VERSION ""

NS_ :

BS_:

BU_: XXX

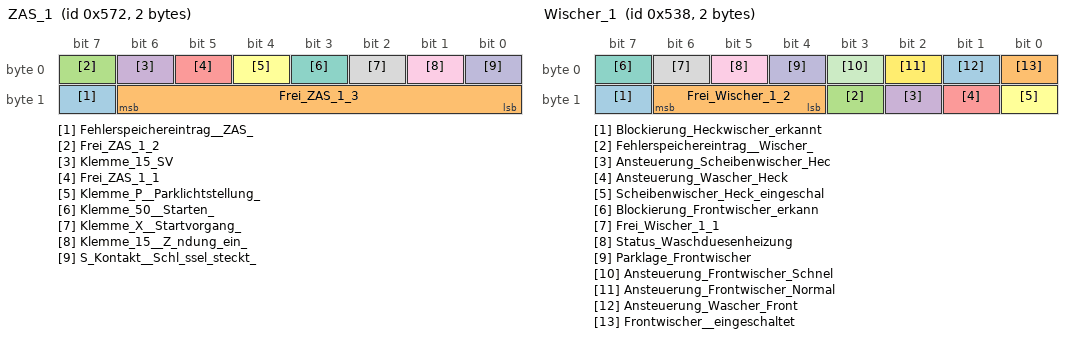
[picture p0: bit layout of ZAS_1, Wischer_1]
BO_ 1394 ZAS_1: 2 XXX
 SG_ Fehlerspeichereintrag__ZAS_ : 15|1@1+ (1,0) [0|0] "" XXX
 SG_ Frei_ZAS_1_3 : 8|7@1+ (1,0) [0|0] "" XXX
 SG_ Frei_ZAS_1_2 : 7|1@1+ (1,0) [0|0] "" XXX
 SG_ Klemme_15_SV : 6|1@1+ (1,0) [0|0] "" XXX
 SG_ Frei_ZAS_1_1 : 5|1@1+ (1,0) [0|0] "" XXX
 SG_ Klemme_P__Parklichtstellung_ : 4|1@1+ (1,0) [0|0] "" XXX
 SG_ Klemme_50__Starten_ : 3|1@1+ (1,0) [0|0] "" XXX
 SG_ Klemme_X__Startvorgang_ : 2|1@1+ (1,0) [0|0] "" XXX
 SG_ Klemme_15__Z_ndung_ein_ : 1|1@1+ (1,0) [0|0] "" XXX
 SG_ S_Kontakt__Schl_ssel_steckt_ : 0|1@1+ (1,0) [0|0] "" XXX

BO_ 1336 Wischer_1: 2 XXX
 SG_ Blockierung_Heckwischer_erkannt : 15|1@1+ (1,0) [0|0] "" XXX
 SG_ Frei_Wischer_1_2 : 12|3@1+ (1,0) [0|0] "" XXX
 SG_ Fehlerspeichereintrag__Wischer_ : 11|1@1+ (1,0) [0|0] "" XXX
 SG_ Ansteuerung_Scheibenwischer_Hec : 10|1@1+ (1,0) [0|0] "" XXX
 SG_ Ansteuerung_Wascher_Heck : 9|1@1+ (1,0) [0|0] "" XXX
 SG_ Scheibenwischer_Heck_eingeschal : 8|1@1+ (1,0) [0|0] "" XXX
 SG_ Blockierung_Frontwischer_erkann : 7|1@1+ (1,0) [0|0] "" XXX
 SG_ Frei_Wischer_1_1 : 6|1@1+ (1,0) [0|0] "" XXX
 SG_ Status_Waschduesenheizung : 5|1@1+ (1,0) [0|0] "" XXX
 SG_ Parklage_Frontwischer : 4|1@1+ (1,0) [0|0] "" XXX
 SG_ Ansteuerung_Frontwischer_Schnel : 3|1@1+ (1,0) [0|0] "" XXX
 SG_ Ansteuerung_Frontwischer_Normal : 2|1@1+ (1,0) [0|0] "" XXX
 SG_ Ansteuerung_Wascher_Front : 1|1@1+ (1,0) [0|0] "" XXX
 SG_ Frontwischer__eingeschaltet : 0|1@1+ (1,0) [0|0] "" XXX

BO_ 1464 WFS_1: 2 XXX
 SG_ WFS_Textbits : 8|8@1+ (1,0) [0|0] "" XXX
 SG_ Frei_WFS_1_1 : 1|7@1+ (1,0) [0|0] "" XXX
 SG_ WFS_LED : 0|1@1+ (1,0) [0|0] "" XXX

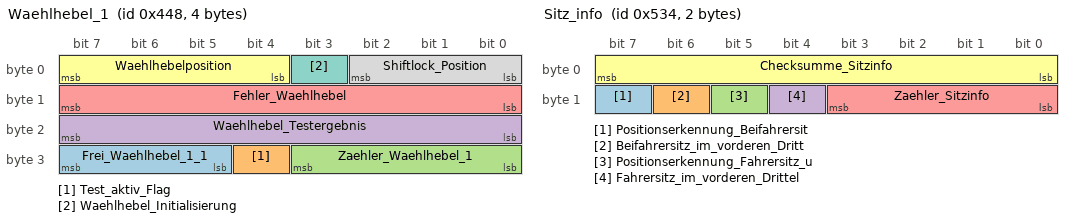
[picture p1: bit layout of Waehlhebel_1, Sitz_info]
BO_ 1096 Waehlhebel_1: 4 XXX
 SG_ Frei_Waehlhebel_1_1 : 29|3@1+ (1,0) [0|0] "" XXX
 SG_ Test_aktiv_Flag : 28|1@1+ (1,0) [0|0] "" XXX
 SG_ Zaehler_Waehlhebel_1 : 24|4@1+ (1,0) [0|15] "" XXX
 SG_ Waehlhebel_Testergebnis : 16|8@1+ (1,0) [0|255] "" XXX
 SG_ Fehler_Waehlhebel : 8|8@1+ (1,0) [0|0] "" XXX
 SG_ Waehlhebelposition : 4|4@1+ (1,0) [0|0] "" XXX
 SG_ Waehlhebel_Initialisierung : 3|1@1+ (1,0) [0|0] "" XXX
 SG_ Shiftlock_Position : 0|3@1+ (1,0) [0|0] "" XXX

BO_ 1496 Verbauliste_1: 8 XXX
 SG_ TV_Tuner : 63|1@1+ (1,0) [0|0] "" XXX
 SG_ DSP : 62|1@1+ (1,0) [0|0] "" XXX
 SG_ CD_Wechsler : 61|1@1+ (1,0) [0|0] "" XXX
 SG_ Spracheingabe : 60|1@1+ (1,0) [0|0] "" XXX
 SG_ Telematik : 59|1@1+ (1,0) [0|0] "" XXX
 SG_ Navigation : 58|1@1+ (1,0) [0|0] "" XXX
 SG_ Telefon : 57|1@1+ (1,0) [0|0] "" XXX
 SG_ Radio : 56|1@1+ (1,0) [0|0] "" XXX
 SG_ MMI_vorne : 55|1@1+ (1,0) [0|0] "" XXX
 SG_ MMI_hinten : 54|1@1+ (1,0) [0|0] "" XXX
 SG_ Frei_Verbauliste_1_11 : 53|1@1+ (1,0) [0|0] "" XXX
 SG_ Klimabedienteil_HL : 52|1@1+ (1,0) [0|0] "" XXX
 SG_ Frei_Verbauliste_1_10 : 50|2@1+ (1,0) [0|0] "" XXX
 SG_ Tankgeber : 49|1@1+ (1,0) [0|0] "" XXX
 SG_ Assistenzfahrlicht : 48|1@1+ (1,0) [0|0] "" XXX
 SG_ Memory_hinter_Fahrer : 47|1@1+ (1,0) [0|0] "" XXX
 SG_ Sitzmemory_hinten : 46|1@1+ (1,0) [0|0] "" XXX
 SG_ Sitzmemory_Beifahrer : 45|1@1+ (1,0) [0|0] "" XXX
 SG_ Anh_ngersteuergeraet : 44|1@1+ (1,0) [0|0] "" XXX
 SG_ Energiemanagement : 43|1@1+ (1,0) [0|0] "" XXX
 SG_ Wischermodul : 42|1@1+ (1,0) [0|0] "" XXX
 SG_ EZS___Kessy__Komfort_ : 41|1@1+ (1,0) [0|0] "" XXX
 SG_ Verdecksteuergeraet : 40|1@1+ (1,0) [0|0] "" XXX
 SG_ Standheizung : 39|1@1+ (1,0) [0|0] "" XXX
 SG_ Frei_Verbauliste_1_9 : 38|1@1+ (1,0) [0|0] "" XXX
 SG_ Einparkhilfe : 37|1@1+ (1,0) [0|0] "" XXX
 SG_ Klimasteuergeraet_Komfort : 36|1@1+ (1,0) [0|0] "" XXX
 SG_ Gateway : 35|1@1+ (1,0) [0|0] "" XXX
 SG_ Lenksaeulenmodul : 34|1@1+ (1,0) [0|0] "" XXX
 SG_ Reifendruck : 33|1@1+ (1,0) [0|0] "" XXX
 SG_ Kombiinstrument_Komfort : 32|1@1+ (1,0) [0|0] "" XXX
 SG_ Dachmodul : 31|1@1+ (1,0) [0|0] "" XXX
 SG_ Memory : 30|1@1+ (1,0) [0|0] "" XXX
 SG_ TSG_HR : 29|1@1+ (1,0) [0|0] "" XXX
 SG_ TSG_HL : 28|1@1+ (1,0) [0|0] "" XXX
 SG_ TSG_BT : 27|1@1+ (1,0) [0|0] "" XXX
 SG_ TSG_FT : 26|1@1+ (1,0) [0|0] "" XXX
 SG_ ZKE : 25|1@1+ (1,0) [0|0] "" XXX
 SG_ BSG_Komfort : 24|1@1+ (1,0) [0|0] "" XXX
 SG_ Frei_Verbauliste_1_8 : 19|5@1+ (1,0) [0|0] "" XXX
 SG_ Stabi_Entkopplung : 18|1@1+ (1,0) [0|0] "" XXX
 SG_ Waehlhebel : 17|1@1+ (1,0) [0|0] "" XXX
 SG_ Batteriemanager : 16|1@1+ (1,0) [0|0] "" XXX
 SG_ Daempfer_SG : 15|1@1+ (1,0) [0|0] "" XXX
 SG_ Niveauregulierung : 14|1@1+ (1,0) [0|0] "" XXX
 SG_ EZS___Kessy__Antrieb_ : 13|1@1+ (1,0) [0|0] "" XXX
 SG_ Bremsbooster : 12|1@1+ (1,0) [0|0] "" XXX
 SG_ Lenkhilfe : 11|1@1+ (1,0) [0|0] "" XXX
 SG_ Kombi_Antrieb : 10|1@1+ (1,0) [0|0] "" XXX
 SG_ Einspritzpumpe : 9|1@1+ (1,0) [0|0] "" XXX
 SG_ Lenkwinkel : 8|1@1+ (1,0) [0|0] "" XXX
 SG_ Allrad : 7|1@1+ (1,0) [0|0] "" XXX
 SG_ BSG_Antrieb : 6|1@1+ (1,0) [0|0] "" XXX
 SG_ ADR : 5|1@1+ (1,0) [0|0] "" XXX
 SG_ Airbag : 4|1@1+ (1,0) [0|0] "" XXX
 SG_ Climatronic_Antrieb : 3|1@1+ (1,0) [0|0] "" XXX
 SG_ ABS : 2|1@1+ (1,0) [0|0] "" XXX
 SG_ Getriebesteuergeraet : 1|1@1+ (1,0) [0|0] "" XXX
 SG_ Motorsteuergeraet : 0|1@1+ (1,0) [0|0] "" XXX

BO_ 1488 Systeminfo_1: 6 XXX
 SG_ CAN_Stand_4_1_Antrieb_Daten_Hau : 44|4@1+ (1,0) [0|15] "" XXX
 SG_ CAN_Stand_4_1_Antrieb_Daten_Neb : 40|4@1+ (1,0) [0|15] "" XXX
 SG_ CAN_Stand_4_1_Komfort_Daten_Hau : 36|4@1+ (1,0) [0|15] "" XXX
 SG_ CAN_Stand_4_1_Komfort_Daten_Neb : 32|4@1+ (1,0) [0|15] "" XXX
 SG_ Frei_Systeminfo_1_6 : 30|1@1+ (1,0) [0|0] "" XXX
 SG_ Viertuerer : 29|1@1+ (1,0) [0|0] "" XXX
 SG_ Rechtslenker : 28|1@1+ (1,0) [0|0] "" XXX
 SG_ Fahrzeug_Index : 24|4@1+ (1,0) [0|0] "" XXX
 SG_ Fahrzeug_Generation : 20|4@1+ (1,0) [0|15] "" XXX
 SG_ Fahrzeug_Derivat : 16|4@1+ (1,0) [0|15] "" XXX
 SG_ Fahrzeug_Marke_2 : 12|4@1+ (1,0) [0|15] "" XXX
 SG_ Fahrzeug_Klasse : 8|4@1+ (1,0) [0|15] "" XXX
 SG_ Verbauinformation_gueltig : 7|1@1+ (1,0) [0|0] "" XXX
 SG_ CAN_Infotainment_verbaut : 6|1@1+ (1,0) [0|0] "" XXX
 SG_ CAN_Infotainment_in_Diagnose : 5|1@1+ (1,0) [0|0] "" XXX
 SG_ Sleep_CAN_Infotainment : 4|1@1+ (1,0) [0|0] "" XXX
 SG_ CAN_Komfort_in_Diagnose : 3|1@1+ (1,0) [0|0] "" XXX
 SG_ Sleep_CAN_Komfort : 2|1@1+ (1,0) [0|0] "" XXX
 SG_ CAN_Antrieb_in_Diagnose : 1|1@1+ (1,0) [0|0] "" XXX
 SG_ CAN_Extern_zugeschaltet : 0|1@1+ (1,0) [0|0] "" XXX

BO_ 268 Slave_1: 8 XXX
 SG_ Delta_reduziertes_Sollmoment : 48|1@1+ (1,0) [0|0] "" XXX
 SG_ Delta_Drosselklappenwinkel : 32|16@1+ (1,0) [0|0] "" XXX
 SG_ Frei_Slave_1_1 : 25|7@1+ (1,0) [0|0] "" XXX
 SG_ Delta_Zuendwinkelausgabe : 24|1@1+ (1,0) [0|0] "" XXX
 SG_ Ubat_Freigabe_DVE__Slave_ : 23|1@1+ (1,0) [0|0] "" XXX
 SG_ Drosselklappe_Sollwertbegrenzun : 22|1@1+ (1,0) [0|0] "" XXX
 SG_ Einspritzverbot_lernen__Slave_ : 21|1@1+ (1,0) [0|0] "" XXX
 SG_ Master_erkannt__Slave_ : 20|1@1+ (1,0) [0|0] "" XXX
 SG_ Fehler_Momentenausgabe : 19|1@1+ (1,0) [0|0] "" XXX
 SG_ Fehler_Getriebe_Moment : 18|1@1+ (1,0) [0|0] "" XXX
 SG_ Fehler_Bremsenbotschaft : 17|1@1+ (1,0) [0|0] "" XXX
 SG_ Indiziertes_Istmoment__Slave_ : 0|16@1+ (0.0015259,0) [0|99.998] "%" XXX
 SG_ Timeout_Bremsenbotschaft : 0|1@1+ (1,0) [0|0] "" XXX

BO_ 1332 Sitz_info: 2 XXX
 SG_ Positionserkennung_Beifahrersit : 15|1@1+ (1,0) [0|0] "" XXX
 SG_ Beifahrersitz_im_vorderen_Dritt : 14|1@1+ (1,0) [0|0] "" XXX
 SG_ Positionserkennung_Fahrersitz_u : 13|1@1+ (1,0) [0|0] "" XXX
 SG_ Fahrersitz_im_vorderen_Drittel : 12|1@1+ (1,0) [0|0] "" XXX
 SG_ Zaehler_Sitzinfo : 8|4@1+ (1,0) [0|15] "" XXX
 SG_ Checksumme_Sitzinfo : 0|8@1+ (1,0) [0|0] "" XXX

BO_ 1810 PSG_3: 2 XXX
 SG_ Selbsttestergebnis : 0|16@1+ (1,0) [0|0] "" XXX

BO_ 1298 PSG_2: 8 XXX
 SG_ RAM_Inhalt_4 : 48|16@1+ (1,0) [0|0] "" XXX
 SG_ RAM_Inhalt_3 : 32|16@1+ (1,0) [0|0] "" XXX
 SG_ RAM_Inhalt_2 : 16|16@1+ (1,0) [0|0] "" XXX
 SG_ RAM_Inhalt_1 : 0|16@1+ (1,0) [0|0] "" XXX

BO_ 274 PSG_1: 8 XXX
 SG_ Pumpentemperatur__2_1_ : 48|16@1+ (0.0625,0) [0|4096] "K" XXX
 SG_ Pumpentemperatur__3_2_2_ : 44|12@1+ (1,0) [0|0] "" XXX
 SG_ Zylinderzaehler__3_2_2_ : 43|3@1+ (1,0) [1|8] "Zaehler" XXX
 SG_ Ansteuerdauer__3_2_2_ : 32|11@1+ (0.0469,0) [0|96] "NW" XXX
 SG_ Nockenwellendrehzahl__3_2_2_ : 20|12@1+ (4,0) [0|16380] "upm" XXX
 SG_ Pumpen_Statuswort__3_2_2_ : 0|20@1+ (1,0) [0|0] "" XXX

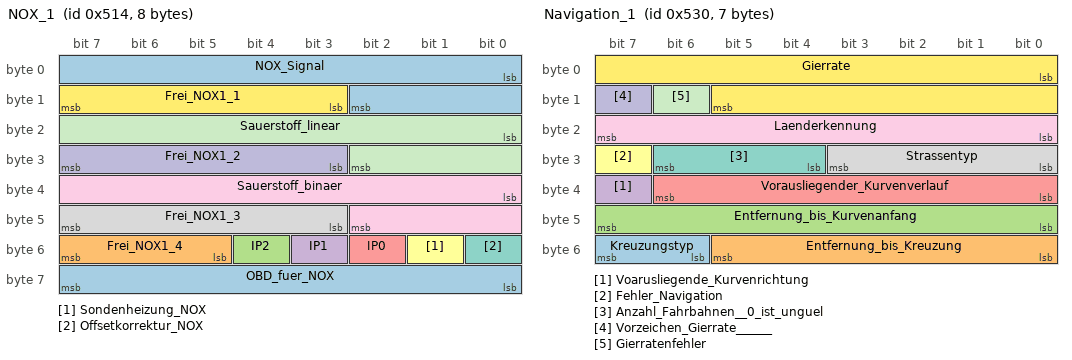
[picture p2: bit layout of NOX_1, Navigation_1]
BO_ 1300 NOX_1: 8 XXX
 SG_ OBD_fuer_NOX : 56|8@1+ (1,0) [0|0] "" XXX
 SG_ Frei_NOX1_4 : 53|3@1+ (1,0) [0|0] "" XXX
 SG_ IP2 : 52|1@1+ (1,0) [0|0] "" XXX
 SG_ IP1 : 51|1@1+ (1,0) [0|0] "" XXX
 SG_ IP0 : 50|1@1+ (1,0) [0|0] "" XXX
 SG_ Sondenheizung_NOX : 49|1@1+ (1,0) [0|0] "" XXX
 SG_ Offsetkorrektur_NOX : 48|1@1+ (1,0) [0|0] "" XXX
 SG_ Frei_NOX1_3 : 43|5@1+ (1,0) [0|0] "" XXX
 SG_ Sauerstoff_binaer : 32|11@1+ (1,-200) [-200|1847] "mV" XXX
 SG_ Frei_NOX1_2 : 27|5@1+ (1,0) [0|0] "" XXX
 SG_ Sauerstoff_linear : 16|11@1+ (1,0) [0|2047] "1000/Lambd" XXX
 SG_ Frei_NOX1_1 : 11|5@1+ (1,0) [0|0] "" XXX
 SG_ NOX_Signal : 0|11@1+ (1,0) [0|2047] "ppm" XXX

BO_ 1424 Niveau_1: 6 XXX
 SG_ Beladungszustand : 40|8@1+ (1,0) [0|253] "Zuladung" XXX
 SG_ Fehlerspeichereintrag__Niveau_1 : 39|1@1+ (1,0) [0|0] "" XXX
 SG_ Systemstatus__Niveau_1_ : 38|1@1+ (1,0) [0|0] "" XXX
 SG_ Reserve_Fahrzeugart : 37|1@1+ (1,0) [0|0] "" XXX
 SG_ Fahrzeugart_Niveau : 36|1@1+ (1,0) [0|0] "" XXX
 SG_ Textbits__Niveau_1_ : 32|4@1+ (1,0) [0|0] "" XXX
 SG_ Verstellung_HL : 31|1@1+ (1,0) [0|0] "" XXX
 SG_ Verstellung_HR : 30|1@1+ (1,0) [0|0] "" XXX
 SG_ Verstellung_VL : 29|1@1+ (1,0) [0|0] "" XXX
 SG_ Verstellung_VR : 28|1@1+ (1,0) [0|0] "" XXX
 SG_ Absenkung_Fahrzeug : 27|1@1+ (1,0) [0|0] "" XXX
 SG_ Anhebung_Fahrzeug : 26|1@1+ (1,0) [0|0] "" XXX
 SG_ Verstellung_aktiv : 25|1@1+ (1,0) [0|0] "" XXX
 SG_ Kompressorlauf_in_Kuerze : 24|1@1+ (1,0) [0|0] "" XXX
 SG_ Frei_Niveau_1_5 : 23|1@1+ (1,0) [0|0] "" XXX
 SG_ Taster_Niveau : 22|1@1+ (1,0) [0|0] "" XXX
 SG_ Parkniveau : 21|1@1+ (1,0) [0|0] "" XXX
 SG_ Zwischenniveau : 20|1@1+ (1,0) [0|0] "" XXX
 SG_ Niveaustati : 16|4@1+ (1,0) [0|0] "" XXX
 SG_ MSG_Einschraenkung : 15|1@1+ (1,0) [0|0] "" XXX
 SG_ ESP_Beeinflussung : 14|1@1+ (1,0) [0|0] "" XXX
 SG_ Warnlampe_Niveau_1 : 13|1@1+ (1,0) [0|0] "" XXX
 SG_ Frei_Niveau_1_1 : 12|1@1+ (1,0) [0|0] "" XXX
 SG_ Zaehler_Niveau_1 : 8|4@1+ (1,0) [0|15] "Zaehler" XXX
 SG_ Checksumme_Niveau_1 : 0|8@1+ (1,0) [0|0] "" XXX

BO_ 1328 Navigation_1: 7 XXX
 SG_ Kreuzungstyp : 54|2@1+ (1,0) [0|3] "" XXX
 SG_ Entfernung_bis_Kreuzung : 48|6@1+ (5,0) [0|315] "m" XXX
 SG_ Entfernung_bis_Kurvenanfang : 40|8@1+ (1,0) [0|255] "m" XXX
 SG_ Voarusliegende_Kurvenrichtung : 39|1@1+ (1,0) [0|0] "" XXX
 SG_ Vorausliegender_Kurvenverlauf : 32|7@1+ (50,0) [0|6350] "m" XXX
 SG_ Fehler_Navigation : 31|1@1+ (1,0) [0|0] "" XXX
 SG_ Anzahl_Fahrbahnen__0_ist_unguel : 28|3@1+ (1,0) [1|7] "" XXX
 SG_ Strassentyp : 24|4@1+ (1,0) [0|15] "" XXX
 SG_ Laenderkennung : 16|8@1+ (1,0) [0|0] "" XXX
 SG_ Vorzeichen_Gierrate______ : 15|1@1+ (1,0) [0|0] "" XXX
 SG_ Gierratenfehler : 14|1@1+ (1,0) [0|0] "" XXX
 SG_ Gierrate : 0|14@1+ (0.01,0) [0|100] "deg/sek" XXX

BO_ 1792 MSG_3: 3 XXX
 SG_ MSG_Konfiguration : 16|8@1+ (1,0) [0|0] "" XXX
 SG_ Lage_des_OT_Impuls : 0|16@1+ (0.01172,-384) [-384|384] "KW" XXX

BO_ 1280 MSG_2: 8 XXX
 SG_ RAM_Adresse_4 : 48|16@1+ (1,0) [0|0] "" XXX
 SG_ RAM_Adresse_3 : 32|16@1+ (1,0) [0|0] "" XXX
 SG_ RAM_Adresse_2 : 16|16@1+ (1,0) [0|0] "" XXX
 SG_ Ram_Adresse_1 : 0|16@1+ (1,0) [0|0] "" XXX

BO_ 256 MSG_1: 8 XXX
 SG_ Kurbelwellendrehzahl__3_2_2_ : 56|8@1+ (1,0) [0|0] "" XXX
 SG_ Soll_Foerderbeginn_KW__3_2_2_ : 40|16@1+ (0.01172,-384) [-384|384] "KW" XXX
 SG_ Soll_Foerderbeginn_NW__3_2_2_ : 28|12@1+ (0.01172,0) [0|768] "degNW" XXX
 SG_ Soll_Voreinspritzung : 16|12@1+ (1,0) [0|0] "" XXX
 SG_ Soll_Einspritzmenge : 0|16@1+ (0.03125,0) [0|2047] "mg/H" XXX

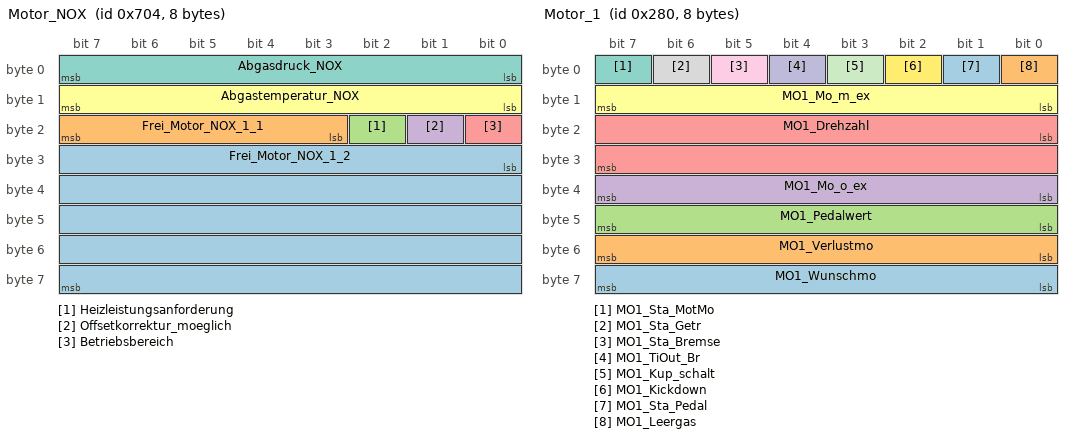
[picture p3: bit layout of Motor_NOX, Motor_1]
BO_ 1796 Motor_NOX: 8 XXX
 SG_ Frei_Motor_NOX_1_2 : 24|40@1+ (1,0) [0|0] "" XXX
 SG_ Frei_Motor_NOX_1_1 : 19|5@1+ (1,0) [0|0] "" XXX
 SG_ Heizleistungsanforderung : 18|1@1+ (1,0) [0|0] "" XXX
 SG_ Offsetkorrektur_moeglich : 17|1@1+ (1,0) [0|0] "" XXX
 SG_ Betriebsbereich : 16|1@1+ (1,0) [0|0] "" XXX
 SG_ Abgastemperatur_NOX : 8|8@1+ (5,-40) [-40|1230] "C" XXX
 SG_ Abgasdruck_NOX : 0|8@1+ (5,600) [600|1870] "mbar" XXX

BO_ 900 Motor_Momente: 8 XXX
 SG_ Momentenangaben_ungenau__Moment : 35|2@1+ (1,0) [0|0] "" XXX

BO_ 1408 Motor_Flexia: 8 XXX
 SG_ Ansaugsystem m0 : 63|1@1+ (1,0) [0|0] "" XXX
 SG_ Hubraum m0 : 56|7@1+ (0.1,0) [0|12.7] "l" XXX
 SG_ Steigung_der_Befuellungskennlin m1 : 56|8@1+ (0.001,0) [0|0.255] "l/mm" XXX
 SG_ Anzahl_Zylinder m0 : 52|4@1+ (1,0) [0|15] "Vent./Zyl." XXX
 SG_ Bewertungsfaktor_Russindex_Turb m1 : 50|6@1+ (0.1,0) [0|6.3] "" XXX
 SG_ Anzahl_Ventile m0 : 49|3@1+ (1,0) [0|7] "Vent./Zyl." XXX
 SG_ Bewertungsfaktor_Verschleissind m1 : 44|6@1+ (0.1,0) [0|6.3] "" XXX
 SG_ Hersteller_Code m1 : 40|4@1+ (1,0) [0|15] "" XXX
 SG_ Motorleistung m0 : 40|9@1+ (1,0) [0|512] "KW" XXX
 SG_ Max_Drehmoment m0 : 32|8@1+ (10,0) [0|2550] "Nm" XXX
 SG_ Normierter_Verbrauch m1 : 32|8@1+ (10,0) [0|2550] "l/Zyl." XXX
 SG_ Oelniveauschwelle m1 : 24|8@1+ (0.25,0) [0|63.75] "cm" XXX
 SG_ Drehzahl_MaxNorm m0 : 24|8@1+ (100,0) [0|25500] "U/min" XXX
 SG_ Verschleissindex : 16|8@1+ (1,0) [0|254] "" XXX
 SG_ Russindex : 8|8@1+ (1,0) [0|254] "" XXX
 SG_ Verbrennungsart : 7|1@1+ (1,0) [0|0] "" XXX
 SG_ Frei_Motor_Flexia_1 : 6|1@1+ (1,0) [0|0] "" XXX
 SG_ Warm_Up_Cycle : 5|1@1+ (1,0) [0|0] "" XXX
 SG_ Driving_Cycle : 4|1@1+ (1,0) [0|0] "" XXX
 SG_ Zaehler_Motor_Flexia : 1|3@1+ (1,0) [0|15] "" XXX
 SG_ Multiplex_Schalter_Motor_Flexia M : 0|1@1+ (1,0) [0|0] "" XXX

BO_ 1160 Motor_6: 8 XXX
 SG_ MO6_Zaehler M : 60|4@1+ (1,0) [0|15] "" XXX
 SG_ MO6_FF_Mux00 m0 : 48|8@1+ (0.39215686,0) [0|100] "%" XXX
 SG_ MO6_FF_Mux01 m1 : 48|8@1+ (0.39215686,0) [0|100] "%" XXX
 SG_ MO6_FF_Mux02 m2 : 48|8@1+ (1,-40) [-40|215] "C" XXX
 SG_ MO6_FF_Mux03 m3 : 48|8@1+ (3.1372549,0) [0|800] "%" XXX
 SG_ MO6_FF_Mux04 m4 : 48|8@1+ (0.39215686,0) [0|100] "%" XXX
 SG_ MO6_Checksum : 0|8@1+ (1,0) [0|255] "" XXX
 SG_ MO6_SollM_Getr : 8|8@1+ (0.39,0) [0|99.06] "%" XXX
 SG_ MO6_Ist_Moment : 16|8@1+ (0.39,0) [0|99.06] "%" XXX
 SG_ MO6_Hoeheninfo : 24|8@1+ (0.0078125,0) [0|2] "" XXX
 SG_ MO6_GRA_Soll : 32|8@1+ (0.024,-3.984) [-3.984|2.112] "m/s2" XXX
 SG_ MO6_MomIntGeOng : 40|8@1+ (0.39215686,0) [0|100] "%" XXX
 SG_ MO6_Freigabe_GRA : 56|1@1+ (1,0) [0|1] "" XXX
 SG_ MO6_Schutz_Toel : 57|1@1+ (1,0) [0|1] "" XXX
 SG_ MO6_Luftpfad_akt : 58|1@1+ (1,0) [0|1] "" XXX
 SG_ MO6_RegPartikel : 59|1@1+ (1,0) [0|1] "" XXX

BO_ 1162 Motor_8: 8 XXX
 SG_ MO8_Checksumme : 0|8@1+ (1,0) [0|255] "" XXX
 SG_ MO8_AnzeigeDZ : 8|12@1+ (3,0) [0|12282] "rpm" XXX
 SG_ MO_Effizienzmodus : 20|1@1+ (1,0) [0|1] "" XXX
 SG_ MO8_SGT_Soundakt : 21|1@1+ (1,0) [0|1] "" XXX
 SG_ MO8_Spoiler_ausf : 22|1@1+ (1,0) [0|1] "" XXX
 SG_ MO8_Sportschalter : 23|1@1+ (1,0) [0|1] "" XXX
 SG_ MO8_LampeDZBegr : 24|1@1+ (1,0) [0|1] "" XXX
 SG_ MO8_Enable_Oeldr_Motor : 25|1@1+ (1,0) [0|1] "" XXX
 SG_ MO8_Oeldr_Warn_Motor : 26|1@1+ (1,0) [0|1] "" XXX
 SG_ MO8_Avus_Motorschutz : 27|2@1+ (1,0) [0|3] "" XXX
 SG_ MO8_Anzeigecode : 29|1@1+ (1,0) [0|1] "" XXX
 SG_ MO_P_verriegelt : 30|2@1+ (1,0) [0|3] "" XXX
 SG_ MO8_GRA_v_Wunsch : 32|9@1+ (1,0) [0|511] "km/h" XXX
 SG_ MO_Schaltempf_verfbar : 41|1@1+ (1,0) [0|1] "" XXX
 SG_ MO8_Trailing_ZWP : 42|6@1+ (15,0) [0|945] "s" XXX
 SG_ MO_Istgang : 48|4@1+ (1,0) [0|15] "" XXX
 SG_ MO_Sollgang : 52|4@1+ (1,0) [0|15] "" XXX
 SG_ MO8_Zaehler : 60|4@1+ (1,0) [0|15] "" XXX

BO_ 1152 Motor_5: 8 Motor
 SG_ MO5_Mp_Code M : 6|2@1+ (1,0) [0|3] "" Gateway
 SG_ MO5_max_Moment m0 : 0|6@1+ (10,0) [0|630] "Nm" Gateway
 SG_ MO5_Drehzahl m1 : 0|6@1+ (100,0) [0|6300] "U/min" Gateway
 SG_ MO5_Motortyp m2 : 0|6@1+ (1,0) [0|63] "" Gateway
 SG_ MO5_Abgastyp m3 : 0|1@1+ (1,0) [0|1] "" Gateway
 SG_ MO5_Abgastyp2 m3 : 1|1@1+ (1,0) [0|1] "" Gateway
 SG_ MO5_Abgastyp3 m3 : 2|1@1+ (1,0) [0|1] "" Gateway
 SG_ OBD_Kaltstart_Denominator m3 : 3|1@1+ (1,0) [0|1] "" Gateway
 SG_ OBD_Minimum_Trip m3 : 4|1@1+ (1,0) [0|1] "" Gateway
 SG_ MO5_DPF_reg m3 : 5|1@1+ (1,0) [0|1] "" Gateway
 SG_ MO5_Vorgluehen : 9|1@1+ (1,0) [0|1] "" KOMBI
 SG_ MO5_E_Gas : 10|1@1+ (1,0) [0|1] "" KOMBI
 SG_ MO5_OBD_2 : 11|1@1+ (1,0) [0|1] "" KOMBI
 SG_ MO5_Heissl : 12|1@1+ (1,0) [0|1] "" KOMBI
 SG_ MO5_KlimaKompr : 13|1@1+ (1,0) [0|1] "" Gateway
 SG_ MO5_Feld_kuehl : 14|1@1+ (1,0) [0|1] "" Gateway
 SG_ MO5_KliKo_Red : 15|1@1+ (1,0) [0|1] "" Gateway
 SG_ MO5_Verbrauch : 16|15@1+ (1,0) [0|32767] "µl" KOMBI
 SG_ MO5_UeberlVerb : 31|1@1+ (1,0) [0|1] "" KOMBI
 SG_ MO5_Luefter : 32|8@1+ (0.4,0) [0|101.6] "%" Gateway
 SG_ MO5_HLeuchte : 40|1@1+ (1,0) [0|1] "" KOMBI
 SG_ MO5_PartikelLamp : 41|1@1+ (1,0) [0|1] "" KOMBI
 SG_ MO5_Sta_BKU : 42|1@1+ (1,0) [0|1] "" Gateway
 SG_ MO5_TypStartSteu : 43|1@1+ (1,0) [0|1] "" Gateway
 SG_ MO5_TDE_Lampe : 44|1@1+ (1,0) [0|1] "" KOMBI
 SG_ MO5_TDE_Text : 45|1@1+ (1,0) [0|1] "" KOMBI
 SG_ MO5_DZM_Daempf : 46|1@1+ (1,0) [0|1] "" KOMBI
 SG_ MO5_Interlock : 47|1@1+ (1,0) [0|1] "" Gateway
 SG_ MO5_Start : 48|1@1+ (1,0) [0|1] "" Gateway
 SG_ MO5_Anlasser : 49|1@1+ (1,0) [0|1] "" Gateway
 SG_ MO5_GRA_Hauptsch : 50|1@1+ (1,0) [0|1] "" Gateway
 SG_ MO5_Momente : 51|1@1+ (1,0) [0|1] "" Gateway
 SG_ MO5_Motortext1 : 52|1@1+ (1,0) [0|1] "" KOMBI
 SG_ MO5_Motortext2 : 53|1@1+ (1,0) [0|1] "" KOMBI
 SG_ MO5_Motortext3 : 54|1@1+ (1,0) [0|1] "" KOMBI
 SG_ MO5_Motortext4 : 55|1@1+ (1,0) [0|1] "" KOMBI
 SG_ CHECKSUM : 56|8@1+ (1,0) [0|255] "" Gateway

BO_ 896 Motor_3: 8 Motor
 SG_ MO3_Vorgluehen : 0|1@1+ (1,0) [0|1] "" Gateway
 SG_ MO3_Prio_Dz : 1|1@1+ (1,0) [0|1] "" Transmission
 SG_ MO_Schalter_StartStopp : 2|1@1+ (1,0) [0|1] "" Gateway
 SG_ MO3_Winterprg : 3|1@1+ (1,0) [0|1] "" Transmission
 SG_ MO3_Sta_Pedal : 4|1@1+ (1,0) [0|1] "" Gateway
 SG_ MO3_Sta_FPG M : 5|1@1+ (1,0) [0|1] "" ESP
 SG_ MO3_Sign_FPG m1 : 6|1@1+ (1,0) [0|1] "" ESP
 SG_ MO3_Sta_Temp : 7|1@1+ (1,0) [0|1] "" Gateway
 SG_ MO3_Offsentemp : 8|8@1+ (0.75,-48) [-48|142.5] "°C" Gateway
 SG_ MO3_Pedalwert : 16|8@1+ (0.4,0) [0|101.6] "%" Gateway
 SG_ MO3_Rad_Wu_Mo : 24|12@1+ (0.39,0) [0|1596.66] "%" Transmission
 SG_ MO3_Vorz_RadWu : 36|1@1+ (1,0) [0|1] "" Transmission
 SG_ MO3_Freigabe_Segeln : 37|1@1+ (1,0) [0|1] "" Transmission
 SG_ MO_StartStopp_StoppVorbereitung : 38|1@1+ (1,0) [0|1] "" Gateway
 SG_ MO3_Dz_Beeinfl : 40|8@1+ (0.39,0) [0|99.45] "%" Transmission
 SG_ MO3_WunschDz : 48|8@1+ (25,0) [0|6350] "U/min" Transmission
 SG_ MO3_DKW m0 : 56|8@1+ (0.4,0) [0|101.6] "%" Gateway
 SG_ MO3_FPGradient m1 : 56|8@1+ (25,0) [0|6350] "%/s" ESP

BO_ 648 Motor_2: 8 Motor
 SG_ MO2_Mp_Code m : 6|2@1+ (1,0) [0|3] "" Gateway
 SG_ MO2_Getr_Code m2 : 0|6@1+ (1,0) [0|63] "" Gateway
 SG_ MO2_max_Mo m3 : 0|6@1+ (10,0) [0|630] "Nm" Gateway
 SG_ MO2_CAN_Vers m0 : 0|6@1+ (1,0) [0|63] "" Gateway
 SG_ MO2_Motor_Code m1 : 0|6@1+ (1,0) [0|63] "" Gateway
 SG_ MO2_Kuehlm_T : 8|8@1+ (0.75,-48) [-47.25|142.5] "°C" Gateway
 SG_ MO2_BLS : 16|1@1+ (1,0) [0|1] "" Gateway
 SG_ MO2_BTS : 17|1@1+ (1,0) [0|1] "" Gateway
 SG_ MO2_Sta_Kuehlm : 18|1@1+ (1,0) [0|1] "" Gateway
 SG_ MO2_Sta_Klima : 19|1@1+ (1,0) [0|1] "" Gateway
 SG_ MO2_Sta_No_Bet : 20|1@1+ (1,0) [0|1] "" Gateway
 SG_ MO2_Status_TSK : 21|1@1+ (1,0) [0|1] "" Gateway
 SG_ MO2_Sta_GRA : 22|2@1+ (1,0) [0|3] "" ACC,GRA
 SG_ TSK_Limiter_ausgewaehlt : 25|1@1+ (1,0) [0|1] "" ACC,GRA
 SG_ MO2_GRAregelt : 26|1@1+ (1,0) [0|1] "" Gateway
 SG_ MO2_Sport_Error : 27|1@1+ (1,0) [0|1] "" Gateway
 SG_ MO2_OffRoad : 28|1@1+ (1,0) [0|1] "" Gateway
 SG_ MO2_RME_Gehalt : 29|3@1+ (12.5,0) [0|75] "%" Gateway
 SG_ MO2_GRA_Soll : 32|8@1+ (1.28,0) [0|325.12] "km/h" ACC,GRA
 SG_ MO2_LL_Solldz : 40|8@1+ (10,0) [0|2540] "1/min" Gateway
 SG_ MO2_Begr_Mo : 48|8@1+ (0.39,0) [0|99.06] "%" Gateway
 SG_ MO2_Mo_ZWR : 56|8@1+ (0.39,0) [0|99.06] "%" Gateway

BO_ 1416 Motor_7: 8 XXX
 SG_ MO7_LL_Solldz : 0|1@1+ (1,0) [0|1] "" XXX
 SG_ MO7_Fehler_VBegr : 1|1@1+ (1,0) [0|1] "" XXX
 SG_ MO7_Sta_VBegr : 2|1@1+ (1,0) [0|1] "" XXX
 SG_ MO7_Fehlereintr : 3|1@1+ (1,0) [0|1] "" XXX
 SG_ MO7_StaOeltemp : 4|1@1+ (1,0) [0|1] "" XXX
 SG_ MO7_Sta_PTC : 5|3@1+ (1,0) [0|7] "" XXX
 SG_ MO7_DFM : 8|8@1+ (0.4,0) [0|101.6] "%" XXX
 SG_ MO7_Hoeheninfo : 16|8@1+ (0.0078125,0) [0|2] "" XXX
 SG_ MO7_Gradient_Dz : 24|7@1+ (1,0) [0|126] "rpm" XXX
 SG_ MO7_GradientVorz : 31|1@1+ (1,0) [0|1] "" XXX
 SG_ MO7_Ladedruckneu : 32|8@1+ (0.02,0) [0|5.08] "bar" XXX
 SG_ MO7_GenLdResp : 40|2@1+ (3,0) [0|9] "s" XXX
 SG_ MO7_PTC_bereit : 42|2@1+ (1,0) [0|3] "" XXX
 SG_ MO7_Mot_weckfaehig : 44|1@1+ (1,0) [0|1] "" XXX
 SG_ MO7_Zus_Kuehl : 45|1@1+ (1,0) [0|1] "" XXX
 SG_ MO7_SleepInd : 46|1@1+ (1,0) [0|1] "" XXX
 SG_ MO7_RueckLLDz : 47|1@1+ (1,0) [0|1] "" XXX
 SG_ MO7_Lastabwurf : 48|2@1+ (1,0) [0|3] "" XXX
 SG_ MO7_Gen_ein : 50|1@1+ (1,0) [0|1] "" XXX
 SG_ MO7_Lastabw_Heiz : 51|1@1+ (1,0) [0|1] "" XXX
 SG_ MO7_StaGluehk : 52|4@1+ (8,0) [0|112] "%" XXX
 SG_ MO7_Oeltemp : 56|8@1+ (1,-60) [-60|194] "C" XXX

BO_ 1450 Motor_13: 8 XXX
 SG_ MO_NMAX_Schaltanzeige : 0|9@1+ (25,0) [0|12775] "rpm" XXX
 SG_ MO_Ethanol_BS_Texte : 9|3@1+ (1,0) [0|7] "" XXX
 SG_ MO_Heizungspumpenansteuerung : 12|4@1+ (10,0) [0|100] "%" XXX
 SG_ MO_Trailingzeit_Heizungspumpe : 16|6@1+ (15,0) [0|945] "s" XXX
 SG_ MO_Absperrventil_oeffnen : 22|2@1+ (1,0) [0|3] "" XXX
 SG_ MO_activees_Getriebeheizen : 24|1@1+ (1,0) [0|1] "" XXX
 SG_ MO_Getriebe_kuehlen : 25|1@1+ (1,0) [0|1] "" XXX
 SG_ MO_Zustand_HWP : 26|2@1+ (1,0) [0|3] "" XXX
 SG_ MO_BKV_Unterdruckwarnung : 28|1@1+ (1,0) [0|1] "" XXX
 SG_ MO_StartStopp_Codiert : 29|1@1+ (1,0) [0|1] "" XXX
 SG_ MO_Zylinderabschaltung : 30|2@1+ (1,0) [0|3] "" XXX
 SG_ MO_Heizstrom_SCR : 32|6@1+ (1,0) [0|62] "A" XXX
 SG_ MO_Heizstrom_EKAT : 38|7@1+ (1,0) [0|126] "A" XXX
 SG_ MO_Tankklappenstatus : 45|3@1+ (1,0) [0|7] "" XXX
 SG_ MO_Tankklappensteuerung : 48|2@1+ (1,0) [0|3] "" XXX
 SG_ MO_Zylabsch_Texte_02 : 50|4@1+ (1,0) [0|15] "" XXX
 SG_ MO_EFLEX_Lampe : 54|2@1+ (1,0) [0|3] "" XXX
 SG_ MO_Testmode_AG : 56|1@1+ (1,0) [0|1] "" XXX
 SG_ MO_Ext_E_Fahrt_active : 57|1@1+ (1,0) [0|1] "" XXX
 SG_ MO_E85_WU_Lampe : 58|1@1+ (1,0) [0|1] "" XXX
 SG_ MO_E85_WU_Texte : 59|1@1+ (1,0) [0|1] "" XXX
 SG_ MO_Zylabsch_Texte : 60|2@1+ (1,0) [0|3] "" XXX
 SG_ MO_E85_BS_Texte : 62|2@1+ (1,0) [0|3] "" XXX

BO_ 1420 Motor_10: 8 XXX
 SG_ M10_Anzeige : 0|4@1+ (1,0) [0|15] "" XXX
 SG_ M10_Anf_Kl75 : 4|1@1+ (1,0) [0|1] "" XXX
 SG_ MSG_Remotestart_Betrieb : 5|1@1+ (1,0) [0|1] "" XXX
 SG_ M10_SpannungsAnf : 6|1@1+ (1,0) [0|1] "" XXX
 SG_ M10_UDruckDyn : 7|1@1+ (1,0) [0|1] "" XXX
 SG_ M10_Status_StSt : 8|2@1+ (1,0) [0|3] "" XXX
 SG_ M10_MotorStopp : 10|1@1+ (1,0) [0|1] "" XXX
 SG_ M10_Wiederstart : 11|1@1+ (1,0) [0|1] "" XXX
 SG_ M10_Schubabschaltung : 12|1@1+ (1,0) [0|1] "" XXX
 SG_ M10_Druck_err_gem : 13|1@1+ (1,0) [0|1] "" XXX
 SG_ M10_Freigabe_Reku : 14|2@1+ (1,0) [0|3] "" XXX
 SG_ M10_rel_Saugrohrdruck : 16|6@1+ (18,0) [0|1116] "mbar" XXX
 SG_ M10_Fahrbereitschaft : 22|1@1+ (1,0) [0|1] "" XXX
 SG_ M10_Hybrid : 23|1@1+ (1,0) [0|1] "" XXX
 SG_ M10_EM_active : 24|1@1+ (1,0) [0|1] "" XXX
 SG_ M10_VM_active : 25|1@1+ (1,0) [0|1] "" XXX
 SG_ M10_HYB_Bereitlampe : 26|1@1+ (1,0) [0|1] "" XXX
 SG_ M10_HYB_Warnlampe : 27|1@1+ (1,0) [0|1] "" XXX
 SG_ M10_HYB_Fehlerlampe : 28|1@1+ (1,0) [0|1] "" XXX
 SG_ M10_Fehler_HV_Netz : 29|1@1+ (1,0) [0|1] "" XXX
 SG_ M10_EKlKomLeiRed : 30|2@1+ (1,0) [0|3] "" XXX
 SG_ M10_Klimadruck : 32|8@1+ (0.2,0) [0|50.8] "bar" XXX
 SG_ M10_KompOffCode : 40|4@1+ (1,0) [0|15] "" XXX
 SG_ M10_StartStopp_Fahrerwunsch : 44|2@1+ (1,0) [0|3] "" XXX
 SG_ M10_Akustik : 46|2@1+ (1,0) [0|3] "" XXX
 SG_ M10_Text_1_Hybrid : 48|1@1+ (1,0) [0|1] "" XXX
 SG_ M10_Text_2_Hybrid : 49|1@1+ (1,0) [0|1] "" XXX
 SG_ M10_Text_3_Hybrid : 50|1@1+ (1,0) [0|1] "" XXX
 SG_ M10_Text_4_Hybrid : 51|1@1+ (1,0) [0|1] "" XXX
 SG_ M10_Text_5_Hybrid : 52|1@1+ (1,0) [0|1] "" XXX
 SG_ M10_Text_6_Hybrid : 53|1@1+ (1,0) [0|1] "" XXX
 SG_ M10_Text_7_Hybrid : 54|1@1+ (1,0) [0|1] "" XXX
 SG_ M10_Text_8_Hybrid : 55|1@1+ (1,0) [0|1] "" XXX
 SG_ M10_ShiftLockLampe : 56|1@1+ (1,0) [0|1] "" XXX
 SG_ MO_Auth_Aufforderung_WFS : 57|1@1+ (1,0) [0|1] "" XXX
 SG_ M10_BMSInfo_gue : 58|1@1+ (1,0) [0|1] "" XXX
 SG_ M10_VentilationReq : 59|1@1+ (1,0) [0|1] "" XXX
 SG_ M10_BattFanSpd : 60|4@1+ (10,0) [0|140] "%" XXX

BO_ 1423 Motor_12: 8 XXX
 SG_ M12_MKB_MUX M : 56|2@1+ (1,0) [0|3] "" XXX
 SG_ M12_MKB_01 m0 : 59|5@1+ (1,0) [0|31] "" XXX
 SG_ M12_MKB_02 m1 : 59|5@1+ (1,0) [0|31] "" XXX
 SG_ M12_MKB_03 m2 : 59|5@1+ (1,0) [0|31] "" XXX
 SG_ M12_MKB_04 m3 : 59|5@1+ (1,0) [0|31] "" XXX
 SG_ MO_ITM_Kuehlmittel_Temp : 0|8@1+ (0.75,-48) [-48|143.25] "C" XXX
 SG_ M12_E85_Sensor : 8|4@1+ (10,0) [0|100] "%" XXX
 SG_ M12_SCR_Anz_Motorstarts : 12|4@1+ (1,0) [0|15] "" XXX
 SG_ M12_SCR_Reichweite : 16|15@1+ (1,0) [0|32766] "km" XXX
 SG_ SCR_Tankdeckel : 31|1@1+ (1,0) [0|1] "" XXX
 SG_ M12_SCR_Warnstufe_1 : 32|1@1+ (1,0) [0|1] "" XXX
 SG_ M12_SCR_Warnstufe_2 : 33|1@1+ (1,0) [0|1] "" XXX
 SG_ M12_SCR_Text : 34|3@1+ (1,0) [0|7] "" XXX
 SG_ M12_Akustik : 37|2@1+ (1,0) [0|3] "" XXX
 SG_ M12_Luftfilter_Lampe : 39|1@1+ (1,0) [0|1] "" XXX
 SG_ M12_Kraftstofffilter_Wasser : 40|1@1+ (1,0) [0|1] "" XXX
 SG_ M12_SCR_Systemfehler : 41|1@1+ (1,0) [0|1] "" XXX
 SG_ M12_SCR_Inducement : 42|2@1+ (1,0) [0|3] "" XXX
 SG_ M12_CO2_Faktor : 44|12@1+ (1,0) [0|4094] "g/l" XXX
 SG_ MO_EDK_Luefter_defekt : 58|1@1+ (1,0) [0|1] "" XXX

BO_ 1437 mRemotestart_FFB: 8 Vector__XXX
 SG_ RSF_Tastencode_1 : 0|8@1+ (1,0) [1|255] "" Vector__XXX
 SG_ RSF_Tastencode_2 : 8|8@1+ (1,0) [1|255] "" Vector__XXX
 SG_ RSF_Tastencode_Maske : 16|8@1+ (1,0) [1|255] "" Vector__XXX

BO_ 640 Motor_1: 8 Motor
 SG_ MO1_Wunschmo : 56|8@1+ (0.39,0) [0|99.06] "%" XXX
 SG_ MO1_Verlustmo : 48|8@1+ (0.39,0) [0|99.06] "%" XXX
 SG_ MO1_Pedalwert : 40|8@1+ (0.4,0) [0|101.6] "%" XXX
 SG_ MO1_Mo_o_ex : 32|8@1+ (0.39,0) [0|99.06] "%" XXX
 SG_ MO1_Drehzahl : 16|16@1+ (0.25,0) [0|16256] "1/min" XXX
 SG_ MO1_Mo_m_ex : 8|8@1+ (0.39,0) [0|99.06] "%" XXX
 SG_ MO1_Sta_MotMo : 7|1@1+ (1,0) [0|1] "" XXX
 SG_ MO1_Sta_Getr : 6|1@1+ (1,0) [0|1] "" XXX
 SG_ MO1_Sta_Bremse : 5|1@1+ (1,0) [0|1] "" XXX
 SG_ MO1_TiOut_Br : 4|1@1+ (1,0) [0|1] "" XXX
 SG_ MO1_Kup_schalt : 3|1@1+ (1,0) [0|1] "" XXX
 SG_ MO1_Kickdown : 2|1@1+ (1,0) [0|1] "" XXX
 SG_ MO1_Sta_Pedal : 1|1@1+ (1,0) [0|1] "" XXX
 SG_ MO1_Leergas : 0|1@1+ (1,0) [0|1] "" XXX

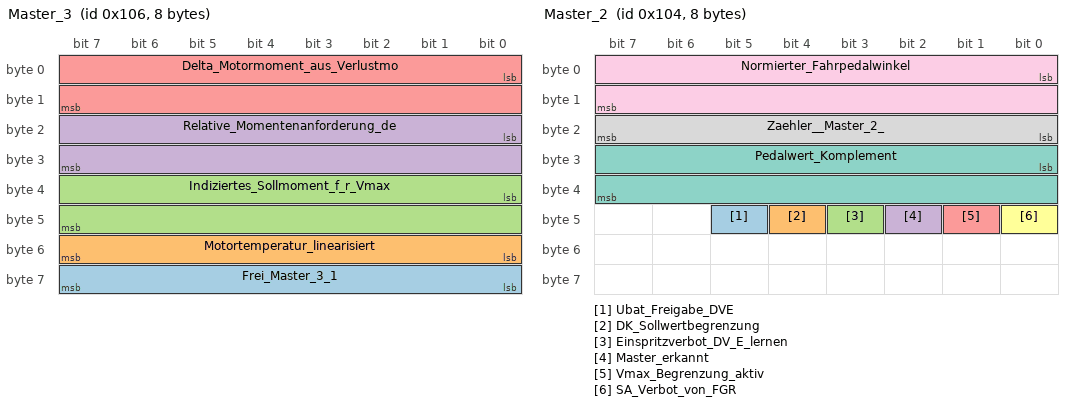
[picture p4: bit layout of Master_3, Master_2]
BO_ 262 Master_3: 8 XXX
 SG_ Frei_Master_3_1 : 56|8@1+ (1,0) [0|0] "" XXX
 SG_ Motortemperatur_linearisiert : 48|8@1+ (0.75,-48) [-48|143.25] "" XXX
 SG_ Indiziertes_Sollmoment_f_r_Vmax : 32|16@1+ (0.0015259,0) [0|100] "%" XXX
 SG_ Relative_Momentenanforderung_de : 16|16@1+ (0.003052,0) [0|200] "%" XXX
 SG_ Delta_Motormoment_aus_Verlustmo : 0|16@1+ (0.003052,-100) [-100|100] "%" XXX

BO_ 260 Master_2: 8 XXX
 SG_ Ubat_Freigabe_DVE : 45|1@1+ (1,0) [0|0] "" XXX
 SG_ DK_Sollwertbegrenzung : 44|1@1+ (1,0) [0|0] "" XXX
 SG_ Einspritzverbot_DV_E_lernen : 43|1@1+ (1,0) [0|0] "" XXX
 SG_ Master_erkannt : 42|1@1+ (1,0) [0|0] "" XXX
 SG_ Vmax_Begrenzung_aktiv : 41|1@1+ (1,0) [0|0] "" XXX
 SG_ SA_Verbot_von_FGR : 40|1@1+ (1,0) [0|0] "" XXX
 SG_ Pedalwert_Komplement : 24|16@1+ (1,0) [0|0] "" XXX
 SG_ Zaehler__Master_2_ : 16|8@1+ (1,0) [0|255] "" XXX
 SG_ Normierter_Fahrpedalwinkel : 0|16@1+ (0.001526,0) [0|100] "%" XXX

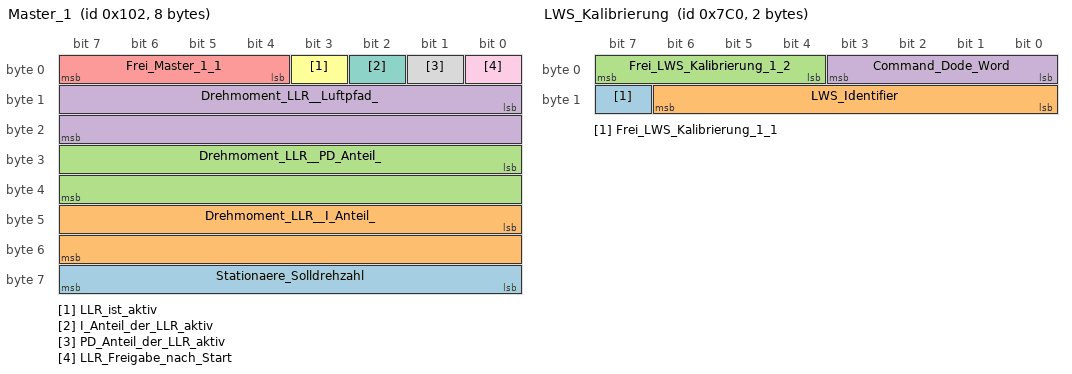
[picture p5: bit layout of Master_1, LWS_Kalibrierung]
BO_ 258 Master_1: 8 XXX
 SG_ Stationaere_Solldrehzahl : 56|8@1+ (10,0) [0|2550] "Umin" XXX
 SG_ Drehmoment_LLR__I_Anteil_ : 40|16@1+ (0.003052,-100) [-100|100] "%" XXX
 SG_ Drehmoment_LLR__PD_Anteil_ : 24|16@1+ (0.003052,-100) [-100|100] "%" XXX
 SG_ Drehmoment_LLR__Luftpfad_ : 8|16@1+ (0.003052,-100) [-100|100] "%" XXX
 SG_ Frei_Master_1_1 : 4|4@1+ (1,0) [0|0] "" XXX
 SG_ LLR_ist_aktiv : 3|1@1+ (1,0) [0|0] "" XXX
 SG_ I_Anteil_der_LLR_aktiv : 2|1@1+ (1,0) [0|0] "" XXX
 SG_ PD_Anteil_der_LLR_aktiv : 1|1@1+ (1,0) [0|0] "" XXX
 SG_ LLR_Freigabe_nach_Start : 0|1@1+ (1,0) [0|0] "" XXX

BO_ 1984 LWS_Kalibrierung: 2 XXX
 SG_ Frei_LWS_Kalibrierung_1_1 : 15|1@1+ (1,0) [0|0] "" XXX
 SG_ LWS_Identifier : 8|7@1+ (1,0) [0|0] "" XXX
 SG_ Frei_LWS_Kalibrierung_1_2 : 4|4@1+ (1,0) [0|0] "" XXX
 SG_ Command_Dode_Word : 0|4@1+ (1,0) [0|0] "" XXX

BO_ 1986 Lenkwinkel_Init: 4 XXX
 SG_ Kodierbytes : 8|24@1+ (1,0) [0|0] "" XXX
 SG_ Identiifier_f_r_LWS_Init : 0|8@1+ (1,0) [0|0] "" XXX

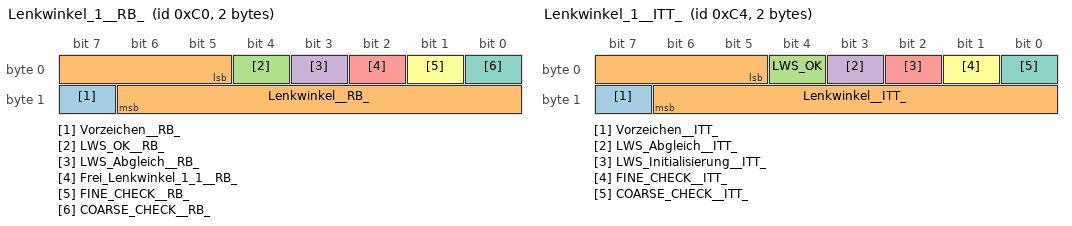
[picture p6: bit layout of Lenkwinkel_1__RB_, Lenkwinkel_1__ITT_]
BO_ 192 Lenkwinkel_1__RB_: 2 XXX
 SG_ Vorzeichen__RB_ : 15|1@1+ (1,0) [0|0] "" XXX
 SG_ Lenkwinkel__RB_ : 5|10@1+ (2.5,-720) [-720|720] "" XXX
 SG_ LWS_OK__RB_ : 4|1@1+ (1,0) [0|0] "" XXX
 SG_ LWS_Abgleich__RB_ : 3|1@1+ (1,0) [0|0] "" XXX
 SG_ Frei_Lenkwinkel_1_1__RB_ : 2|1@1+ (1,0) [0|0] "" XXX
 SG_ FINE_CHECK__RB_ : 1|1@1+ (1,0) [0|0] "" XXX
 SG_ COARSE_CHECK__RB_ : 0|1@1+ (1,0) [0|0] "" XXX

BO_ 196 Lenkwinkel_1__ITT_: 2 XXX
 SG_ Vorzeichen__ITT_ : 15|1@1+ (1,0) [0|0] "" XXX
 SG_ Lenkwinkel__ITT_ : 5|10@1+ (1.5,-768) [-768|766.5] "" XXX
 SG_ LWS_OK : 4|1@1+ (1,0) [0|0] "" XXX
 SG_ LWS_Abgleich__ITT_ : 3|1@1+ (1,0) [0|0] "" XXX
 SG_ LWS_Initialisierung__ITT_ : 2|1@1+ (1,0) [0|0] "" XXX
 SG_ FINE_CHECK__ITT_ : 1|1@1+ (1,0) [0|0] "" XXX
 SG_ COARSE_CHECK__ITT_ : 0|1@1+ (1,0) [0|0] "" XXX

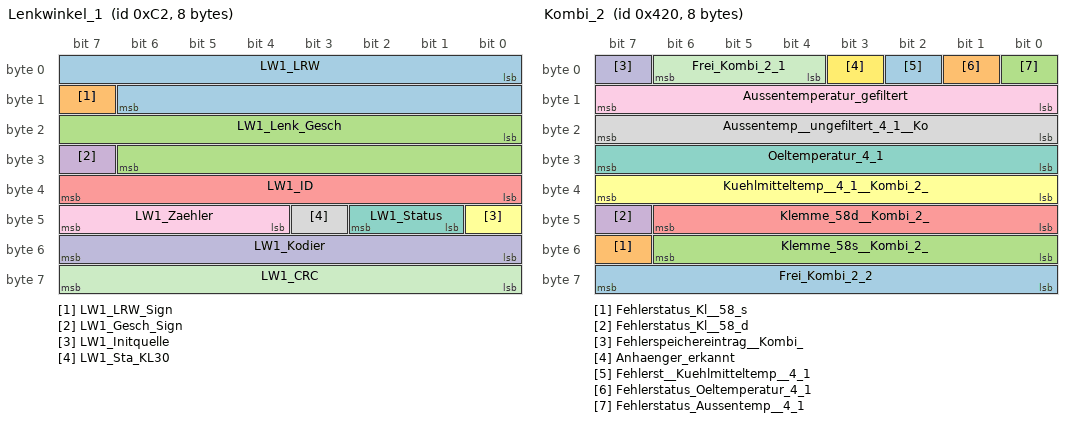
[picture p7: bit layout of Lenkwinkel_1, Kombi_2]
BO_ 194 Lenkwinkel_1: 8 XXX
 SG_ LW1_LRW : 0|15@1+ (0.04375,0) [0|1433.55625] "°Grad" Gateway,ESP,ABS
 SG_ LW1_LRW_Sign : 15|1@1+ (1,0) [0|1] "" Gateway,ESP,ABS
 SG_ LW1_Lenk_Gesch : 16|15@1+ (0.04375,0) [0|1433.55625] "°Grad/s" Gateway,ESP,ABS
 SG_ LW1_Gesch_Sign : 31|1@1+ (1,0) [0|1] "" Gateway,ESP,ABS
 SG_ LW1_ID : 32|8@1+ (1,0) [0|255] "" Gateway,ESP,ABS
 SG_ LW1_Initquelle : 40|1@1+ (1,0) [0|1] "" Gateway,ESP,ABS
 SG_ LW1_Status : 41|2@1+ (1,0) [0|3] "" Gateway,ESP,ABS
 SG_ LW1_Sta_KL30 : 43|1@1+ (1,0) [0|1] "" Gateway,ESP,ABS
 SG_ LW1_Zaehler : 44|4@1+ (1,0) [0|15] "" Gateway,ESP,ABS
 SG_ LW1_Kodier : 48|8@1+ (1,0) [0|255] "" Gateway
 SG_ LW1_CRC : 56|8@1+ (1,0) [0|255] "" Gateway,ESP,ABS

BO_ 1502 Lenkhilfe_Fehler: 7 XXX
 SG_ Werkstattcode : 48|8@1+ (1,0) [0|0] "" XXX
 SG_ Multiplex_Signal : 45|3@1+ (1,0) [0|7] "" XXX
 SG_ Sensorcodierung_Lenkhilfe : 44|1@1+ (1,0) [0|0] "" XXX
 SG_ Kennliniencodierung_Lenkhilfe : 40|4@1+ (1,0) [0|15] "Kennlinie" XXX
 SG_ Geber_f__Lenkw__Speicher_ausles : 39|1@1+ (1,0) [0|0] "" XXX
 SG_ Kombiinstr__Speicher_auslesen : 38|1@1+ (1,0) [0|0] "" XXX
 SG_ Steuerger__Speicher_auslesen : 37|1@1+ (1,0) [0|0] "" XXX
 SG_ Lenkhilfe_Steuergeraet_defekt : 36|1@1+ (1,0) [0|0] "" XXX
 SG_ Frei_Lenkhilfe_1_3 : 32|4@1+ (1,0) [0|0] "" XXX
 SG_ Frei_Lenkhilfe_1_4 : 30|2@1+ (1,0) [0|0] "" XXX
 SG_ Geber_f__Lenkwi__k__CAN_Komm_sp : 29|1@1+ (1,0) [0|0] "" XXX
 SG_ Geber_f__Lenkwinkel_k__CAN_Komm : 28|1@1+ (1,0) [0|0] "" XXX
 SG_ Kombiinstr__k__CAN_Kommunik__sp : 27|1@1+ (1,0) [0|0] "" XXX
 SG_ Kombiinstrument_k__CAN_Kommunik : 26|1@1+ (1,0) [0|0] "" XXX
 SG_ Steuergeraet_k__CAN_Kommunik__S : 25|1@1+ (1,0) [0|0] "" XXX
 SG_ Steuergeraet_keine_CAN_Kommunik : 24|1@1+ (1,0) [0|0] "" XXX
 SG_ Lenkhilfe_Spannung_Ks__nach_Mas : 23|1@1+ (1,0) [0|0] "" XXX
 SG_ Lenkhilfe_Spannung_Ks_nach_Mass : 22|1@1+ (1,0) [0|0] "" XXX
 SG_ Lenkhilfe_Spannung_Ks__nach___s : 21|1@1+ (1,0) [0|0] "" XXX
 SG_ Lenkhilfe_Spannung_Ks__nach__ : 20|1@1+ (1,0) [0|0] "" XXX
 SG_ Lenkhilfe_Temperaturschutz_sp_ : 19|1@1+ (1,0) [0|0] "" XXX
 SG_ Lenkhilfe_Temperaturschutz : 18|1@1+ (1,0) [0|0] "" XXX
 SG_ Lenkhilfe_Betrieb_unpl__Sig__sp : 17|1@1+ (1,0) [0|0] "" XXX
 SG_ Lenkhilfe_Betrieb_unpl__Signal : 16|1@1+ (1,0) [0|0] "" XXX
 SG_ Lenkhilfesensor_k__Kommunik__sp : 15|1@1+ (1,0) [0|0] "" XXX
 SG_ Lenkhilfesensor_keine_Kommunik_ : 14|1@1+ (1,0) [0|0] "" XXX
 SG_ Lenkhilfesensor_defekt_sp_ : 13|1@1+ (1,0) [0|0] "" XXX
 SG_ Lenkhilfesensor_defekt : 12|1@1+ (1,0) [0|0] "" XXX
 SG_ Lenkhilfesensor_Unterbrechung_s : 11|1@1+ (1,0) [0|0] "" XXX
 SG_ Lenkhilfesensor_Unterbrechung : 10|1@1+ (1,0) [0|0] "" XXX
 SG_ Lenkhilfesensor_Ks_nach_Masse_s : 9|1@1+ (1,0) [0|0] "" XXX
 SG_ Lenkhifesensor_Ks_nach_Masse : 8|1@1+ (1,0) [0|0] "" XXX
 SG_ Spannung_Kl_15_zu_klein_sp_ : 7|1@1+ (1,0) [0|0] "" XXX
 SG_ Spannung_Kl_15_zu_klein : 6|1@1+ (1,0) [0|0] "" XXX
 SG_ Frei_Lenkhilfe_1_5 : 4|2@1+ (1,0) [0|0] "" XXX
 SG_ Spannung_Kl_30_zu_klein_sp_ : 3|1@1+ (1,0) [0|0] "" XXX
 SG_ Spannung_Kl_30_zu_klein : 2|1@1+ (1,0) [0|0] "" XXX
 SG_ Spannung_Kl_30_zu_gro__sp_ : 1|1@1+ (1,0) [0|0] "" XXX
 SG_ Spannung_Kl_30_zu_gro_ : 0|1@1+ (1,0) [0|0] "" XXX

BO_ 976 Lenkhilfe_1: 2 XXX
 SG_ LH1_Lastinfo : 0|7@1+ (1,0) [0|127] "A" XXX
 SG_ LH1_Fehler_LI : 7|1@1+ (1,0) [0|1] "" XXX
 SG_ LH1_Sicherheitslamp : 8|1@1+ (1,0) [0|1] "" XXX
 SG_ LH1_Fehlerlampe : 9|1@1+ (1,0) [0|1] "" XXX
 SG_ LH1_Textbits : 10|3@1+ (1,0) [0|7] "" XXX
 SG_ LH1_Akustiksign : 13|1@1+ (1,0) [0|1] "" XXX
 SG_ LH1_SleepInd : 14|1@1+ (1,0) [0|1] "" XXX
 SG_ LH1_Fehlereintr : 15|1@1+ (1,0) [0|1] "" XXX
 SG_ LH1_EPS_Diagmode : 16|1@1+ (1,0) [0|1] "" XXX
 SG_ LH1_gue_ECU_Temp : 19|1@1+ (1,0) [0|1] "" XXX
 SG_ LH1_Kuehlung : 20|1@1+ (1,0) [0|1] "" XXX
 SG_ LH1_Mode_Hybrid : 21|1@1+ (1,0) [0|1] "" XXX
 SG_ LH1_NL_Untersp : 24|1@1+ (1,0) [0|1] "" XXX
 SG_ LH1_NL_Uebersp : 25|1@1+ (1,0) [0|1] "" XXX
 SG_ LH1_NL_Uebertemp : 26|1@1+ (1,0) [0|1] "" XXX
 SG_ LH1_NL_Sensor : 27|1@1+ (1,0) [0|1] "" XXX
 SG_ LH1_NL_CAN_SS : 28|1@1+ (1,0) [0|1] "" XXX
 SG_ LH1_NL_ECU : 29|1@1+ (1,0) [0|1] "" XXX
 SG_ LH1_NL_Motor : 30|1@1+ (1,0) [0|1] "" XXX
 SG_ LH1_NL_LeistDichte : 31|1@1+ (1,0) [0|1] "" XXX
 SG_ LH1_ULeistung : 32|8@1+ (0.5,0) [0|100] "%" XXX
 SG_ LH1_ECU_Temp : 40|8@1+ (1,-70) [-70|185] "°C" XXX

BO_ 1312 Kombi_3: 8 XXX
 SG_ Frei_Kombi_3_2 : 60|4@1+ (1,0) [0|0] "" XXX
 SG_ Kilometerstand : 40|20@1+ (1,0) [0|1000000] "km" XXX
 SG_ Fehlerstatus_Standzeit : 39|1@1+ (1,0) [0|0] "" XXX
 SG_ Standzeit : 24|15@1+ (4,0) [0|131068] "sec" XXX
 SG_ Frei_Kombi_3_1 : 20|4@1+ (1,0) [0|0] "" XXX
 SG_ Schluesselinfo : 16|4@1+ (1,0) [0|15] "" XXX
 SG_ Kombi_Multiplex_Code M : 14|2@1+ (1,0) [0|0] "" XXX
 SG_ Kombi_Verbauliste_Niveauregulie m3 : 11|1@1+ (1,0) [0|0] "" XXX
 SG_ Kombi_Multiplex_Marke m1 : 11|3@1+ (1,0) [0|0] "" XXX
 SG_ Kombi_Verbauliste_Lenkhilfe m3 : 10|1@1+ (1,0) [0|0] "" XXX
 SG_ Kombi_Verbauliste_Dieselpumpe m3 : 9|1@1+ (1,0) [0|0] "" XXX
 SG_ Kombi_Verbauliste_Lenkwinkel m3 : 8|1@1+ (1,0) [0|0] "" XXX
 SG_ Kombi_Multiplex_Baureihe m1 : 8|3@1+ (1,0) [0|0] "" XXX
 SG_ Kombi_Multiplex_Laendervariante m0 : 8|6@1+ (1,0) [0|0] "" XXX
 SG_ Kombi_Verbauliste_Allrad m3 : 7|1@1+ (1,0) [0|0] "" XXX
 SG_ Kombi_Verbauliste_Bordnetz m3 : 6|1@1+ (1,0) [0|0] "" XXX
 SG_ Kombi_Verbauliste_ACC m3 : 5|1@1+ (1,0) [0|0] "" XXX
 SG_ Kombi_Verbauliste_Airbag m3 : 4|1@1+ (1,0) [0|0] "" XXX
 SG_ Kombi_Multiplex_Generation m1 : 4|4@1+ (1,0) [0|0] "" XXX
 SG_ Kombi_Verbauliste_Klima m3 : 3|1@1+ (1,0) [0|0] "" XXX
 SG_ Kombi_Verbauliste_ABS m3 : 2|1@1+ (1,0) [0|0] "" XXX
 SG_ Kombi_Verbauliste_Motor m3 : 0|1@1+ (1,0) [0|0] "" XXX
 SG_ Kombi_Multiplex_Derivat m1 : 0|4@1+ (1,0) [0|0] "" XXX
 SG_ Kombi_Multiplex_Sprachvariante m0 : 0|8@1+ (1,0) [0|0] "" XXX
 SG_ Kombi_Multiplex_Reifenumfang m2 : 0|12@1+ (1,0) [0|4095] "mm" XXX

BO_ 1056 Kombi_2: 8 XXX
 SG_ Frei_Kombi_2_2 : 56|8@1+ (1,0) [0|0] "" XXX
 SG_ Fehlerstatus_Kl__58_s : 55|1@1+ (1,0) [0|0] "" XXX
 SG_ Klemme_58s__Kombi_2_ : 48|7@1+ (1,0) [0|100] "%" XXX
 SG_ Fehlerstatus_Kl__58_d : 47|1@1+ (1,0) [0|0] "" XXX
 SG_ Klemme_58d__Kombi_2_ : 40|7@1+ (1,0) [0|100] "%" XXX
 SG_ Kuehlmitteltemp__4_1__Kombi_2_ : 32|8@1+ (0.75,-48) [-48|142.5] "C" XXX
 SG_ Oeltemperatur_4_1 : 24|8@1+ (1,-60) [-60|194] "C" XXX
 SG_ Aussentemp__ungefiltert_4_1__Ko : 16|8@1+ (0.5,-50) [-50|77] "C" XXX
 SG_ Aussentemperatur_gefiltert : 8|8@1+ (0.5,-50) [-50|77] "C" XXX
 SG_ Fehlerspeichereintrag__Kombi_ : 7|1@1+ (1,0) [0|0] "" XXX
 SG_ Frei_Kombi_2_1 : 4|3@1+ (1,0) [0|0] "" XXX
 SG_ Anhaenger_erkannt : 3|1@1+ (1,0) [0|0] "" XXX
 SG_ Fehlerst__Kuehlmitteltemp__4_1 : 2|1@1+ (1,0) [0|0] "" XXX
 SG_ Fehlerstatus_Oeltemperatur_4_1 : 1|1@1+ (1,0) [0|0] "" XXX
 SG_ Fehlerstatus_Aussentemp__4_1 : 0|1@1+ (1,0) [0|0] "" XXX

BO_ 800 Kombi_1: 8 XXX
 SG_ Frei_Kombi_1_3 : 56|8@1+ (1,0) [0|0] "" XXX
 SG_ Angezeigte_Geschwindigkeit : 46|10@1+ (0.32,0) [0|325] "km/h" XXX
 SG_ Blinker_rechts_4_1 : 45|1@1+ (1,0) [0|0] "" XXX
 SG_ Blinker_links_4_1 : 44|1@1+ (1,0) [0|0] "" XXX
 SG_ Gesetzte_Zeitluecke__Kombi_1_ : 43|1@1+ (1,0) [0|0] "" XXX
 SG_ ADR_Summer_abgeschaltet : 42|1@1+ (1,0) [0|0] "" XXX
 SG_ Frei_Kombi_1_2 : 40|2@1+ (1,0) [0|0] "" XXX
 SG_ Geschwindigkeit__Kombi_1_ : 25|15@1+ (0.01,0) [0|326] "km/h" XXX
 SG_ Signalquelle_Geschwindigkeit_4_ : 24|1@1+ (1,0) [0|0] "" XXX
 SG_ Tankwarnung : 23|1@1+ (1,0) [0|0] "" XXX
 SG_ Tankinhalt : 16|7@1+ (1,0) [0|126] "l" XXX
 SG_ Tankstop : 15|1@1+ (1,0) [0|0] "" XXX
 SG_ Frei_Kombi_1_7 : 12|3@1+ (1,0) [0|0] "" XXX
 SG_ Kombi_im_Stellgliedtest : 11|1@1+ (1,0) [0|0] "" XXX
 SG_ Ladekontroll_Lampe__Kombi_ : 10|1@1+ (1,0) [0|0] "" XXX
 SG_ Bremsinfo : 8|2@1+ (1,0) [0|0] "" XXX
 SG_ Vorgluehlampe__Kombi_1_ : 7|1@1+ (1,0) [0|0] "" XXX
 SG_ Tankwarnlampe : 6|1@1+ (1,0) [0|0] "" XXX
 SG_ Heissleuchten_Vorwarnung : 5|1@1+ (1,0) [0|0] "" XXX
 SG_ Kuehlmittelmangel : 4|1@1+ (1,0) [0|0] "" XXX
 SG_ Dynamische_Oeldruckwarnung : 3|1@1+ (1,0) [0|0] "" XXX
 SG_ Oeldruck : 2|1@1+ (1,0) [0|0] "" XXX
 SG_ Fehlerstatus_Tank : 1|1@1+ (1,0) [0|0] "" XXX
 SG_ Fahrertuer_4_1 : 0|1@1+ (1,0) [0|0] "" XXX

BO_ 1504 Klima_1: 8 XXX
 SG_ Aussentemp__ungef__Sto_f__4_1 : 56|8@1+ (0.5,-50) [-50|77] "C" XXX
 SG_ Fehlerspeichereintrag__Klima_ : 55|1@1+ (1,0) [0|0] "" XXX
 SG_ Frei_Klima_1_5 : 50|5@1+ (1,0) [0|0] "" XXX
 SG_ AC_Schalter : 49|1@1+ (1,0) [0|0] "" XXX
 SG_ Temperatureinheit : 48|1@1+ (1,0) [0|0] "" XXX
 SG_ Kuehlerluefteransteuerung__Klim : 40|8@1+ (0.4,0) [0|101.6] "%" XXX
 SG_ Geblaeselast_4_1 : 32|8@1+ (0.4,0) [0|101.6] "%" XXX
 SG_ Kompressorlast : 24|8@1+ (0.25,0) [0|63.5] "Nm" XXX
 SG_ Klimadrucksignal__Klima_1_ : 16|8@1+ (0.2,0) [0|50.8] "bar" XXX
 SG_ Aussentemp__ungef__4_1__Klima_1 : 8|8@1+ (0.5,-50) [-50|77] "C" XXX
 SG_ Kaeltemitteldruck_veraltet : 7|1@1+ (1,0) [0|0] "" XXX
 SG_ Kompressormoment_veraltet_4_1 : 6|1@1+ (1,0) [0|0] "" XXX
 SG_ Keine_Heizleistg_gewuenscht_4_1 : 5|1@1+ (1,0) [0|0] "" XXX
 SG_ Kompressorzustand__4_1_ : 4|1@1+ (1,0) [0|0] "" XXX
 SG_ Heizbare_Frontscheibe : 3|1@1+ (1,0) [0|0] "" XXX
 SG_ Heizbare_Heckscheibe : 2|1@1+ (1,0) [0|0] "" XXX
 SG_ Fahrerwunsch_Zuheizer : 1|1@1+ (1,0) [0|0] "" XXX
 SG_ Drehzahlanhebung : 0|1@1+ (1,0) [0|0] "" XXX

BO_ 906 GRA_Neu: 4 XXX
 SG_ CHECKSUM : 0|8@1+ (1,0) [0|255] "" XXX
 SG_ GRA_Hauptschalt : 8|1@1+ (1,0) [0|1] "" XXX
 SG_ GRA_Abbrechen : 9|1@1+ (1,0) [0|1] "" XXX
 SG_ GRA_Down_kurz : 10|1@1+ (1,0) [0|1] "" XXX
 SG_ GRA_Up_kurz : 11|1@1+ (1,0) [0|1] "" XXX
 SG_ GRA_Down_lang : 12|1@1+ (1,0) [0|1] "" XXX
 SG_ GRA_Up_lang : 13|1@1+ (1,0) [0|1] "" XXX
 SG_ GRA_Fehler_Bed : 14|1@1+ (1,0) [0|1] "" XXX
 SG_ GRA_Kodierinfo : 15|1@1+ (1,0) [0|1] "" XXX
 SG_ GRA_Neu_Setzen : 16|1@1+ (1,0) [0|1] "" XXX
 SG_ GRA_Recall : 17|1@1+ (1,0) [0|1] "" XXX
 SG_ GRA_Sender : 18|2@1+ (1,0) [0|3] "" XXX
 SG_ COUNTER : 20|4@1+ (1,0) [0|15] "" XXX
 SG_ GRA_Tip_Down : 24|1@1+ (1,0) [0|1] "" XXX
 SG_ GRA_Tip_Up : 25|1@1+ (1,0) [0|1] "" XXX
 SG_ GRA_Zeitluecke : 26|2@1+ (1,0) [0|3] "" XXX
 SG_ GRA_Sta_Limiter : 28|1@1+ (1,0) [0|1] "" XXX
 SG_ GRA_Typ_Hauptschalt : 29|1@1+ (1,0) [0|1] "" XXX
 SG_ GRA_Sportschalter : 30|1@1+ (1,0) [0|1] "" XXX
 SG_ GRA_Fehler_Tip : 31|1@1+ (1,0) [0|1] "" XXX

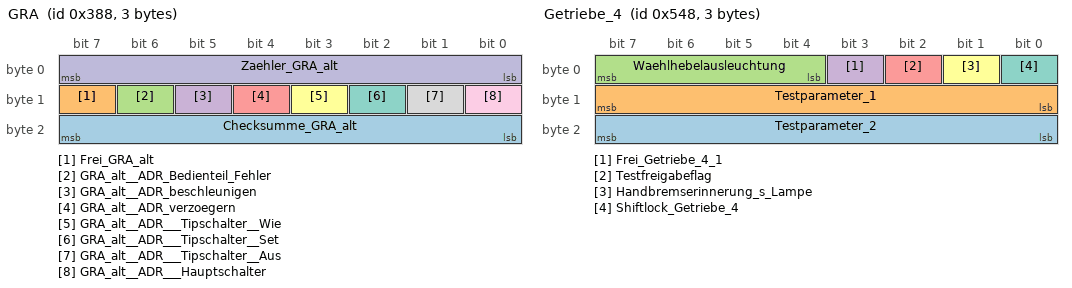
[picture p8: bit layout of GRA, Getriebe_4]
BO_ 904 GRA: 3 XXX
 SG_ Checksumme_GRA_alt : 16|8@1+ (1,0) [0|0] "" XXX
 SG_ Frei_GRA_alt : 15|1@1+ (1,0) [0|0] "" XXX
 SG_ GRA_alt__ADR_Bedienteil_Fehler : 14|1@1+ (1,0) [0|0] "" XXX
 SG_ GRA_alt__ADR_beschleunigen : 13|1@1+ (1,0) [0|0] "" XXX
 SG_ GRA_alt__ADR_verzoegern : 12|1@1+ (1,0) [0|0] "" XXX
 SG_ GRA_alt__ADR___Tipschalter__Wie : 11|1@1+ (1,0) [0|0] "" XXX
 SG_ GRA_alt__ADR___Tipschalter__Set : 10|1@1+ (1,0) [0|0] "" XXX
 SG_ GRA_alt__ADR___Tipschalter__Aus : 9|1@1+ (1,0) [0|0] "" XXX
 SG_ GRA_alt__ADR___Hauptschalter : 8|1@1+ (1,0) [0|0] "" XXX
 SG_ Zaehler_GRA_alt : 0|8@1+ (1,0) [0|255] "" XXX

BO_ 1352 Getriebe_4: 3 XXX
 SG_ Testparameter_2 : 16|8@1+ (1,0) [0|255] "" XXX
 SG_ Testparameter_1 : 8|8@1+ (1,0) [0|255] "" XXX
 SG_ Waehlhebelausleuchtung : 4|4@1+ (1,0) [0|0] "" XXX
 SG_ Frei_Getriebe_4_1 : 3|1@1+ (1,0) [0|0] "" XXX
 SG_ Testfreigabeflag : 2|1@1+ (1,0) [0|0] "" XXX
 SG_ Handbremserinnerung_s_Lampe : 1|1@1+ (1,0) [0|0] "" XXX
 SG_ Shiftlock_Getriebe_4 : 0|1@1+ (1,0) [0|0] "" XXX

BO_ 1344 Getriebe_2: 8 XXX
 SG_ eingelegte_Fahrstufe : 60|4@1+ (1,0) [0|0] "" XXX
 SG_ Ganganzeige_Kombi___Getriebe_Va : 56|4@1+ (1,0) [0|15] "" XXX
 SG_ Fehlerlampe_f_r_Kupplung_bei_VL : 55|1@1+ (1,0) [0|0] "" XXX
 SG_ Anforderung_Kriechadaption : 54|1@1+ (1,0) [0|0] "" XXX
 SG_ ECO_Anzeige__4_1_ : 53|1@1+ (1,0) [0|0] "" XXX
 SG_ Shift_Lock_Lampe : 52|1@1+ (1,0) [0|0] "" XXX
 SG_ Unterdrueckung_von_Warnungen : 51|1@1+ (1,0) [0|0] "" XXX
 SG_ Gong : 50|1@1+ (1,0) [0|0] "" XXX
 SG_ Starter_wird_angesteuert : 49|1@1+ (1,0) [0|0] "" XXX
 SG_ Hochschaltlampe : 48|1@1+ (1,0) [0|0] "" XXX
 SG_ Synchronisationszeit : 40|8@1+ (20,0) [0|5080] "ms" XXX
 SG_ invertierte_Synchronisations_Wu : 32|8@1+ (25,0) [0|6350] "U/min" XXX
 SG_ Synchronisations_Wunschdrehzahl : 24|8@1+ (25,0) [0|6350] "U/min" XXX
 SG_ Gradientenbegrenzung : 16|8@1+ (10,0) [0|2540] "Nm/s" XXX
 SG_ Leerlaufsolldrehzahl__Getriebe : 8|8@1+ (10,0) [0|2540] "U/min" XXX
 SG_ Zahler_Getriebe_2 : 4|4@1+ (1,0) [0|15] "" XXX
 SG_ Zwischengasflag : 3|1@1+ (1,0) [0|0] "" XXX
 SG_ Ecomatic__4_1_ : 2|1@1+ (1,0) [0|0] "" XXX
 SG_ Schubabschaltunterstuetzung : 1|1@1+ (1,0) [0|0] "" XXX
 SG_ LFR_Adaption_Freigabeflag : 0|1@1+ (1,0) [0|0] "" XXX

BO_ 1088 Getriebe_1: 8 Transmission
 SG_ GE1_Schaltung : 0|1@1+ (1,0) [0|1] "" Gateway
 SG_ GE1_Sta_Schutz : 1|1@1+ (1,0) [0|1] "" Motor
 SG_ GE1_Klimakompr : 2|1@1+ (1,0) [0|1] "" Motor
 SG_ GE1_WK : 3|2@1+ (1,0) [0|3] "" Gateway
 SG_ GE1_StSt_Info : 5|2@1+ (1,0) [0|3] "" Gateway
 SG_ GE1_EGS_Anf : 7|1@1+ (1,0) [0|1] "" Motor
 SG_ GE1_Zielgang : 8|4@1+ (1,0) [0|15] "" Gateway
 SG_ GE1_Wahl_Pos : 12|4@1+ (1,0) [0|15] "" Gateway
 SG_ GE1_Mrad_Mkurb : 16|8@1+ (0.1,0) [0|25.4] "" Gateway
 SG_ GE1_Soll_Mo : 24|8@1+ (0.39,0) [0|99.06] "%" Motor
 SG_ GE1_Fahrwistd : 32|8@1+ (0.249,-31.623) [-31.623|31.623] "" Gateway
 SG_ GE1_Notlauf : 40|4@1+ (1,0) [0|15] "" Gateway
 SG_ GE1_Kuehlung : 44|2@1+ (1,0) [0|3] "" Gateway
 SG_ GE1_Sta_OBD : 47|1@1+ (1,0) [0|1] "" Motor
 SG_ GE1_LaunchControl : 48|1@1+ (1,0) [0|1] "" ESP
 SG_ GE1_Infobit : 49|1@1+ (1,0) [0|1] "" Gateway
 SG_ GE1_SleepInd : 50|1@1+ (1,0) [0|1] "" Gateway
 SG_ COUNTER : 51|4@1+ (1,0) [0|15] "" Gateway
 SG_ GE1_Fehlereintr : 55|1@1+ (1,0) [0|1] "" Gateway
 SG_ GE1_WaVerl_Mo : 56|8@1+ (0.39,0) [0|99.06] "%" Motor

BO_ 912 Gate_Komf_1: 8 XXX
 SG_ GK1_Sta_RDK_Warn : 0|1@1+ (1,0) [0|1] "" XXX
 SG_ GK1_Sta_Anhaen : 1|1@1+ (1,0) [0|1] "" XXX
 SG_ GK1_Sta_Licht1 : 2|1@1+ (1,0) [0|1] "" XXX
 SG_ GK1_Sta_Licht3 : 3|1@1+ (1,0) [0|1] "" XXX
 SG_ GK1_Sta_Tuerkont : 4|1@1+ (1,0) [0|1] "" XXX
 SG_ GK1_Sta_Li_vorn : 5|1@1+ (1,0) [0|1] "" XXX
 SG_ LIA_Standlicht : 6|1@1+ (1,0) [0|1] "" XXX
 SG_ GK1_SleepAckn : 7|1@1+ (1,0) [0|1] "" XXX
 SG_ GK1_CharismaModus : 8|4@1+ (1,0) [0|15] "" XXX
 SG_ GK1_SamFktNr : 12|4@1+ (1,0) [0|15] "" XXX
 SG_ GK1_Fa_Tuerkont : 16|1@1+ (1,0) [0|1] "" XXX
 SG_ GK1_RueckfahrSch : 17|1@1+ (1,0) [0|1] "" XXX
 SG_ GK1_ELV_verrieg : 18|1@1+ (1,0) [0|1] "" XXX
 SG_ GK1_Sta_Kessy_2 : 19|1@1+ (1,0) [0|1] "" XXX
 SG_ GK1_Sta_Stdhzg : 20|1@1+ (1,0) [0|1] "" XXX
 SG_ GK1_SH_Verbau : 21|1@1+ (1,0) [0|1] "" XXX
 SG_ GK1_ParkFrontWi : 22|1@1+ (1,0) [0|1] "" XXX
 SG_ GK1_KW_Warm : 23|1@1+ (1,0) [0|1] "" XXX
 SG_ BCM_Remotestart_Betrieb : 24|1@1+ (1,0) [0|1] "" XXX
 SG_ BCM_Offroad_Taster : 25|1@1+ (1,0) [0|1] "" XXX
 SG_ BSK_HL_geoeffnet : 26|1@1+ (1,0) [0|1] "" XXX
 SG_ BSK_HR_geoeffnet : 27|1@1+ (1,0) [0|1] "" XXX
 SG_ GK1_Rueckfahr : 28|1@1+ (1,0) [0|1] "" XXX
 SG_ GK1_BrLi_links : 29|1@1+ (1,0) [0|1] "" XXX
 SG_ GK1_BrLi_rechts : 30|1@1+ (1,0) [0|1] "" XXX
 SG_ GK1_BrLi_mitte : 31|1@1+ (1,0) [0|1] "" XXX
 SG_ GK1_BLS_ILM : 32|1@1+ (1,0) [0|1] "" XXX
 SG_ GK1_EDC_ILM : 33|1@1+ (1,0) [0|1] "" XXX
 SG_ GK1_Blinker_li : 34|1@1+ (1,0) [0|1] "" XXX
 SG_ GK1_Blinker_re : 35|1@1+ (1,0) [0|1] "" XXX
 SG_ GK1_def_P_verr : 36|1@1+ (1,0) [0|1] "" XXX
 SG_ GK1_LS1_Fernlicht : 37|1@1+ (1,0) [0|1] "" XXX
 SG_ GK1_Sta_Licht2 : 38|1@1+ (1,0) [0|1] "" XXX
 SG_ GK1_Sta_LSM : 39|1@1+ (1,0) [0|1] "" XXX
 SG_ WI1_Front_Wasch : 40|1@1+ (1,0) [0|1] "" XXX
 SG_ BSK_BT_geoeffnet : 41|1@1+ (1,0) [0|1] "" XXX
 SG_ BCM_CV_Taster : 42|1@1+ (1,0) [0|1] "" XXX
 SG_ BSK_HD_Hauptraste : 43|1@1+ (1,0) [0|1] "" XXX
 SG_ BSK_Tankklappe : 44|1@1+ (1,0) [0|1] "" XXX
 SG_ EV1_Anf_Klemme_50 : 45|1@1+ (1,0) [0|1] "" XXX
 SG_ GK1_Anhaenger : 46|1@1+ (1,0) [0|1] "" XXX
 SG_ GK1_BrLi_Anhaen : 47|1@1+ (1,0) [0|1] "" XXX
 SG_ GK1_Abblendlicht : 48|1@1+ (1,0) [0|1] "" XXX
 SG_ GK1_Fernlicht : 49|1@1+ (1,0) [0|1] "" XXX
 SG_ GK1_Wischer_vorn : 50|1@1+ (1,0) [0|1] "" XXX
 SG_ GK1_Sta_ILM_F_1 : 51|1@1+ (1,0) [0|1] "" XXX
 SG_ GK1_Abbl_VL_def : 52|1@1+ (1,0) [0|1] "" XXX
 SG_ GK1_Abbl_VR_def : 53|1@1+ (1,0) [0|1] "" XXX
 SG_ GK1_Blink_Autob : 54|1@1+ (1,0) [0|1] "" XXX
 SG_ GK1_Warnblk_Status : 55|1@1+ (1,0) [0|1] "" XXX
 SG_ GK1_SH_laeuft : 56|1@1+ (1,0) [0|1] "" XXX
 SG_ SH1_ein_Wasserpumpe : 57|1@1+ (1,0) [0|1] "" XXX
 SG_ GK1_Nebel_ein : 58|1@1+ (1,0) [0|1] "" XXX
 SG_ GK1_Bremslicht : 59|1@1+ (1,0) [0|1] "" XXX
 SG_ GK1_Anh_abgesteckt : 60|1@1+ (1,0) [0|1] "" XXX
 SG_ GK1_AnhKonLamp : 61|1@1+ (1,0) [0|1] "" XXX
 SG_ LDS_Stellung_AFL : 62|1@1+ (1,0) [0|1] "" XXX
 SG_ GK1_SH_Zusatzfkt : 63|1@1+ (1,0) [0|1] "" XXX

BO_ 1340 Fahrwerk_1: 1 XXX
 SG_ Frei_Fahrwerk_1_2 : 7|1@1+ (1,0) [0|0] "" XXX
 SG_ Frei_Fahrwerk_1_1 : 6|2@1+ (1,0) [0|0] "" XXX
 SG_ Einstellung_Fahrwerkdaempfung_4 : 4|3@1+ (1,0) [0|7] "" XXX
 SG_ Ansteuererung_Fahrzeugniveau : 0|4@1+ (1,0) [0|15] "" XXX

BO_ 1482 EPB_2: 8 XXX
 SG_ CHECKSUM : 0|8@1+ (1,0) [0|255] "" XXX
 SG_ COUNTER : 8|4@1+ (1,0) [0|15] "" XXX
 SG_ EPB_Status : 12|2@1+ (1,0) [0|3] "" XXX

BO_ 1472 EPB_1: 8 XXX
 SG_ COUNTER : 0|4@1+ (1,0) [0|15] "" XXX
 SG_ EP1_Fehler_Sta : 4|2@1+ (1,0) [0|3] "" Vector__XXX
 SG_ EP1_Sta_EPB : 6|1@1+ (1,0) [0|1] "" XXX
 SG_ EP1_Sta_Schalter : 7|1@1+ (1,0) [0|1] "" XXX
 SG_ EP1_Spannkraft : 8|5@1+ (1,0) [0|30] "Unit_KiloNewto" XXX
 SG_ EP1_Schalterinfo : 13|2@1+ (1,0) [0|3] "" XXX
 SG_ EP1_Sta_NWS : 15|1@1+ (1,0) [0|1] "" XXX
 SG_ EP1_Neig_winkel : 16|8@1+ (1,-128) [-128|127] "Unit_PerCentOfForceOfGravi" XXX
 SG_ EP1_Verzoegerung : 24|8@1+ (0.048,-7.968) [-7.968|4.224] "Unit_MeterPerSeconSquar" XXX
 SG_ EP1_Fehlereintr : 32|1@1+ (1,0) [0|1] "" XXX
 SG_ EP1_Freigabe_Ver : 33|1@1+ (1,0) [0|1] "" XXX
 SG_ EP1_AutoHold_zul : 34|1@1+ (1,0) [0|1] "" XXX
 SG_ EP1_AutoHold_aktiv : 35|1@1+ (1,0) [0|1] "" XXX
 SG_ EP1_SleepInd : 36|1@1+ (1,0) [0|1] "" XXX
 SG_ EP1_Status_Kl_15 : 37|1@1+ (1,0) [0|1] "" XXX
 SG_ EP1_Lampe_AutoP : 38|1@1+ (1,0) [0|1] "" XXX
 SG_ EP1_Bremslicht : 39|1@1+ (1,0) [0|1] "" XXX
 SG_ EP1_Warnton1 : 40|1@1+ (1,0) [0|1] "" XXX
 SG_ EP1_Warnton2 : 41|1@1+ (1,0) [0|1] "" XXX
 SG_ EP1_AnfShLock : 42|1@1+ (1,0) [0|1] "" XXX
 SG_ EPB_Autoholdlampe : 43|1@1+ (1,0) [0|1] "" XXX
 SG_ EP1_QualNeigWi : 44|1@1+ (1,0) [0|1] "" XXX
 SG_ EP1_KuppModBer : 45|2@1+ (1,0) [0|3] "" XXX
 SG_ EP1_HydrHalten : 47|1@1+ (1,0) [0|1] "" XXX
 SG_ EP1_Fkt_Lampe : 48|1@1+ (1,0) [0|1] "" Vector__XXX
 SG_ EP1_Warnton : 49|1@1+ (1,0) [0|1] "" XXX
 SG_ EP1_Fehler_BKL : 50|1@1+ (1,0) [0|1] "" Vector__XXX
 SG_ EP1_Fehler_gelb : 51|1@1+ (1,0) [0|1] "" XXX
 SG_ EP1__Text : 52|4@1+ (1,0) [0|8] "" Vector__XXX
 SG_ CHECKSUM : 56|8@1+ (1,0) [0|255] "" XXX

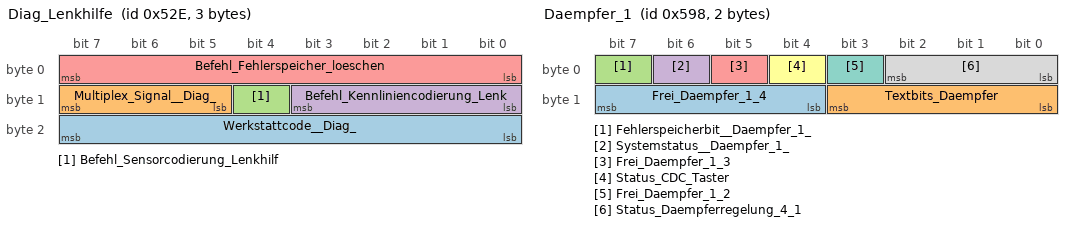
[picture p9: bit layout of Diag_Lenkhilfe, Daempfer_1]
BO_ 1326 Diag_Lenkhilfe: 3 XXX
 SG_ Werkstattcode__Diag_ : 16|8@1+ (1,0) [0|0] "" XXX
 SG_ Multiplex_Signal__Diag_ : 13|3@1+ (1,0) [0|7] "" XXX
 SG_ Befehl_Sensorcodierung_Lenkhilf : 12|1@1+ (1,0) [0|0] "" XXX
 SG_ Befehl_Kennliniencodierung_Lenk : 8|4@1+ (1,0) [0|0] "" XXX
 SG_ Befehl_Fehlerspeicher_loeschen : 0|8@1+ (1,0) [0|0] "" XXX

BO_ 1432 Daempfer_1: 2 XXX
 SG_ Frei_Daempfer_1_4 : 12|4@1+ (1,0) [0|0] "" XXX
 SG_ Textbits_Daempfer : 8|4@1+ (1,0) [0|0] "" XXX
 SG_ Fehlerspeicherbit__Daempfer_1_ : 7|1@1+ (1,0) [0|0] "" XXX
 SG_ Systemstatus__Daempfer_1_ : 6|1@1+ (1,0) [0|0] "" XXX
 SG_ Frei_Daempfer_1_3 : 5|1@1+ (1,0) [0|0] "" XXX
 SG_ Status_CDC_Taster : 4|1@1+ (1,0) [0|0] "" XXX
 SG_ Frei_Daempfer_1_2 : 3|1@1+ (1,0) [0|0] "" XXX
 SG_ Status_Daempferregelung_4_1 : 0|3@1+ (1,0) [0|7] "" XXX

BO_ 1392 BSG_Last: 4 XXX
 SG_ Klimaanlage_abschalten : 31|1@1+ (1,0) [0|0] "" XXX
 SG_ Sitzbelueftung_abschalten : 30|1@1+ (1,0) [0|0] "" XXX
 SG_ Wischwasserheizung_abschalten : 29|1@1+ (1,0) [0|0] "" XXX
 SG_ Lenkradheizung_abschalten : 28|1@1+ (1,0) [0|0] "" XXX
 SG_ Heizbare_Sitze_abschalten : 27|1@1+ (1,0) [0|0] "" XXX
 SG_ Heizbare_Aussenspiegel_abschalt : 26|1@1+ (1,0) [0|0] "" XXX
 SG_ Heizbare_Frontscheibe_abschalte : 25|1@1+ (1,0) [0|0] "" XXX
 SG_ Heizbare_Heckscheibe_abschalten : 24|1@1+ (1,0) [0|0] "" XXX
 SG_ Batteriespannung_Bordnetzbatter : 16|8@1+ (0.05,5) [5|17.7] "V" XXX
 SG_ Motorhaubenkontakt : 15|1@1+ (1,0) [0|0] "" XXX
 SG_ Leuchtweitenregulierung : 14|1@1+ (1,0) [0|0] "" XXX
 SG_ Fehlerspeichereintrag__BSG_Last : 13|1@1+ (1,0) [0|0] "" XXX
 SG_ Zustand_der_Starterbatterie : 11|2@1+ (1,0) [0|0] "" XXX
 SG_ Zustand_der_Bordnetzbatterie : 9|2@1+ (1,0) [0|0] "" XXX
 SG_ LL_Drehzahlanhebung : 8|1@1+ (1,0) [0|0] "" XXX
 SG_ Klemme_L : 7|1@1+ (1,0) [0|0] "" XXX
 SG_ Frei_BSG_Last_1_1 : 4|3@1+ (1,0) [0|0] "" XXX
 SG_ ZAS_Klemme_50 : 3|1@1+ (1,0) [0|0] "" XXX
 SG_ ZAS_Klemme_X : 2|1@1+ (1,0) [0|0] "" XXX
 SG_ ZAS_Klemme_15 : 1|1@1+ (1,0) [0|0] "" XXX
 SG_ ZAS_Klemme_S : 0|1@1+ (1,0) [0|0] "" XXX

BO_ 1136 BSG_Kombi: 5 XXX
 SG_ Frei_BSG_Kombi_1_3 : 36|4@1+ (1,0) [0|0] "" XXX
 SG_ Ruecksitzlehne_HR_verr__4_1 : 35|1@1+ (1,0) [0|0] "" XXX
 SG_ Ruecksitzlehne_HL_verr__4_1 : 34|1@1+ (1,0) [0|0] "" XXX
 SG_ Fehlerlampe_Lenkhilfe_veraltet : 33|1@1+ (1,0) [0|0] "" XXX
 SG_ Fehlerlampe_Lenkhilfe__BSG_Komb : 32|1@1+ (1,0) [0|0] "" XXX
 SG_ Fehlerstatus_Kl__58s : 31|1@1+ (1,0) [0|0] "" XXX
 SG_ Klemme_58s__BSG_Kombi_ : 24|7@1+ (1,0) [0|100] "%" XXX
 SG_ Fehlerstatus_Kl__58d : 23|1@1+ (1,0) [0|0] "" XXX
 SG_ Klemme_58d__BSG_Kombi_ : 16|7@1+ (1,0) [0|100] "%" XXX
 SG_ Unterspannung : 15|1@1+ (1,0) [0|0] "" XXX
 SG_ Frei_BSG_Kombi_1_2 : 14|1@1+ (1,0) [0|0] "" XXX
 SG_ Heckdeckel_geoeffnet : 13|1@1+ (1,0) [0|0] "" XXX
 SG_ Motorhaube_geoeffnet : 12|1@1+ (1,0) [0|0] "" XXX
 SG_ Tuer_hinten_rechts_geoeffnet : 11|1@1+ (1,0) [0|0] "" XXX
 SG_ Tuer_hinten_links_geoeffnet : 10|1@1+ (1,0) [0|0] "" XXX
 SG_ Beifahrertuer_geoeffnet : 9|1@1+ (1,0) [0|0] "" XXX
 SG_ Fahrertuer_geoeffnet : 8|1@1+ (1,0) [0|0] "" XXX
 SG_ Lade_Kontrollampe : 7|1@1+ (1,0) [0|0] "" XXX
 SG_ Frei_BSG_Kombi_1_1 : 6|1@1+ (1,0) [0|0] "" XXX
 SG_ Rueckfahrlicht : 5|1@1+ (1,0) [0|0] "" XXX
 SG_ DWA_Akku : 4|1@1+ (1,0) [0|0] "" XXX
 SG_ Warnblink_Mode : 3|1@1+ (1,0) [0|0] "" XXX
 SG_ Anhaenger_Kontrollampe : 2|1@1+ (1,0) [0|0] "" XXX
 SG_ Blinker_rechts_Kontrollampe : 1|1@1+ (1,0) [0|0] "" XXX
 SG_ Blinker_links_Kontrollampe : 0|1@1+ (1,0) [0|0] "" XXX

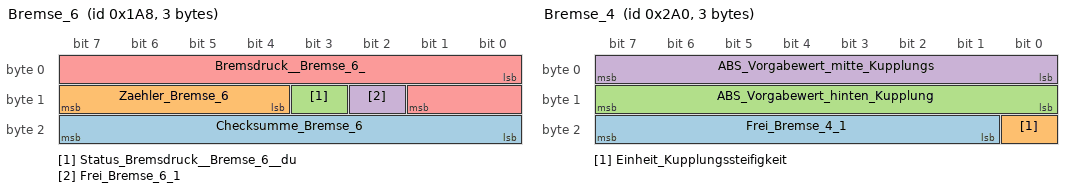
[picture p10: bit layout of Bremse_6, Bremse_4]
BO_ 424 Bremse_6: 3 XXX
 SG_ Checksumme_Bremse_6 : 16|8@1+ (1,0) [0|0] "" XXX
 SG_ Zaehler_Bremse_6 : 12|4@1+ (1,0) [0|15] "" XXX
 SG_ Status_Bremsdruck__Bremse_6__du : 11|1@1+ (1,0) [0|0] "" XXX
 SG_ Frei_Bremse_6_1 : 10|1@1+ (1,0) [0|0] "" XXX
 SG_ Bremsdruck__Bremse_6_ : 0|10@1+ (0.3255,-40) [-40|293] "bar" XXX

BO_ 1192 Bremse_5: 8 XXX
 SG_ CHECKSUM : 56|8@1+ (1,0) [0|0] "" XXX
 SG_ COUNTER : 52|4@1+ (1,0) [0|15] "" XXX
 SG_ BR5_ECD_Lampe : 51|1@1+ (1,0) [0|0] "" XXX
 SG_ BR5_ZT_Rueckk_Umsetz : 48|1@1+ (1,0) [0|1] "" XXX
 SG_ BR5_Anhi_Sta : 40|1@1+ (1,0) [0|1] "" XXX
 SG_ ESP_Rollenmodus_Deactiveieren : 34|1@1+ (1,0) [0|1] "" XXX
 SG_ BR5_Sign_Druck : 31|1@1+ (1,0) [0|1] "" XXX
 SG_ BR5_Sta_Druck : 30|1@1+ (1,0) [0|1] "" XXX
 SG_ BR5_Druckvalid : 29|1@1+ (1,0) [0|1] "" XXX
 SG_ BR5_Stillstand : 28|1@1+ (1,0) [0|1] "" XXX
 SG_ BR5_Bremsdruck : 16|12@1+ (0.1,0) [0|250] "bar" XXX
 SG_ BR5_Vorzeichen : 15|1@1+ (1,0) [0|1] "" XXX
 SG_ BR5_Sta_Gierrate : 14|1@1+ (1,0) [0|1] "" XXX
 SG_ BR5_Giergeschw : 0|14@1+ (0.01,0) [0|100] "Grad/sec" XXX
 SG_ BR5_ANB_CM_Rueckk_Umsetz : 49|1@1+ (1,0) [0|1] "" XXX
 SG_ BR5_HDC_bereit : 50|1@1+ (1,0) [0|1] "" XXX
 SG_ ESP_Stat_FallBack_eBKV : 35|1@1+ (1,0) [0|1] "" XXX
 SG_ ESP_Anforderung_EPB : 36|2@1+ (1,0) [0|3] "" XXX
 SG_ ESP_Autohold_active : 38|1@1+ (1,0) [0|1] "" XXX
 SG_ ESP_Autohold_Standby : 39|1@1+ (1,0) [0|1] "" XXX
 SG_ BR5_Anhi_akt : 41|1@1+ (1,0) [0|1] "" XXX
 SG_ BR5_v_Ueberw : 42|1@1+ (1,0) [0|1] "" XXX
 SG_ BR5_Bremslicht : 43|1@1+ (1,0) [0|1] "" XXX
 SG_ BR5_Notbremsung : 44|1@1+ (1,0) [0|1] "" XXX
 SG_ BR5_Fahrer_tritt_ZBR_Schw : 45|1@1+ (1,0) [0|1] "" XXX
 SG_ BR5_AWV2_Bremsruck : 46|1@1+ (1,0) [0|1] "" XXX
 SG_ BR5_AWV2_Fehler : 47|1@1+ (1,0) [0|1] "" XXX

BO_ 672 Bremse_4: 3 XXX
 SG_ Frei_Bremse_4_1 : 17|7@1+ (1,0) [0|0] "" XXX
 SG_ Einheit_Kupplungssteifigkeit : 16|1@1+ (1,0) [0|0] "" XXX
 SG_ ABS_Vorgabewert_hinten_Kupplung : 8|8@1+ (0.7874,0) [0|100] "%" XXX
 SG_ ABS_Vorgabewert_mitte_Kupplungs : 0|8@1+ (3,-381) [-381|378] "Nm/min" XXX

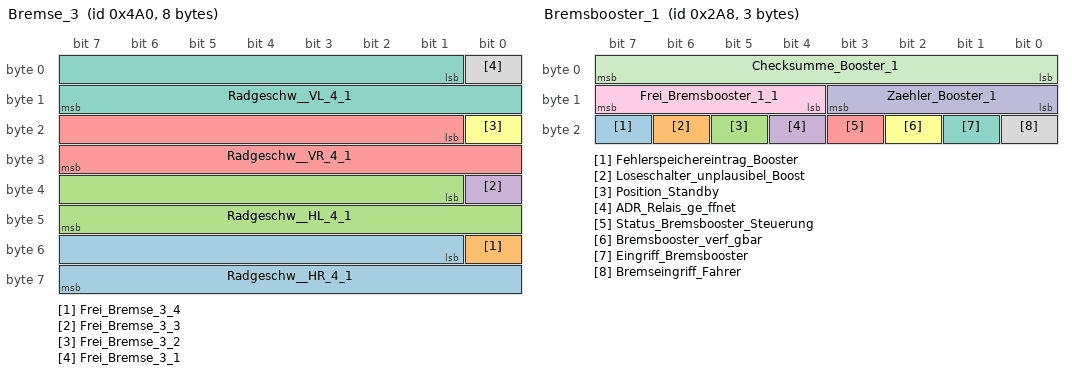
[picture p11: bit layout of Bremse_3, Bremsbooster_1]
BO_ 1184 Bremse_3: 8 XXX
 SG_ Radgeschw__HR_4_1 : 49|15@1+ (0.01,0) [0|326] "km/h" XXX
 SG_ Frei_Bremse_3_4 : 48|1@1+ (1,0) [0|0] "" XXX
 SG_ Radgeschw__HL_4_1 : 33|15@1+ (0.01,0) [0|326] "km/h" XXX
 SG_ Frei_Bremse_3_3 : 32|1@1+ (1,0) [0|0] "" XXX
 SG_ Radgeschw__VR_4_1 : 17|15@1+ (0.01,0) [0|326] "km/h" XXX
 SG_ Frei_Bremse_3_2 : 16|1@1+ (0.01,0) [0|325] "km/h" XXX
 SG_ Radgeschw__VL_4_1 : 1|15@1+ (0.01,0) [0|326] "km/h" XXX
 SG_ Frei_Bremse_3_1 : 0|1@1+ (1,0) [0|0] "" XXX

BO_ 1440 Bremse_2: 8 XXX
 SG_ gemessene_Querbeschleunigung : 63|1@1+ (1,0) [0|0] "" XXX
 SG_ Frei_Bremse_2_2 : 62|1@1+ (1,0) [0|0] "" XXX
 SG_ Impulszahl : 56|6@1+ (1,0) [0|63] "" XXX
 SG_ Fehlerstatus_Wegimpulse_4_1 : 55|1@1+ (1,0) [0|0] "" XXX
 SG_ Frei_Bremse_2_5 : 54|1@1+ (1,0) [0|0] "" XXX
 SG_ Warnlampe_DDS : 53|1@1+ (1,0) [0|0] "" XXX
 SG_ Fehlerspeichereintrag_Bremse : 52|1@1+ (1,0) [0|0] "" XXX
 SG_ Wegimpulszaehlerstatus : 51|1@1+ (1,0) [0|0] "" XXX
 SG_ Wegimpulse_Vorderachse : 40|11@1+ (1,0) [0|2047] "" XXX
 SG_ Zeitstempel : 24|16@1+ (1,0) [0|65535] "tics" XXX
 SG_ mittlere_Raddrehzahl__Bremse_2 : 9|15@1+ (0.002,0) [0|65.278] "U/sec" XXX
 SG_ Querbeschl__TimerTic M : 8|1@1+ (1,0) [0|0] "" XXX
 SG_ Timer m1 : 0|8@1+ (0.04,0) [0|10.2] "usec" XXX
 SG_ Querbeschleunigung m0 : 0|8@1+ (0.01,-1.27) [-1.27|1.27] "g" XXX

BO_ 416 Bremse_1: 8 ABS
 SG_ BR1_ASR_Anf : 0|1@1+ (1,0) [0|1] "" Motor
 SG_ BR1_MSR_Anf M : 1|1@1+ (1,0) [0|1] "" Motor
 SG_ BR1_ABS_Brems : 2|1@1+ (1,0) [0|1] "" XXX
 SG_ BR1_EDS_Ongr : 3|1@1+ (1,0) [0|1] "" XXX
 SG_ BR1_ESP_Ongr : 4|1@1+ (1,0) [0|1] "" XXX
 SG_ BR1_ASR_Ongr : 5|2@1+ (1,0) [0|3] "" Transmission
 SG_ BR1_EBV_Ongr : 7|1@1+ (1,0) [0|1] "" XXX
 SG_ BR1_Lampe_ABS : 8|1@1+ (1,0) [0|1] "" XXX
 SG_ BR1_Lampe_ASR : 9|1@1+ (1,0) [0|1] "" XXX
 SG_ BR1_Lampe_BK : 10|1@1+ (1,0) [0|1] "" XXX
 SG_ BR1_Lichtschalt : 11|1@1+ (1,0) [0|1] "" XXX
 SG_ BR1_StaDruckschw : 12|1@1+ (1,0) [0|1] "" XXX
 SG_ BR1_MAD : 13|1@1+ (1,0) [0|1] "" XXX
 SG_ BR1_Sta_MAD : 14|1@1+ (1,0) [0|1] "" XXX
 SG_ BR1_Diagnose : 15|1@1+ (1,0) [0|1] "" XXX
 SG_ BR1_BKV_active : 16|1@1+ (1,0) [0|1] "" XXX
 SG_ BR1_Rad_kmh : 17|15@1+ (0.01,0) [0|326.39] "km/h" XXX
 SG_ BR1_ASRMo_sl : 32|8@1+ (0.39,0) [0|99.06] "%" Motor
 SG_ BR1_ASRMo_fa m0 : 40|8@1+ (0.39,0) [0|99.06] "%" Motor
 SG_ BR1_MSR_Mo_inv m1 : 40|8@1+ (-0.39,99.45) [0|99.06] "%" Motor
 SG_ BR1_MSR_Mo : 48|8@1+ (0.39,0) [0|99.06] "%" Motor
 SG_ BR1_Zaehler : 56|4@1+ (1,0) [0|15] "" XXX
 SG_ BR1_ASR_ESP : 60|1@1+ (1,0) [0|1] "" XXX
 SG_ BR1_ESPASR_passive : 61|1@1+ (1,0) [0|1] "" XXX
 SG_ BR1_Sta_ESP : 62|1@1+ (1,0) [0|1] "" XXX
 SG_ BR1_Ersatz_Kmh : 63|1@1+ (1,0) [0|1] "" XXX

BO_ 680 Bremsbooster_1: 3 XXX
 SG_ Fehlerspeichereintrag_Booster : 23|1@1+ (1,0) [0|0] "" XXX
 SG_ Loseschalter_unplausibel_Boost : 22|1@1+ (1,0) [0|0] "" XXX
 SG_ Position_Standby : 21|1@1+ (1,0) [0|0] "" XXX
 SG_ ADR_Relais_ge_ffnet : 20|1@1+ (1,0) [0|0] "" XXX
 SG_ Status_Bremsbooster_Steuerung : 19|1@1+ (1,0) [0|0] "" XXX
 SG_ Bremsbooster_verf_gbar : 18|1@1+ (1,0) [0|0] "" XXX
 SG_ Eingriff_Bremsbooster : 17|1@1+ (1,0) [0|0] "" XXX
 SG_ Bremseingriff_Fahrer : 16|1@1+ (1,0) [0|0] "" XXX
 SG_ Frei_Bremsbooster_1_1 : 12|4@1+ (1,0) [0|0] "" XXX
 SG_ Zaehler_Booster_1 : 8|4@1+ (1,0) [0|15] "" XXX
 SG_ Checksumme_Booster_1 : 0|8@1+ (1,0) [0|0] "" XXX

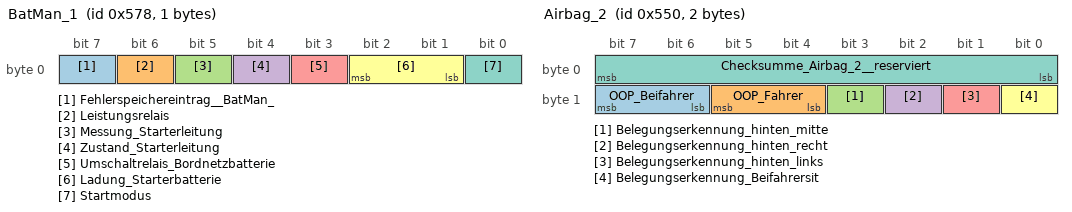
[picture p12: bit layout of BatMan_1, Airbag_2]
BO_ 1400 BatMan_1: 1 XXX
 SG_ Fehlerspeichereintrag__BatMan_ : 7|1@1+ (1,0) [0|0] "" XXX
 SG_ Leistungsrelais : 6|1@1+ (1,0) [0|0] "" XXX
 SG_ Messung_Starterleitung : 5|1@1+ (1,0) [0|0] "" XXX
 SG_ Zustand_Starterleitung : 4|1@1+ (1,0) [0|0] "" XXX
 SG_ Umschaltrelais_Bordnetzbatterie : 3|1@1+ (1,0) [0|0] "" XXX
 SG_ Ladung_Starterbatterie : 1|2@1+ (1,0) [0|0] "" XXX
 SG_ Startmodus : 0|1@1+ (1,0) [0|0] "" XXX

BO_ 704 Allrad_1: 5 XXX
 SG_ Kupplungssteifigkeit_Hinten__Is : 32|8@1+ (0.7874,0) [0|100] "%" XXX
 SG_ Fehlerspeichereintrag_Allrad_1 : 31|1@1+ (1,0) [0|0] "" XXX
 SG_ Frei_Allrad_1_1 : 26|5@1+ (1,0) [0|0] "" XXX
 SG_ Schaltung_Vorwarnung : 25|1@1+ (1,0) [0|0] "" XXX
 SG_ Schaltung_aktiv__Allrad_1_ : 24|1@1+ (1,0) [0|0] "" XXX
 SG_ Ganginfo__PNG_ : 20|4@1+ (1,0) [0|0] "" XXX
 SG_ PNG_Anzeige_blinkend : 19|1@1+ (1,0) [0|0] "" XXX
 SG_ PNG_Status_4_1 : 16|3@1+ (1,0) [0|0] "" XXX
 SG_ Kupplungssteifigkeit_Mitte__Ist : 8|8@1+ (3,-381) [-381|378] "Nm/min" XXX
 SG_ Einheit_der_Kupplungssteifigkei : 7|1@1+ (1,0) [0|0] "" XXX
 SG_ Geschwindigkeitsbegrenzung : 6|1@1+ (1,0) [0|0] "" XXX
 SG_ Allrad_Warnlampe : 5|1@1+ (1,0) [0|0] "" XXX
 SG_ Notlauf : 4|1@1+ (1,0) [0|0] "" XXX
 SG_ Kupplung_komplett_offen : 3|1@1+ (1,0) [0|0] "" XXX
 SG_ Fehlerstatus_Kupplungssteifigke : 2|1@1+ (1,0) [0|0] "" XXX
 SG_ Ubertemperaturschutz__Allrad_1_ : 1|1@1+ (1,0) [0|0] "" XXX
 SG_ Fehler_Allrad_Kupplung : 0|1@1+ (1,0) [0|0] "" XXX

BO_ 1360 Airbag_2: 2 XXX
 SG_ OOP_Beifahrer : 14|2@1+ (1,0) [0|0] "" XXX
 SG_ OOP_Fahrer : 12|2@1+ (1,0) [0|0] "" XXX
 SG_ Belegungserkennung_hinten_mitte : 11|1@1+ (1,0) [0|0] "" XXX
 SG_ Belegungserkennung_hinten_recht : 10|1@1+ (1,0) [0|0] "" XXX
 SG_ Belegungserkennung_hinten_links : 9|1@1+ (1,0) [0|0] "" XXX
 SG_ Belegungserkennung_Beifahrersit : 8|1@1+ (1,0) [0|0] "" XXX
 SG_ Checksumme_Airbag_2__reserviert : 0|8@1+ (1,0) [0|0] "" XXX

BO_ 80 Airbag_1: 4 XXX
 SG_ CHECKSUM : 24|8@1+ (1,0) [0|0] "" XXX
 SG_ COUNTER : 20|4@1+ (1,0) [0|15] "" XXX
 SG_ Fehlerspeichereintrag : 19|1@1+ (1,0) [0|0] "" XXX
 SG_ Frei_Airbag_1_2 : 18|1@1+ (1,0) [0|0] "" XXX
 SG_ Airbag_im_Stellgliedtest : 17|1@1+ (1,0) [0|0] "" XXX
 SG_ Airbag_in_Diagnose : 16|1@1+ (1,0) [0|0] "" XXX
 SG_ Gurtwarnung_Beifahrer : 15|1@1+ (1,0) [0|0] "" XXX
 SG_ Gurtschalter_Beifahrer : 14|1@1+ (1,0) [0|0] "" XXX
 SG_ Gurtwarnung_Fahrer : 13|1@1+ (1,0) [0|0] "" XXX
 SG_ Gurtschalter_Fahrer : 12|1@1+ (1,0) [0|0] "" XXX
 SG_ Airbag_Systemfehler : 11|1@1+ (1,0) [0|0] "" XXX
 SG_ Kindersitzerkennung : 10|1@1+ (1,0) [0|0] "" XXX
 SG_ Airbag_deaktiviert : 9|1@1+ (1,0) [0|0] "" XXX
 SG_ Airbag_Lampe : 8|1@1+ (1,0) [0|0] "" XXX
 SG_ Crash_Intensitaet : 5|3@1+ (1,0) [0|111] "B" XXX
 SG_ Rollover : 4|1@1+ (1,0) [0|0] "" XXX
 SG_ Seiten_Crash_Beifahrer : 3|1@1+ (1,0) [0|0] "" XXX
 SG_ Seiten_Crash_Fahrer : 2|1@1+ (1,0) [0|0] "" XXX
 SG_ Heck_Crash : 1|1@1+ (1,0) [0|0] "" XXX
 SG_ Front_Crash : 0|1@1+ (1,0) [0|0] "" XXX

BO_ 864 ADR_System: 8 XXX
 SG_ S_Checksumme_ADR_1 : 56|8@1+ (1,0) [0|0] "" XXX
 SG_ S_Frei_ADR_1_1 : 52|4@1+ (1,0) [0|0] "" XXX
 SG_ S_Zeitluecke_gemessen : 48|4@1+ (1,0) [0|15] "" XXX
 SG_ S_Fehlerspeichereintrag_ADR : 47|1@1+ (1,0) [0|0] "" XXX
 SG_ S_Fehlerspeichereintrag_Bremsbo : 46|1@1+ (1,0) [0|0] "" XXX
 SG_ S_ADR_Relais_geoeffnet : 45|1@1+ (1,0) [0|0] "" XXX
 SG_ S_Bremsbooster_Status : 43|2@1+ (1,0) [0|0] "" XXX
 SG_ S_Eingriff_Bremsbooster : 42|1@1+ (1,0) [0|0] "" XXX
 SG_ S_Loeseschalter_unplausibel : 41|1@1+ (1,0) [0|0] "" XXX
 SG_ S_Bremseingriff_Fahrer : 40|1@1+ (1,0) [0|0] "" XXX
 SG_ S_Anzeige_Sensor_blind : 39|1@1+ (1,0) [0|0] "" XXX
 SG_ S_Ansteuerung_optischer_Fahrerh : 38|1@1+ (1,0) [0|0] "" XXX
 SG_ S_Ansteuerung_Gong_2 : 37|1@1+ (1,0) [0|0] "" XXX
 SG_ S_Ansteuerung_Gong_1 : 36|1@1+ (1,0) [0|0] "" XXX
 SG_ S_Schaltaufforderung : 34|2@1+ (1,0) [0|0] "" XXX
 SG_ S_Anzeige_Prioritaet : 33|1@1+ (1,0) [0|0] "" XXX
 SG_ S_Anzeige_Zeitluecke : 32|1@1+ (1,0) [0|0] "" XXX
 SG_ S_Wunschgeschwindigkeit : 24|8@1+ (1,0) [0|254] "km/h" XXX
 SG_ S_Objekt_erfasst : 22|2@1+ (1,0) [0|0] "" XXX
 SG_ S_Gesetzte_Zeitluecke__ADR_1_ : 18|4@1+ (1,0) [0|15] "" XXX
 SG_ S_Synchronisation_Bremsbooster : 17|1@1+ (1,0) [0|0] "" XXX
 SG_ S_Momentenanforderung_Freigabe : 16|1@1+ (1,0) [0|0] "" XXX
 SG_ S_Verhinderung_Schubabschaltung : 15|1@1+ (1,0) [0|0] "" XXX
 SG_ S_Status_ADR_1__S_ : 13|2@1+ (1,0) [0|0] "" XXX
 SG_ S_Fehler_ADR_1__S_ : 12|1@1+ (1,0) [0|0] "" XXX
 SG_ S_Zaehler_ADR_1 : 8|4@1+ (1,0) [0|15] "" XXX
 SG_ S_Momentenanforderung_ADR : 0|8@1+ (0.39,0) [0|99] "MDI" XXX

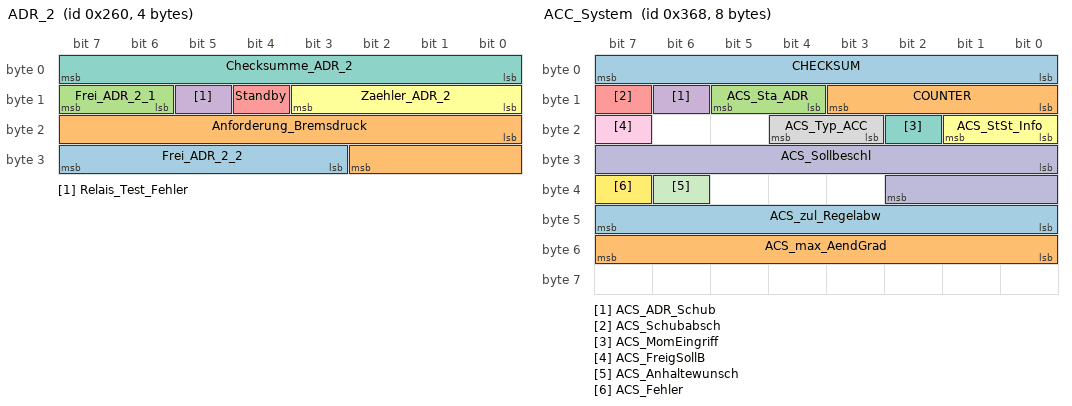
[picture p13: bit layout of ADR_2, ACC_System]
BO_ 608 ADR_2: 4 XXX
 SG_ Frei_ADR_2_2 : 27|5@1+ (1,0) [0|0] "" XXX
 SG_ Anforderung_Bremsdruck : 16|11@1+ (0.0625,0) [0|127.9375] "bar" XXX
 SG_ Frei_ADR_2_1 : 14|2@1+ (1,0) [0|0] "" XXX
 SG_ Relais_Test_Fehler : 13|1@1+ (1,0) [0|0] "" XXX
 SG_ Standby : 12|1@1+ (1,0) [0|0] "" XXX
 SG_ Zaehler_ADR_2 : 8|4@1+ (1,0) [0|15] "" XXX
 SG_ Checksumme_ADR_2 : 0|8@1+ (1,0) [0|0] "" XXX

BO_ 1324 ADR_1: 8 XXX
 SG_ Checksumme_ADR_1 : 56|8@1+ (1,0) [0|0] "" XXX
 SG_ Frei_ADR_1_5 : 52|4@1+ (1,0) [0|0] "" XXX
 SG_ Zeitluecke_gemessen : 48|4@1+ (1,0) [0|15] "" XXX
 SG_ Fehlerspeichereintrag_ADR : 47|1@1+ (1,0) [0|0] "" XXX
 SG_ Reserviert_ADR_1_1 : 40|7@1+ (1,0) [0|0] "" XXX
 SG_ Anzeige_Sensor_blind : 39|1@1+ (1,0) [0|0] "" XXX
 SG_ Ansteuerung_optischer_Fahrerhin : 38|1@1+ (1,0) [0|0] "" XXX
 SG_ Ansteuerung_Gong_2 : 37|1@1+ (1,0) [0|0] "" XXX
 SG_ Ansteuerung_Gong_1 : 36|1@1+ (1,0) [0|0] "" XXX
 SG_ Schaltaufforderung : 34|2@1+ (1,0) [0|0] "" XXX
 SG_ Anzeige_Prioritaet : 33|1@1+ (1,0) [0|0] "" XXX
 SG_ Anzeige_Zeitluecke : 32|1@1+ (1,0) [0|0] "" XXX
 SG_ Wunschgeschwindigkeit : 24|8@1+ (1,0) [0|254] "km/h" XXX
 SG_ Objekt_erfasst : 22|2@1+ (1,0) [0|0] "" XXX
 SG_ Gesetzte_Zeitluecke__ADR_1_ : 18|4@1+ (1,0) [0|15] "" XXX
 SG_ Synchronisation_Bremsbooster : 17|1@1+ (1,0) [0|0] "" XXX
 SG_ Momentenanforderung_Freigabe : 16|1@1+ (1,0) [0|0] "" XXX
 SG_ Verhinderung_Schubabschaltung : 15|1@1+ (1,0) [0|0] "" XXX
 SG_ Status_ADR_1 : 13|2@1+ (1,0) [0|0] "" XXX
 SG_ Fehler_ADR_1 : 12|1@1+ (1,0) [0|0] "" XXX
 SG_ Zaehler_ADR_1 : 8|4@1+ (1,0) [0|15] "" XXX
 SG_ Momentenanforderung_ADR : 0|8@1+ (0.39,0) [0|99] "MDI" XXX

BO_ 1550 Einheiten_1: 2 XXX
 SG_ MFA_v_Einheit_02 : 0|1@1+ (1,0) [0|1] "" XXX

BO_ 872 ACC_System: 8 XXX
 SG_ CHECKSUM : 0|8@1+ (1,0) [0|255] "" XXX
 SG_ COUNTER : 8|4@1+ (1,0) [0|15] "" XXX
 SG_ ACS_Sta_ADR : 12|2@1+ (1,0) [0|3] "" XXX
 SG_ ACS_ADR_Schub : 14|1@1+ (1,0) [0|1] "" XXX
 SG_ ACS_Schubabsch : 15|1@1+ (1,0) [0|1] "" XXX
 SG_ ACS_StSt_Info : 16|2@1+ (1,0) [0|3] "" XXX
 SG_ ACS_MomEingriff : 18|1@1+ (1,0) [0|1] "" XXX
 SG_ ACS_Typ_ACC : 19|2@1+ (1,0) [0|3] "" XXX
 SG_ ACS_FreigSollB : 23|1@1+ (1,0) [0|1] "" XXX
 SG_ ACS_Sollbeschl : 24|11@1+ (0.005,-7.22) [-7.22|3.005] "Unit_MeterPerSeconSquar" XXX
 SG_ ACS_Anhaltewunsch : 38|1@1+ (1,0) [0|1] "" XXX
 SG_ ACS_Fehler : 39|1@1+ (1,0) [0|1] "" XXX
 SG_ ACS_zul_Regelabw : 40|8@1+ (0.005,0) [0|1.265] "Unit_MeterPerSeconSquar" XXX
 SG_ ACS_max_AendGrad : 48|8@1+ (0.02,0) [0.02|5.06] "Unit_MeterPerSeconSquar" XXX

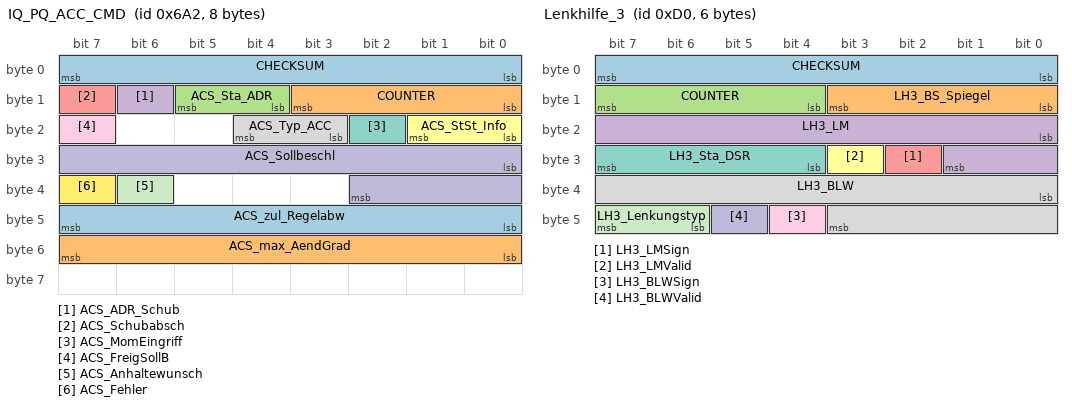
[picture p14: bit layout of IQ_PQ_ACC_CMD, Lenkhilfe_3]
BO_ 1698 IQ_PQ_ACC_CMD: 8 XXX
 SG_ CHECKSUM : 0|8@1+ (1,0) [0|255] "" XXX
 SG_ COUNTER : 8|4@1+ (1,0) [0|15] "" XXX
 SG_ ACS_Sta_ADR : 12|2@1+ (1,0) [0|3] "" XXX
 SG_ ACS_ADR_Schub : 14|1@1+ (1,0) [0|1] "" XXX
 SG_ ACS_Schubabsch : 15|1@1+ (1,0) [0|1] "" XXX
 SG_ ACS_StSt_Info : 16|2@1+ (1,0) [0|3] "" XXX
 SG_ ACS_MomEingriff : 18|1@1+ (1,0) [0|1] "" XXX
 SG_ ACS_Typ_ACC : 19|2@1+ (1,0) [0|3] "" XXX
 SG_ ACS_FreigSollB : 23|1@1+ (1,0) [0|1] "" XXX
 SG_ ACS_Sollbeschl : 24|11@1+ (0.005,-7.22) [-7.22|3.005] "Unit_MeterPerSeconSquar" XXX
 SG_ ACS_Anhaltewunsch : 38|1@1+ (1,0) [0|1] "" XXX
 SG_ ACS_Fehler : 39|1@1+ (1,0) [0|1] "" XXX
 SG_ ACS_zul_Regelabw : 40|8@1+ (0.005,0) [0|1.265] "Unit_MeterPerSeconSquar" XXX
 SG_ ACS_max_AendGrad : 48|8@1+ (0.02,0) [0.02|5.06] "Unit_MeterPerSeconSquar" XXX

BO_ 1699 IQ_PQ_ACC_HUD: 8 XXX
 SG_ CHECKSUM : 0|8@1+ (1,0) [0|255] "" XXX
 SG_ ACA_StaACC : 8|3@1+ (1,0) [0|7] "" XXX
 SG_ ACA_ID_StaACC : 11|5@1+ (1,0) [0|31] "" XXX
 SG_ ACA_Fahrerhinw : 16|1@1+ (1,0) [0|1] "" XXX
 SG_ ACA_AnzDisplay : 17|1@1+ (1,0) [0|1] "" XXX
 SG_ ACA_Zeitluecke : 18|4@1+ (1,0) [0|15] "" XXX
 SG_ ACA_V_Wunsch : 24|8@1+ (1,0) [0|255] "Unit_KiloMeterPerHour" XXX
 SG_ ACA_kmh_mph : 32|1@1+ (1,0) [0|1] "" XXX
 SG_ ACA_Akustik1 : 33|1@1+ (1,0) [0|1] "" XXX
 SG_ ACA_Akustik2 : 34|1@1+ (1,0) [0|1] "" XXX
 SG_ ACA_PrioDisp : 35|2@1+ (1,0) [0|3] "" XXX
 SG_ ACA_gemZeitl : 40|4@1+ (1,0) [0|15] "" XXX
 SG_ ACA_ACC_Verz : 44|1@1+ (1,0) [0|1] "" XXX
 SG_ ACA_StaGRA : 48|3@1+ (1,0) [0|7] "" XXX
 SG_ ACA_ID_StaGRA : 51|5@1+ (1,0) [0|31] "" XXX
 SG_ ACA_Codierung : 56|1@1+ (1,0) [0|1] "" XXX
 SG_ ACA_Tachokranz : 57|1@1+ (1,0) [0|1] "" XXX
 SG_ ACA_Aend_Zeitluecke : 58|1@1+ (1,0) [0|1] "" XXX
 SG_ COUNTER : 60|4@1+ (1,0) [0|15] "" XXX

BO_ 1386 ACC_GRA_Anzeige: 8 XXX
 SG_ CHECKSUM : 0|8@1+ (1,0) [0|255] "" XXX
 SG_ ACA_StaACC : 8|3@1+ (1,0) [0|7] "" XXX
 SG_ ACA_ID_StaACC : 11|5@1+ (1,0) [0|31] "" XXX
 SG_ ACA_Fahrerhinw : 16|1@1+ (1,0) [0|1] "" XXX
 SG_ ACA_AnzDisplay : 17|1@1+ (1,0) [0|1] "" XXX
 SG_ ACA_Zeitluecke : 18|4@1+ (1,0) [0|15] "" XXX
 SG_ ACA_V_Wunsch : 24|8@1+ (1,0) [0|255] "Unit_KiloMeterPerHour" XXX
 SG_ ACA_kmh_mph : 32|1@1+ (1,0) [0|1] "" XXX
 SG_ ACA_Akustik1 : 33|1@1+ (1,0) [0|1] "" XXX
 SG_ ACA_Akustik2 : 34|1@1+ (1,0) [0|1] "" XXX
 SG_ ACA_PrioDisp : 35|2@1+ (1,0) [0|3] "" XXX
 SG_ ACA_gemZeitl : 40|4@1+ (1,0) [0|15] "" XXX
 SG_ ACA_ACC_Verz : 44|1@1+ (1,0) [0|1] "" XXX
 SG_ ACA_StaGRA : 48|3@1+ (1,0) [0|7] "" XXX
 SG_ ACA_ID_StaGRA : 51|5@1+ (1,0) [0|31] "" XXX
 SG_ ACA_Codierung : 56|1@1+ (1,0) [0|1] "" XXX
 SG_ ACA_Tachokranz : 57|1@1+ (1,0) [0|1] "" XXX
 SG_ ACA_Aend_Zeitluecke : 58|1@1+ (1,0) [0|1] "" XXX
 SG_ COUNTER : 60|4@1+ (1,0) [0|15] "" XXX

BO_ 208 Lenkhilfe_3: 6 XXX
 SG_ CHECKSUM : 0|8@1+ (1,0) [0|255] "" XXX
 SG_ LH3_BS_Spiegel : 8|4@1+ (1,0) [0|15] "" XXX
 SG_ COUNTER : 12|4@1+ (1,0) [0|15] "" XXX
 SG_ LH3_LM : 16|10@1+ (1,0) [0|1023] "" XXX
 SG_ LH3_LMSign : 26|1@1+ (1,0) [0|1] "" XXX
 SG_ LH3_LMValid : 27|1@1+ (1,0) [0|1] "" XXX
 SG_ LH3_Sta_DSR : 28|4@1+ (1,0) [0|15] "" XXX
 SG_ LH3_BLW : 32|12@1+ (0.15,0) [0|615] "" XXX
 SG_ LH3_BLWSign : 44|1@1+ (1,0) [0|1] "" XXX
 SG_ LH3_BLWValid : 45|1@1+ (1,0) [0|1] "" XXX
 SG_ LH3_Lenkungstyp : 46|2@1+ (1,0) [0|3] "" XXX

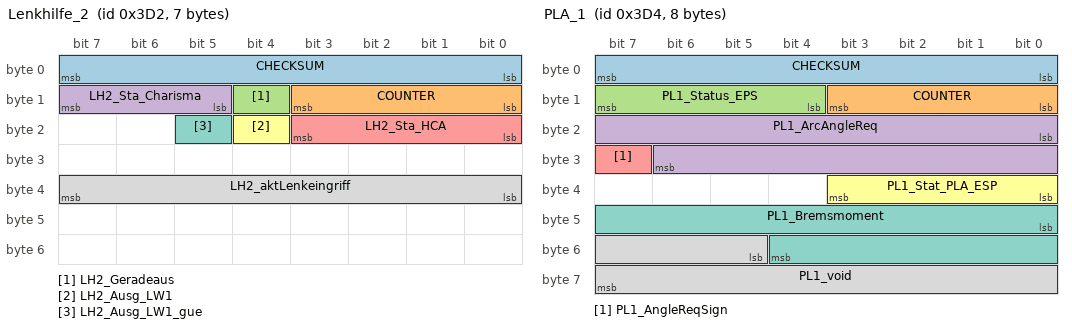
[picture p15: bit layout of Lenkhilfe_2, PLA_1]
BO_ 978 Lenkhilfe_2: 7 XXX
 SG_ CHECKSUM : 0|8@1+ (1,0) [0|255] "" XXX
 SG_ COUNTER : 8|4@1+ (1,0) [0|15] "" XXX
 SG_ LH2_Geradeaus : 12|1@1+ (1,0) [0|1] "" XXX
 SG_ LH2_Sta_Charisma : 13|3@1+ (1,0) [0|7] "" XXX
 SG_ LH2_Sta_HCA : 16|4@1+ (1,0) [0|15] "" XXX
 SG_ LH2_Ausg_LW1 : 20|1@1+ (1,0) [0|1] "" XXX
 SG_ LH2_Ausg_LW1_gue : 21|1@1+ (1,0) [0|1] "" XXX
 SG_ LH2_aktLenkeingriff : 32|8@1+ (1,0) [0|255] "" XXX

BO_ 980 PLA_1: 8 XXX
 SG_ CHECKSUM : 0|8@1+ (1,0) [0|255] "" XXX
 SG_ COUNTER : 8|4@1+ (1,0) [0|15] "" XXX
 SG_ PL1_Status_EPS : 12|4@1+ (1,0) [0|15] "" XXX
 SG_ PL1_ArcAngleReq : 16|15@1+ (0.04375,0) [0|1433.55625] "Unit_DegreeOfArc" XXX
 SG_ PL1_AngleReqSign : 31|1@1+ (1,0) [0|1] "" XXX
 SG_ PL1_Stat_PLA_ESP : 32|4@1+ (1,0) [0|10] "" Vector__XXX
 SG_ PL1_Bremsmoment : 40|13@1+ (4,0) [0|32760] "Unit_NewtoMeter" Vector__XXX
 SG_ PL1_void : 53|11@1+ (1,0) [0|2047] "" XXX

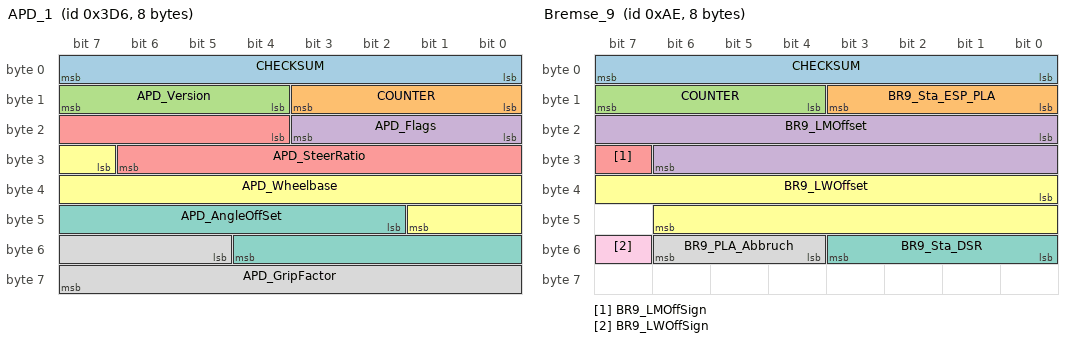
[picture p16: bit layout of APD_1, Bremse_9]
BO_ 982 APD_1: 8 XXX
 SG_ CHECKSUM : 0|8@1+ (1,0) [0|255] "" XXX
 SG_ COUNTER : 8|4@1+ (1,0) [0|15] "" XXX
 SG_ APD_Version : 12|4@1+ (1,0) [0|15] "" XXX
 SG_ APD_Flags : 16|4@1+ (1,0) [0|15] "" XXX
 SG_ APD_SteerRatio : 20|11@1+ (0.01,8) [8|28.47] "" XXX
 SG_ APD_Wheelbase : 31|11@1+ (1,2000) [2000|4047] "mm" XXX
 SG_ APD_AngleOffSet : 42|11@1+ (0.01,-10) [-10|10.47] "deg" XXX
 SG_ APD_GripFactor : 53|11@1+ (0.001,0) [0|2.047] "" XXX

BO_ 983 SNG_1: 8 XXX
 SG_ CHECKSUM : 0|8@1+ (1,0) [0|255] "" XXX
 SG_ COUNTER : 8|4@1+ (1,0) [0|15] "" XXX
 SG_ SNG_HandoffActive : 12|1@1+ (1,0) [0|1] "" XXX
 SG_ SNG_DecelReq : 16|8@1+ (0.048,-7.968) [-7.968|4.224] "Unit_MeterPerSeconSquar" XXX

BO_ 210 HCA_1: 5 XXX
 SG_ CHECKSUM : 0|8@1+ (1,0) [0|15] "" XXX
 SG_ COUNTER : 8|4@1+ (1,0) [0|15] "" XXX
 SG_ HCA_Status : 12|4@1+ (1,0) [0|15] "" XXX
 SG_ LM_Offset : 16|15@1+ (0.03125,0) [0|300] "cNm" XXX
 SG_ LW_Offset : 16|15@1+ (0.04375,0) [0|1433.55625] "Unit_DegreeOfArc" XXX
 SG_ LM_OffSign : 31|1@1+ (1,0) [0|1] "" XXX
 SG_ Vib_Freq : 32|4@1+ (4,0) [0|60] "Hz" XXX
 SG_ Vib_Amp : 36|4@1+ (0.5,0) [0|7.5] "Nm" XXX
 SG_ HCA_ALC_LW_KeyCipher : 32|8@1+ (1,0) [0|255] "" XXX

BO_ 174 Bremse_9: 8 XXX
 SG_ CHECKSUM : 0|8@1+ (1,0) [0|255] "" XXX
 SG_ BR9_Sta_ESP_PLA : 8|4@1+ (1,0) [0|15] "" XXX
 SG_ COUNTER : 12|4@1+ (1,0) [0|15] "" XXX
 SG_ BR9_LMOffset : 16|15@1+ (0.0003052,0) [0|9.9987] "Nm" XXX
 SG_ BR9_LMOffSign : 31|1@1+ (1,0) [0|1] "" XXX
 SG_ BR9_LWOffset : 32|15@1+ (0.04375,0) [0|1433.5] "deg" XXX
 SG_ BR9_Sta_DSR : 48|4@1+ (1,0) [0|15] "" XXX
 SG_ BR9_PLA_Abbruch : 52|3@1+ (1,0) [0|7] "" XXX
 SG_ BR9_LWOffSign : 55|1@1+ (1,0) [0|1] "" XXX

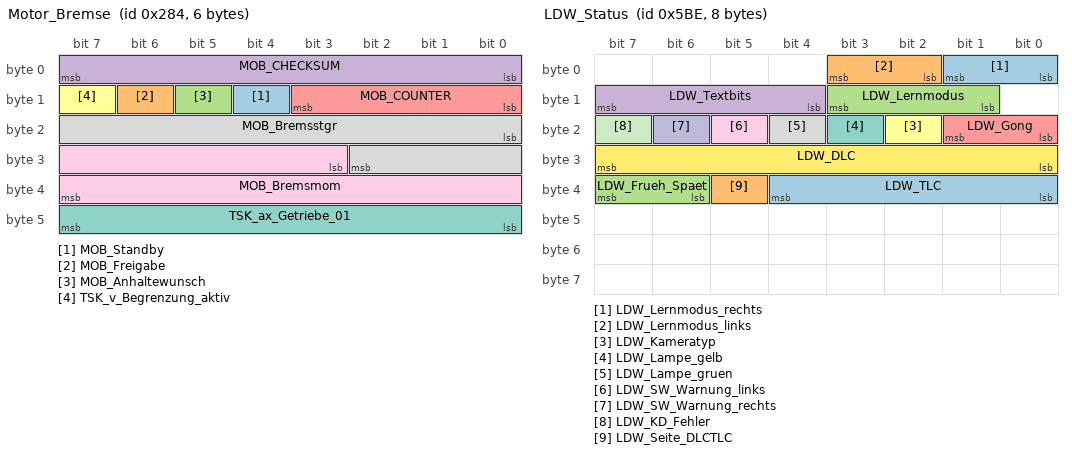
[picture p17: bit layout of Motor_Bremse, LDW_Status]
BO_ 644 Motor_Bremse: 6 XXX
 SG_ MOB_Standby : 12|1@1+ (1,0) [0|1] ""  XXX
 SG_ MOB_Freigabe : 14|1@1+ (1,0) [0|1] "" BCM_Gateway,Bremse_MK25AESP,Gateway_separat
 SG_ MOB_Anhaltewunsch : 13|1@1+ (1,0) [0|1] "" Bremse_MK25AESP,Getriebe_DQ
 SG_ MOB_CHECKSUM : 0|8@1+ (1,0) [0|255] "" Bremse_MK25AESP
 SG_ MOB_COUNTER : 8|4@1+ (1,0) [0|15] "" Bremse_MK25AESP
 SG_ TSK_v_Begrenzung_aktiv : 15|1@0+ (1,0) [0|1] "" XXX
 SG_ TSK_ax_Getriebe_01 : 40|8@1+ (0.048,0) [0|255] "m/s2" XXX
 SG_ MOB_Bremsstgr : 16|11@1+ (0.048852,0) [0|100] "Unit_PerCent" Vector__XXX
 SG_ MOB_Bremsmom : 27|13@1+ (4,0) [0|32760] "Unit_NewtoMeter"  Bremse_MK25AESP

BO_ 870 AWV: 8 XXX
 SG_ CHECKSUM : 0|8@1+ (1,0) [0|255] "" Vector__XXX
 SG_ COUNTER : 8|4@1+ (1,0) [0|15] "" Vector__XXX
 SG_ AWV_Text : 12|4@1+ (1,0) [0|14] "" Vector__XXX
 SG_ AWV_1_Freigabe : 16|1@1+ (1,0) [0|1] "" Vector__XXX
 SG_ AWV_1_Prefill : 17|1@1+ (1,0) [0|1] "" Vector__XXX
 SG_ AWV_1_Parameter : 18|2@1+ (1,0) [0|3] "" Vector__XXX
 SG_ AWV_only : 20|1@1+ (1,0) [0|1] "" Vector__XXX
 SG_ AWV_CityANB_Auspraegung : 21|1@1+ (1,0) [0|1] "" Vector__XXX
 SG_ AWV_Halten : 22|1@1+ (1,0) [0|1] "" Vector__XXX
 SG_ ANB_Teilbremsung_Freigabe : 23|1@1+ (1,0) [0|1] "" Vector__XXX
 SG_ AWV_2_Status : 24|1@1+ (1,0) [0|1] "" Vector__XXX
 SG_ AWV_2_Fehler : 25|1@1+ (1,0) [0|1] "" Vector__XXX
 SG_ AWV_2_SU_Warnzeit : 26|2@1+ (1,0) [0|3] "" Vector__XXX
 SG_ AWV_2_SU_Bremsruck : 28|1@1+ (1,0) [0|1] "" Vector__XXX
 SG_ AWV_2_SU_Gong : 29|1@1+ (1,0) [0|1] "" Vector__XXX
 SG_ AWV_2_SU_Lampe : 30|1@1+ (1,0) [0|1] "" Vector__XXX
 SG_ AWV_2_Umfeldwarn : 31|1@1+ (1,0) [0|1] "" Vector__XXX
 SG_ AWV_2_Freigabe : 32|1@1+ (1,0) [0|1] "" Vector__XXX
 SG_ AWV_2_Ruckprofil : 33|3@1+ (1,0) [0|7] "" Vector__XXX
 SG_ AWV_2_Warnton : 36|1@1+ (1,0) [0|1] "" Vector__XXX
 SG_ AWV_2_Warnsymbol : 37|1@1+ (1,0) [0|1] "" Vector__XXX
 SG_ AWV_Infoton : 38|1@1+ (1,0) [0|1] "" Vector__XXX
 SG_ AWV_2_Gurtstraffer : 39|1@1+ (1,0) [0|1] "" Vector__XXX
 SG_ AWV_Konfiguration_Menueanf : 40|1@1+ (1,0) [0|1] "" Vector__XXX
 SG_ AWV_Konfiguration_Vorw_Menueanf : 41|1@1+ (1,0) [0|1] "" Vector__XXX
 SG_ AWV_Konfiguration_Status : 42|1@1+ (1,0) [0|1] "" Vector__XXX
 SG_ AWV_Konfiguration_Vorw_Status : 43|1@1+ (1,0) [0|1] "" Vector__XXX
 SG_ AWV_2_Abstandswarnung : 51|1@1+ (1,0) [0|1] "" Vector__XXX
 SG_ ANB_Zielbremsung_Freigabe : 52|1@1+ (1,0) [0|1] "" Vector__XXX
 SG_ ANB_CM_Anforderung : 53|1@1+ (1,0) [0|1] "" Vector__XXX
 SG_ ANB_Ziel_Teilbrems_Verz_Anf : 54|10@1+ (0.024,-20.016) [0|1023] "Unit_MeterPerSeconSquar" Vector__XXX

BO_ 1470 LDW_Status: 8 XXX
 SG_ LDW_Lernmodus_rechts : 0|2@1+ (1,0) [0|3] "" XXX
 SG_ LDW_Lernmodus_links : 2|2@1+ (1,0) [0|3] "" XXX
 SG_ LDW_Lernmodus : 9|3@1+ (1,0) [0|3] "" XXX
 SG_ LDW_Textbits : 12|4@1+ (1,0) [0|15] "" XXX
 SG_ LDW_Gong : 16|2@1+ (1,0) [0|3] "" XXX
 SG_ LDW_Kameratyp : 18|1@1+ (1,0) [0|1] "" XXX
 SG_ LDW_Lampe_gelb : 19|1@1+ (1,0) [0|1] "" XXX
 SG_ LDW_Lampe_gruen : 20|1@1+ (1,0) [0|1] "" XXX
 SG_ LDW_SW_Warnung_links : 21|1@1+ (1,0) [0|1] "" XXX
 SG_ LDW_SW_Warnung_rechts : 22|1@1+ (1,0) [0|1] "" XXX
 SG_ LDW_KD_Fehler : 23|1@1+ (1,0) [0|1] "" XXX
 SG_ LDW_DLC : 24|8@1+ (0.01,-1.25) [-1.25|1.25] "" XXX
 SG_ LDW_TLC : 32|5@1+ (0.1,0) [0|3] "" XXX
 SG_ LDW_Seite_DLCTLC : 37|1@1+ (1,0) [0|1] "" XXX
 SG_ LDW_Frueh_Spaet : 38|2@1+ (1,0) [0|3] "" XXX

BO_ 428 Bremse_8: 8 XXX
 SG_ CHECKSUM : 0|8@1+ (1,0) [0|255] "" XXX
 SG_ COUNTER : 8|4@1+ (1,0) [0|15] "" XXX
 SG_ BR8_Sta_ACC_Anf : 12|1@1+ (1,0) [0|1] "" XXX
 SG_ BR8_Verz_EPB_akt : 13|1@1+ (1,0) [0|1] "" XXX
 SG_ BR8_Sta_Br_temp : 14|1@1+ (1,0) [0|1] "" XXX
 SG_ BR8_Sta_Br_Druck : 15|1@1+ (1,0) [0|1] "" XXX
 SG_ BR8_HHC_Haltebestaetigung : 16|1@1+ (1,0) [0|1] "" XXX
 SG_ BR8_HHC_Signal_QBit : 17|1@1+ (1,0) [0|1] "" XXX
 SG_ ESP_MKB_ausloesbar : 20|1@1+ (1,0) [0|1] "" XXX
 SG_ ESP_Haltebestaetigung : 21|1@1+ (1,0) [0|1] "" XXX
 SG_ ESC_Motorstartverzeogerung : 22|1@1+ (1,0) [0|1] "" XXX
 SG_ BR8_Istbeschl : 32|9@1+ (0.02,-7.22) [-7.22|2.98] "Unit_MeterPerSeconSquar" XXX
 SG_ BR8_Sta_HW_BLS : 41|1@1+ (1,0) [0|1] "" XXX
 SG_ BR8_QB_LBeschl : 42|1@1+ (1,0) [0|1] "" XXX
 SG_ BR8_ESC_Mode : 43|2@1+ (1,0) [0|3] "" XXX
 SG_ BR8_aktBrSyst : 45|1@1+ (1,0) [0|1] "" XXX
 SG_ BR8_Fa_bremst : 46|1@1+ (1,0) [0|1] "" XXX
 SG_ BR8_StaBrSyst : 47|1@1+ (1,0) [0|1] "" XXX
 SG_ BR8_Laengsbeschl : 48|10@1+ (0.03125,-16) [-15.96875|15.9375] "Unit_MeterPerSeconSquar" XXX
 SG_ BR8_Sta_ADR_BR : 58|1@1+ (1,0) [0|1] "" XXX
 SG_ BR8_Quattro : 59|1@1+ (1,0) [0|1] "" XXX
 SG_ BR8_Sta_VerzReg : 60|1@1+ (1,0) [0|1] "" XXX
 SG_ BR8_Sta_BLS : 61|1@1+ (1,0) [0|1] "" XXX
 SG_ BR8_Verz_EPB : 62|1@1+ (1,0) [0|1] "" XXX
 SG_ BR8_Check_EPB : 63|1@1+ (1,0) [0|1] "" XXX

BO_ 928 Bremse_10: 8 XXX
 SG_ B10_Checksumme : 0|8@1+ (1,0) [0|255] "" XXX
 SG_ B10_Zaehler : 8|4@1+ (1,0) [0|15] "" XXX
 SG_ B10_QB_Wegimp_VL : 12|1@1+ (1,0) [0|1] "" XXX
 SG_ B10_QB_Wegimp_VR : 13|1@1+ (1,0) [0|1] "" XXX
 SG_ B10_QB_Wegimp_HL : 14|1@1+ (1,0) [0|1] "" XXX
 SG_ B10_QB_Wegimp_HR : 15|1@1+ (1,0) [0|1] "" XXX
 SG_ B10_Wegimp_VL : 16|10@1+ (1,0) [0|1000] "" XXX
 SG_ B10_Wegimp_VR : 26|10@1+ (1,0) [0|1000] "" XXX
 SG_ B10_Wegimp_HL : 36|10@1+ (1,0) [0|1000] "" XXX
 SG_ B10_Wegimp_HR : 46|10@1+ (1,0) [0|1000] "" XXX
 SG_ B10_QB_Fahrtr_VL : 56|1@1+ (1,0) [0|1] "" XXX
 SG_ B10_QB_Fahrtr_VR : 57|1@1+ (1,0) [0|1] "" XXX
 SG_ B10_QB_Fahrtr_HL : 58|1@1+ (1,0) [0|1] "" XXX
 SG_ B10_QB_Fahrtr_HR : 59|1@1+ (1,0) [0|1] "" XXX
 SG_ B10_Fahrtr_VL : 60|1@1+ (1,0) [0|1] "" XXX
 SG_ B10_Fahrtr_VR : 61|1@1+ (1,0) [0|1] "" XXX
 SG_ B10_Fahrtr_HL : 62|1@1+ (1,0) [0|1] "" XXX
 SG_ B10_Fahrtr_HR : 63|1@1+ (1,0) [0|1] "" XXX

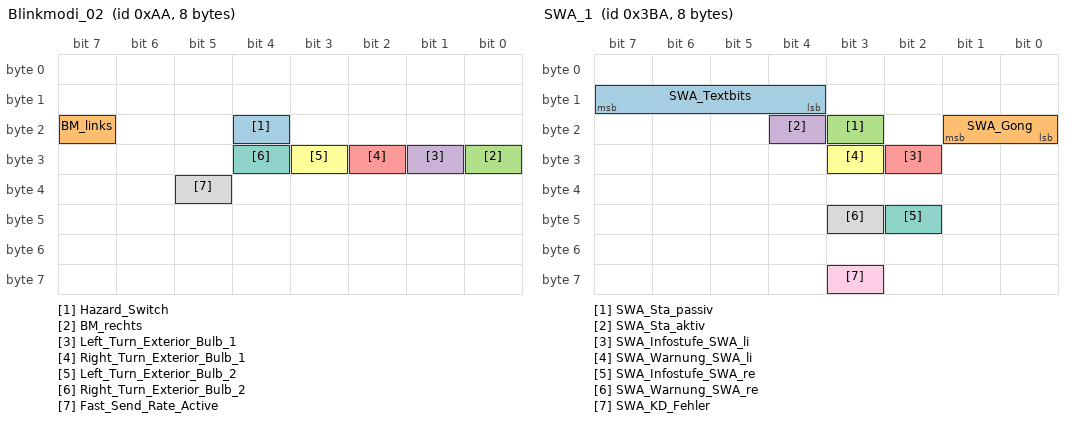
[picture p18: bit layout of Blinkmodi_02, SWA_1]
BO_ 170 Blinkmodi_02: 8 XXX
 SG_ Hazard_Switch : 20|1@1+ (1,0) [0|1] "" XXX
 SG_ BM_links : 23|1@1+ (1,0) [0|1] "" XXX
 SG_ BM_rechts : 24|1@1+ (1,0) [0|1] "" XXX
 SG_ Left_Turn_Exterior_Bulb_1 : 25|1@1+ (1,0) [0|1] "" XXX
 SG_ Right_Turn_Exterior_Bulb_1 : 26|1@1+ (1,0) [0|1] "" XXX
 SG_ Left_Turn_Exterior_Bulb_2 : 27|1@1+ (1,0) [0|1] "" XXX
 SG_ Right_Turn_Exterior_Bulb_2 : 28|1@1+ (1,0) [0|1] "" XXX
 SG_ Fast_Send_Rate_Active : 37|1@1+ (1,0) [0|1] "" XXX

BO_ 835 RDK_Status: 3 XXX
 SG_ RKS_Reifen_VL : 0|1@1+ (1,0) [0|1] "" XXX
 SG_ RKS_Reifen_VR : 1|1@1+ (1,0) [0|1] "" XXX
 SG_ RKS_Reifen_HL : 2|1@1+ (1,0) [0|1] "" XXX
 SG_ RKS_Reifen_HR : 3|1@1+ (1,0) [0|1] "" XXX
 SG_ RKS_Reifen_RR : 4|1@1+ (1,0) [0|1] "" XXX
 SG_ RKS_Warnung_2 : 5|1@1+ (1,0) [0|1] "" XXX
 SG_ RKS_Warnung_1 : 6|1@1+ (1,0) [0|1] "" XXX
 SG_ RKS_Systemfehler : 7|1@1+ (1,0) [0|1] "" XXX
 SG_ RKS_Kalibrier_abgew : 8|1@1+ (1,0) [0|1] "" XXX
 SG_ RKS_Druckdiff_Vorn : 9|1@1+ (1,0) [0|1] "" XXX
 SG_ RKS_Druckdiff_Hinten : 10|1@1+ (1,0) [0|1] "" XXX
 SG_ RKS_Befuellung_RR_low : 11|1@1+ (1,0) [0|1] "" XXX
 SG_ RKS_Funkstoerung : 12|1@1+ (1,0) [0|1] "" XXX
 SG_ RKS_System_Aus : 13|1@1+ (1,0) [0|1] "" XXX
 SG_ RKS_KD_Fehler : 15|1@1+ (1,0) [0|1] "" XXX
 SG_ RKS_Lampe : 16|1@1+ (1,0) [0|1] "" XXX
 SG_ RKS_Ton : 17|1@1+ (1,0) [0|1] "" XXX
 SG_ RKS_Gong : 18|1@1+ (1,0) [0|1] "" XXX
 SG_ RKS_RDK_Blinkbit : 19|1@1+ (1,0) [0|1] "" XXX
 SG_ RKS_Teillast : 20|1@1+ (1,0) [0|1] "" XXX

BO_ 914 Gate_Komf_2: 8 XXX
 SG_ GK2_Sta_LSM : 0|1@1+ (1,0) [0|1] "" XXX
 SG_ GK2_Sta_Lichtsensor : 1|1@1+ (1,0) [0|1] "" XXX
 SG_ GK2_Sta_Licht1 : 2|1@1+ (1,0) [0|1] "" XXX
 SG_ GK2_Sta_VSG : 3|1@1+ (1,0) [0|1] "" XXX
 SG_ GK2_Sta_Schluessel : 4|1@1+ (1,0) [0|1] "" XXX
 SG_ GK2_Sta_Profil : 5|1@1+ (1,0) [0|1] "" XXX
 SG_ GK2_Sta_Clima2 : 6|1@1+ (1,0) [0|1] "" XXX
 SG_ GK2_Sta_BSG4 : 7|1@1+ (1,0) [0|1] "" XXX
 SG_ GK2_Sta_Kessy_4 : 8|1@1+ (1,0) [0|1] "" XXX
 SG_ BS4_Gleitende_Leuchtw_Anf : 9|1@1+ (1,0) [0|1] "" XXX
 SG_ BS4_GLW_Fernlicht_Anf : 10|1@1+ (1,0) [0|1] "" XXX
 SG_ GK2_Blk_L_Kontrolle : 11|1@1+ (1,0) [0|1] "" XXX
 SG_ GK2_Blk_R_Kontrolle : 12|1@1+ (1,0) [0|1] "" XXX
 SG_ GK2_LS_KomFehler : 14|1@1+ (1,0) [0|1] "" XXX
 SG_ GK2_LS_def : 15|1@1+ (1,0) [0|1] "" XXX
 SG_ GK2_Helligkeit : 16|3@1+ (714.286,0) [0|5000.002] "Unit_Lux" XXX
 SG_ GK2_VD_zu_ver : 19|1@1+ (1,0) [0|1] "" XXX
 SG_ GK2_VD_entriegelt : 20|1@1+ (1,0) [0|1] "" XXX
 SG_ GK2_VD_offen_ver : 21|1@1+ (1,0) [0|1] "" XXX
 SG_ GK2_Verdeck_Anf : 22|1@1+ (1,0) [0|1] "" XXX
 SG_ GK2_VDKD_auf : 23|1@1+ (1,0) [0|1] "" XXX
 SG_ GK2_Schluessel : 24|4@1+ (1,0) [0|15] "" XXX
 SG_ GK2_Hardtop : 28|1@1+ (1,0) [0|1] "" XXX
 SG_ GK2_AFL_Schalter : 29|1@1+ (1,0) [0|1] "" XXX
 SG_ GK2_Nebelschluss : 30|1@1+ (1,0) [0|1] "" XXX
 SG_ GK2_EM_LIN_ungueltig : 31|1@1+ (1,0) [0|1] "" XXX
 SG_ GK2_Profil : 32|4@1+ (1,0) [0|15] "" XXX
 SG_ GK2_Kl_StSt_Info : 36|2@1+ (1,0) [0|3] "" XXX
 SG_ GK2_BSG_StSt_Info : 38|2@1+ (1,0) [0|3] "" XXX
 SG_ GK2_BEM_P_Generator : 40|8@1+ (50,0) [0|12700] "Unit_Watt" XXX
 SG_ GK2_BEM_Abschaltstufen : 48|3@1+ (1,0) [0|7] "" XXX
 SG_ GK2_BEM_DFM : 51|5@1+ (3.225,0.025) [0.025|100] "Unit_PerCent" XXX
 SG_ GK2_Kessy_StSt_Info : 56|2@1+ (1,0) [0|3] "" XXX
 SG_ GK2_BEM_StSt_Info : 58|2@1+ (1,0) [0|3] "" XXX

BO_ 954 SWA_1: 8 SWA
 SG_ SWA_Textbits : 12|4@1+ (1,0) [0|15] ""  XXX
 SG_ SWA_Gong : 16|2@1+ (1,0) [0|3] ""  XXX
 SG_ SWA_Sta_passiv : 19|1@1+ (1,0) [0|1] ""  XXX
 SG_ SWA_Sta_aktiv : 20|1@1+ (1,0) [0|1] ""  XXX
 SG_ SWA_Infostufe_SWA_li : 26|1@1+ (1,0) [0|1] ""  XXX
 SG_ SWA_Warnung_SWA_li : 27|1@1+ (1,0) [0|1] ""  XXX
 SG_ SWA_Infostufe_SWA_re : 42|1@1+ (1,0) [0|1] ""  XXX
 SG_ SWA_Warnung_SWA_re : 43|1@1+ (1,0) [0|1] ""  XXX
 SG_ SWA_KD_Fehler : 59|1@1+ (1,0) [0|1] ""  XXX

BO_ 1175 Parkhilfe_01: 8 XXX
 SG_ PH_Abschaltursache : 13|3@1+ (1,0) [0|7] "" XXX
 SG_ PH_Opt_Anzeige_V_ein : 16|1@1+ (1,0) [0|1] "" XXX
 SG_ PH_Opt_Anzeige_H_ein : 17|1@1+ (1,0) [0|1] "" XXX
 SG_ PH_Opt_Anz_V_Hindernis : 18|1@1+ (1,0) [0|1] "" XXX
 SG_ PH_Opt_Anz_H_Hindernis : 19|1@1+ (1,0) [0|1] "" XXX
 SG_ PH_Tongeber_V_aktiv : 20|1@1+ (1,0) [0|1] "" XXX
 SG_ PH_Tongeber_H_aktiv : 21|1@1+ (1,0) [0|1] "" XXX
 SG_ PH_Tongeber_mute : 22|1@1+ (1,0) [0|1] "" XXX
 SG_ PH_Anf_Audioabsenkung : 23|1@1+ (1,0) [0|1] "" XXX
 SG_ PH_Frequenz_hinten : 32|4@1+ (1,0) [0|15] "" XXX
 SG_ PH_Lautstaerke_hinten : 36|4@1+ (1,0) [0|15] "" XXX
 SG_ PH_Frequenz_vorn : 40|4@1+ (1,0) [0|15] "" XXX
 SG_ PH_Lautstaerke_vorn : 44|4@1+ (1,0) [0|15] "" XXX
 SG_ PH_Trigger_Bildaufschaltung : 48|1@1+ (1,0) [0|1] "" XXX
 SG_ PH_StartStopp_Info : 49|2@1+ (1,0) [0|3] "" XXX
 SG_ PH_Aufbauten_erk : 51|1@1+ (1,0) [0|1] "" XXX
 SG_ PH_BerErk_vorn : 52|2@1+ (1,0) [0|3] "" XXX
 SG_ PH_BerErk_hinten : 54|2@1+ (1,0) [0|3] "" XXX
 SG_ PH_defekt : 56|1@1+ (1,0) [0|1] "" XXX
 SG_ PH_gestoert : 57|1@1+ (1,0) [0|1] "" XXX
 SG_ PH_Systemzustand : 58|3@1+ (1,0) [0|7] "" XXX
 SG_ PH_Display_Kundenwunsch : 61|2@1+ (1,0) [0|3] "" XXX
 SG_ PH_KD_Fehler : 63|1@1+ (1,0) [0|1] "" XXX

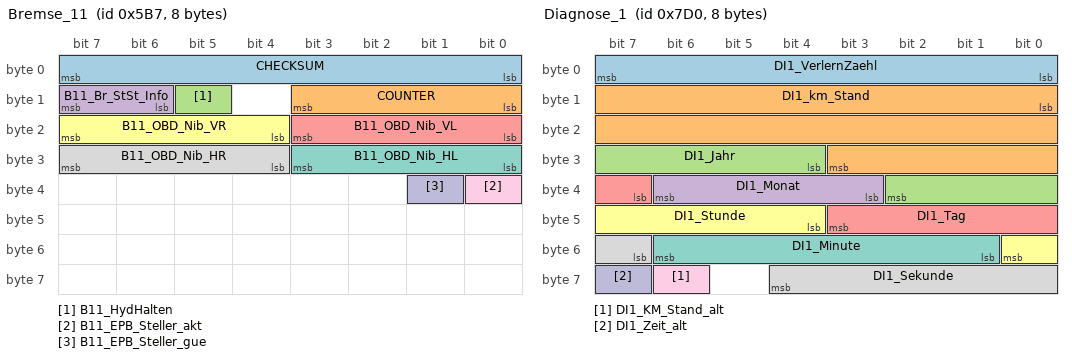
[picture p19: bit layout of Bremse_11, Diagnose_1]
BO_ 1463 Bremse_11: 8 XXX
 SG_ CHECKSUM : 0|8@1+ (1,0) [0|255] "" XXX
 SG_ COUNTER : 8|4@1+ (1,0) [0|15] "" XXX
 SG_ B11_HydHalten : 13|1@1+ (1,0) [0|1] "" XXX
 SG_ B11_Br_StSt_Info : 14|2@1+ (1,0) [0|3] "" XXX
 SG_ B11_OBD_Nib_VL : 16|4@1+ (1,0) [0|15] "" XXX
 SG_ B11_OBD_Nib_VR : 20|4@1+ (1,0) [0|15] "" XXX
 SG_ B11_OBD_Nib_HL : 24|4@1+ (1,0) [0|15] "" XXX
 SG_ B11_OBD_Nib_HR : 28|4@1+ (1,0) [0|15] "" XXX
 SG_ B11_EPB_Steller_akt : 32|1@1+ (1,0) [0|1] "" XXX
 SG_ B11_EPB_Steller_gue : 33|1@1+ (1,0) [0|1] "" XXX

BO_ 1500 Soll_Verbauliste_neu: 8 XXX
 SG_ VL1_Motor_SG : 0|1@1+ (1,0) [0|1] "" XXX
 SG_ VL1_Getr_SG : 1|1@1+ (1,0) [0|1] "" XXX
 SG_ VL1_ABS : 2|1@1+ (1,0) [0|1] "" XXX
 SG_ VL1_Kombi : 3|1@1+ (1,0) [0|1] "" XXX
 SG_ VL1_LSM : 4|1@1+ (1,0) [0|1] "" XXX
 SG_ VL1_Airbag : 5|1@1+ (1,0) [0|1] "" XXX
 SG_ VL1_Lenkhilfe : 6|1@1+ (1,0) [0|1] "" XXX
 SG_ VL1_dyn_LWR : 7|1@1+ (1,0) [0|1] "" XXX
 SG_ VL1_res_08 : 8|1@1+ (1,0) [0|1] "" XXX
 SG_ VL1_Allrad : 9|1@1+ (1,0) [0|1] "" XXX
 SG_ VL1_ADR : 10|1@1+ (1,0) [0|1] "" XXX
 SG_ VL1_ADR_getrennt : 11|1@1+ (1,0) [0|1] "" XXX
 SG_ VL1_EPB : 12|1@1+ (1,0) [0|1] "" XXX
 SG_ VL1_res_13 : 13|1@1+ (1,0) [0|1] "" XXX
 SG_ VL1_Daempfer : 14|1@1+ (1,0) [0|1] "" XXX
 SG_ VL1_Quersperre : 15|1@1+ (1,0) [0|1] "" XXX
 SG_ VL1_MotorSlave : 16|1@1+ (1,0) [0|1] "" XXX
 SG_ VL1_SWA : 17|1@1+ (1,0) [0|1] "" XXX
 SG_ VL1_HCA : 18|1@1+ (1,0) [0|1] "" XXX
 SG_ VL1_RKA_Plus : 19|1@1+ (1,0) [0|1] "" XXX
 SG_ VL1_PLA : 20|1@1+ (1,0) [0|1] "" XXX
 SG_ VL1_WFS_KBI : 21|1@1+ (1,0) [0|1] "" XXX
 SG_ VL1_Kombi_KBI : 22|1@1+ (1,0) [0|1] "" XXX
 SG_ VL1_Soll_eq_Ist : 23|1@1+ (1,0) [0|1] "" XXX
 SG_ VL1_BSG_Komf : 24|1@1+ (1,0) [0|1] "" XXX
 SG_ VL1_ZKE : 25|1@1+ (1,0) [0|1] "" XXX
 SG_ VL1_TSG_FT : 26|1@1+ (1,0) [0|1] "" XXX
 SG_ VL1_TSG_BT : 27|1@1+ (1,0) [0|1] "" XXX
 SG_ VL1_TSG_HL : 28|1@1+ (1,0) [0|1] "" XXX
 SG_ VL1_TSG_HR : 29|1@1+ (1,0) [0|1] "" XXX
 SG_ VL1_Memory : 30|1@1+ (1,0) [0|1] "" XXX
 SG_ VL1_Dachmodul_K : 31|1@1+ (1,0) [0|1] "" XXX
 SG_ VL1_Zentralelektrik_II : 32|1@1+ (1,0) [0|1] "" XXX
 SG_ VL1_RDK : 33|1@1+ (1,0) [0|1] "" XXX
 SG_ VL1_Lenksaeule : 34|1@1+ (1,0) [0|1] "" XXX
 SG_ VL1_Gateway : 35|1@1+ (1,0) [0|1] "" XXX
 SG_ VL1_Clima_Komf : 36|1@1+ (1,0) [0|1] "" XXX
 SG_ VL1_Einparkhilfe : 37|1@1+ (1,0) [0|1] "" XXX
 SG_ VL1_PTC_Heizung : 38|1@1+ (1,0) [0|1] "" XXX
 SG_ VL1_Standheiz : 39|1@1+ (1,0) [0|1] "" XXX
 SG_ VL1_Verdeck : 40|1@1+ (1,0) [0|1] "" XXX
 SG_ VL1_RSE_I : 41|1@1+ (1,0) [0|1] "" XXX
 SG_ VL1_res_42 : 42|1@1+ (1,0) [0|1] "" XXX
 SG_ VL1_MDI_I : 43|1@1+ (1,0) [0|1] "" XXX
 SG_ VL1_Anhaenger : 44|1@1+ (1,0) [0|1] ""  SWA
 SG_ VL1_Memory_BF : 45|1@1+ (1,0) [0|1] "" XXX
 SG_ VL1_Easy_Entry_VF : 46|1@1+ (1,0) [0|1] "" XXX
 SG_ VL1_Easy_Entry_VB : 47|1@1+ (1,0) [0|1] "" XXX
 SG_ VL1_Heckdeckel : 48|1@1+ (1,0) [0|1] "" XXX
 SG_ VL1_Rearview : 49|1@1+ (1,0) [0|1] "" XXX
 SG_ VL1_Sonderfzg_SG : 50|1@1+ (1,0) [0|1] "" XXX
 SG_ VL1_Tastenmodul : 51|1@1+ (1,0) [0|1] "" XXX
 SG_ VL1_Kompass : 52|1@1+ (1,0) [0|1] "" XXX
 SG_ VL1_WFS_K : 53|1@1+ (1,0) [0|1] "" XXX
 SG_ VL1_GSM_Pager : 54|1@1+ (1,0) [0|1] "" XXX
 SG_ VL1_InfoElektronik : 55|1@1+ (1,0) [0|1] "" XXX
 SG_ VL1_DSP : 56|1@1+ (1,0) [0|1] "" XXX
 SG_ VL1_DAB : 57|1@1+ (1,0) [0|1] "" XXX
 SG_ VL1_Telematik : 58|1@1+ (1,0) [0|1] "" XXX
 SG_ VL1_Navigation : 59|1@1+ (1,0) [0|1] "" XXX
 SG_ VL1_TV_Tuner : 60|1@1+ (1,0) [0|1] "" XXX
 SG_ VL1_Neigungsmodul_I : 61|1@1+ (1,0) [0|1] "" XXX
 SG_ VL1_Radio : 62|1@1+ (1,0) [0|1] "" XXX
 SG_ VL1_Telefon : 63|1@1+ (1,0) [0|1] "" XXX

BO_ 1490 Ident: 8 XXX
 SG_ IDT_Mux M : 0|2@1+ (1,0) [0|2] "" XXX
 SG_ IDT_Geheimnis_1 m0 : 8|8@1+ (1,0) [0|255] "" XXX
 SG_ IDT_VIN_4 m1 : 8|8@1+ (1,0) [0|255] "" XXX
 SG_ IDT_VIN_11 m2 : 8|8@1+ (1,0) [0|255] "" XXX
 SG_ IDT_Geheimnis_2 m0 : 16|8@1+ (1,0) [0|255] "" XXX
 SG_ IDT_VIN_5 m1 : 16|8@1+ (1,0) [0|255] "" XXX
 SG_ IDT_VIN_12 m2 : 16|8@1+ (1,0) [0|255] "" XXX
 SG_ IDT_Geheimnis_3 m0 : 24|8@1+ (1,0) [0|255] "" XXX
 SG_ IDT_VIN_6 m1 : 24|8@1+ (1,0) [0|255] "" XXX
 SG_ IDT_VIN_13 m2 : 24|8@1+ (1,0) [0|255] "" XXX
 SG_ IDT_Geheimnis_4 m0 : 32|8@1+ (1,0) [0|255] "" XXX
 SG_ IDT_VIN_7 m1 : 32|8@1+ (1,0) [0|255] "" XXX
 SG_ IDT_VIN_14 m2 : 32|8@1+ (1,0) [0|255] "" XXX
 SG_ IDT_VIN_1 m0 : 40|8@1+ (1,0) [0|255] "" XXX
 SG_ IDT_VIN_8 m1 : 40|8@1+ (1,0) [0|255] "" XXX
 SG_ IDT_VIN_15 m2 : 40|8@1+ (1,0) [0|255] "" XXX
 SG_ IDT_VIN_2 m0 : 48|8@1+ (1,0) [0|255] "" XXX
 SG_ IDT_VIN_9 m1 : 48|8@1+ (1,0) [0|255] "" XXX
 SG_ IDT_VIN_16 m2 : 48|8@1+ (1,0) [0|255] "" XXX
 SG_ IDT_VIN_3 m0 : 56|8@1+ (1,0) [0|255] "" XXX
 SG_ IDT_VIN_10 m1 : 56|8@1+ (1,0) [0|255] "" XXX
 SG_ IDT_VIN_17 m2 : 56|8@1+ (1,0) [0|255] "" XXX

BO_ 2000 Diagnose_1: 8 XXX
 SG_ DI1_VerlernZaehl : 0|8@1+ (1,0) [0|254] "" XXX
 SG_ DI1_km_Stand : 8|20@1+ (1,0) [0|1048575] "Unit_KiloMeter" XXX
 SG_ DI1_Jahr : 28|7@1+ (1,2000) [2000|2127] "Unit_Year" XXX
 SG_ DI1_Monat : 35|4@1+ (1,0) [1|12] "Unit_Month" XXX
 SG_ DI1_Tag : 39|5@1+ (1,0) [0|31] "Unit_Day" XXX
 SG_ DI1_Stunde : 44|5@1+ (1,0) [0|23] "Unit_Hours" XXX
 SG_ DI1_Minute : 49|6@1+ (1,0) [0|59] "Unit_Minut" XXX
 SG_ DI1_Sekunde : 55|6@1+ (1,0) [0|59] "Unit_Secon" XXX
 SG_ DI1_KM_Stand_alt : 62|1@1+ (1,0) [0|1] "" XXX
 SG_ DI1_Zeit_alt : 63|1@1+ (1,0) [0|1] "" XXX

CM_ SG_ 80 Checksumme_Airbag_1 "Checksum Airbag_1";
CM_ SG_ 80 Zaehler_Airbag_1 "Counter Airbag_1";

CM_ BO_ 194 "Steering wheel angle message 1 - Contains steering angle, speed, and status information";

CM_ SG_ 194 LW1_LRW "Steering wheel angle (0 = straight ahead, 7FFFh = stop)";
CM_ SG_ 194 LW1_LRW_Sign "Steering angle sign: 0=positive (left), 1=negative (right)";
CM_ SG_ 194 LW1_Lenk_Gesch "Steering wheel angular velocity (0 = no movement, 7FFFh = max speed)";
CM_ SG_ 194 LW1_Gesch_Sign "Angular velocity sign: 0=positive, 1=negative";
CM_ SG_ 194 LW1_ID "Calibration ID - 0=not calibrated, 128=calibrated (PQ35/46/VW32x/VW411)";
CM_ SG_ 194 LW1_Initquelle "Initialization source";
CM_ SG_ 194 LW1_Status "Sensor status";
CM_ SG_ 194 LW1_Sta_KL30 "Terminal 30 status (Kostal sensor)";
CM_ SG_ 194 LW1_Zaehler "Free running message counter";
CM_ SG_ 194 LW1_Kodier "Coding data (multiplex output depends on counter)";
CM_ SG_ 194 LW1_CRC "Checksum - One's complement of 8-bit sum of bytes 1,2,3,4,6";

CM_ SG_ 210 LM_Offset "centiNewton-meters for ease of calculation without FP math in Panda";
CM_ SG_ 210 Vib_Amp "Steering wheel haptic, amplitude";
CM_ SG_ 210 Vib_Freq "Steering wheel haptic, frequency";
CM_ SG_ 210 HCA_ALC_LW_KeyCipher "Private PQ ALC cipher byte. Valid on the private HCA_Status 8/3 path only.";
CM_ SG_ 416 BR1_ASR_Anf "ASR request to engine - requests in bytes 5 and 6 to be executed";
CM_ SG_ 416 BR1_MSR_Anf "MSR request - when set, byte 6 contains inverse MSR torque";
CM_ SG_ 416 BR1_ABS_Brems "ABS control active (including pressure reduction)";
CM_ SG_ 416 BR1_EDS_Ongr "Electronic differential lock intervention";
CM_ SG_ 416 BR1_ESP_Ongr "ESP driving dynamics control intervention";
CM_ SG_ 416 BR1_ASR_Ongr "ASR transmission switching influence";
CM_ SG_ 416 BR1_EBV_Ongr "Electronic brake force distribution intervention";
CM_ SG_ 416 BR1_Lampe_ABS "ABS safety warning lamp";
CM_ SG_ 416 BR1_Lampe_ASR "ASR/ESP lamp (including flashing info)";
CM_ SG_ 416 BR1_Lampe_BK "Brake control lamp (red)";
CM_ SG_ 416 BR1_Lichtschalt "Brake light switch / brake pressure threshold exceeded";
CM_ SG_ 416 BR1_StaDruckschw "Brake test switch / pressure threshold status";
CM_ SG_ 416 BR1_MAD "OBD rough road suppression";
CM_ SG_ 416 BR1_Sta_MAD "Rough road suppression status";
CM_ SG_ 416 BR1_Diagnose "ABS diagnosis mode active";
CM_ SG_ 416 BR1_BKV_active "Active brake booster installed and not faulty";
CM_ SG_ 416 BR1_Rad_kmh "Vehicle speed (mean of driven wheels or ABS reference)";
CM_ SG_ 416 BR1_ASRMo_sl "ASR engagement torque slow (0-99.06%)";
CM_ SG_ 416 BR1_ASRMo_fa "ASR engagement torque fast when MSR_Anf=0 (0-99.06%)";
CM_ SG_ 416 BR1_MSR_Mo_inv "Inverse MSR torque when MSR_Anf=1 (99.06-0%)";
CM_ SG_ 416 BR1_MSR_Mo "MSR engagement torque (0-99.06%)";
CM_ SG_ 416 BR1_Zaehler "Message counter to mark intervention moment";
CM_ SG_ 416 BR1_ASR_ESP "Control unit type: 0=ABS/EDS, 1=ASR/ESP/MABS";
CM_ SG_ 416 BR1_ESPASR_passive "ESP/ASR passive or deactivated by driver";
CM_ SG_ 416 BR1_Sta_ESP "ESP error status (fault memory entry)";
CM_ SG_ 416 BR1_Ersatz_Kmh "Speed is substitute value (sensor defect)";

CM_ SG_ 640 inneres_Motor_Moment "Engine Indicated Torque";
CM_ SG_ 640 Fahrerwunschmoment "Driver Requested Torque";
CM_ SG_ 640 mechanisches_Motor_Verlustmomen "Mechanical Torque Loss";
CM_ SG_ 640 Fahrpedalwert_oder_Drosselklapp "Accelerator Pedal or Throttle Position";
CM_ SG_ 640 Motordrehzahl "Engine Speed";
CM_ SG_ 640 Momentenangaben_ungenau "Approximate Torque Values";
CM_ SG_ 640 inneres_Motor_Moment_ohne_exter "Inner torque without external";

CM_ SG_ 644 MOB_CHECKSUM "Checksum MOB";
CM_ SG_ 644 MOB_COUNTER "Counter MOB";

CM_ BO_ 648 "Motor message 2 - Contains engine status, temperatures, and torque information";
CM_ SG_ 648 MO2_Mp_Code "Multiplex code - switches after 4 transmissions";
CM_ SG_ 648 MO2_Getr_Code "Transmission code (multiplex value when Mp_Code=2)";
CM_ SG_ 648 MO2_max_Mo "Maximum torque MDI (multiplex value when Mp_Code=3)";
CM_ SG_ 648 MO2_CAN_Vers "CAN version (multiplex value when Mp_Code=0)";
CM_ SG_ 648 MO2_Motor_Code "Motor code (multiplex value when Mp_Code=1)";
CM_ SG_ 648 MO2_Kuehlm_T "Engine coolant temperature or substitute value";
CM_ SG_ 648 MO2_BLS "Brake light switch - unfiltered raw signal";
CM_ SG_ 648 MO2_BTS "Brake test switch";
CM_ SG_ 648 MO2_Sta_Kuehlm "Coolant temperature status - 0=OK, 1=Not OK";
CM_ SG_ 648 MO2_Sta_Klima "Air conditioning compressor status";
CM_ SG_ 648 MO2_Sta_No_Bet "Normal operation status (Terminal 15 on, init complete)";
CM_ SG_ 648 MO2_Status_TSK "Drive train coordinator status";
CM_ SG_ 648 MO2_Sta_GRA "GRA/ACC status";
CM_ SG_ 648 TSK_Limiter_ausgewaehlt "Speed limiter selected";
CM_ SG_ 648 MO2_GRAregelt "GRA regulating to displayed speed";
CM_ SG_ 648 MO2_Sport_Error "Sport mode error (Porsche Cayenne)";
CM_ SG_ 648 MO2_OffRoad "OffRoad mode active";
CM_ SG_ 648 MO2_RME_Gehalt "Rapeseed oil methyl ester content (diesel)";
CM_ SG_ 648 MO2_GRA_Soll "GRA target speed setpoint";
CM_ SG_ 648 MO2_LL_Solldz "Idle target speed";
CM_ SG_ 648 MO2_Begr_Mo "Limiting torque - max possible at speed";
CM_ SG_ 648 MO2_Mo_ZWR "Minimum engine torque with ignition angle retardation";

CM_ SG_ 896 MO3_Vorgluehen "Pre-glow active (diesel engines)";
CM_ SG_ 896 MO3_Prio_Dz "Engine speed priority: 0=request, 1=mandatory";
CM_ SG_ 896 MO_Schalter_StartStopp "Start/stop deactivated by driver (LED on when 0)";
CM_ SG_ 896 MO3_Winterprg "Winter driving program active";
CM_ SG_ 896 MO3_Sta_Pedal "Accelerator pedal status: 0=OK, 1=substitute value";
CM_ SG_ 896 MO3_Sta_FPG "Accelerator pedal gradient control bit (multiplexer for byte 8)";
CM_ SG_ 896 MO3_Sign_FPG "Accelerator pedal gradient sign (only when MO3_Sta_FPG=1)";
CM_ SG_ 896 MO3_Sta_Temp "Intake air temperature status: 0=OK, 1=substitute value";
CM_ SG_ 896 MO3_Offsentemp "Intake air temperature";
CM_ SG_ 896 MO3_Pedalwert "Accelerator pedal raw signal (0-101.6%)";
CM_ SG_ 896 MO3_Rad_Wu_Mo "Wheel torque request (12-bit value, 0-1596.66% MDI)";
CM_ SG_ 896 MO3_Vorz_RadWu "Wheel torque sign: 0=positive, 1=negative";
CM_ SG_ 896 MO3_Freigabe_Segeln "Sailing operation enable for transmission";
CM_ SG_ 896 MO_StartStopp_StoppVorbereitung "Engine stop in preparation";
CM_ SG_ 896 MO3_Dz_Beeinfl "Engine speed influence factor (0-100% interpolation)";
CM_ SG_ 896 MO3_WunschDz "Desired engine speed (when MO3_Prio_Dz=1)";
CM_ SG_ 896 MO3_DKW "Throttle valve position when MO3_Sta_FPG=0 (0-101.6%)";
CM_ SG_ 896 MO3_FPGradient "Accelerator pedal gradient when MO3_Sta_FPG=1 (0-6350%/s)";

CM_ SG_ 912 GK1_Fa_Tuerkont "Status of the driver's door rotary latch";
CM_ SG_ 912 BSK_HL_geoeffnet "Status of the rear left door rotary latch";
CM_ SG_ 912 BSK_HR_geoeffnet "Status of the rear right door rotary latch";
CM_ SG_ 912 BSK_BT_geoeffnet "Status of the passenger door rotary latch";
CM_ SG_ 912 BSK_HD_Hauptraste "Status of trunk lid main detent";

CM_ BO_ 1088 "Getriebe 1 - Contains gear status, torque requests, and control signals";

CM_ SG_ 1088 GE1_Schaltung "Gear shift active: 0=no shift, 1=shift in progress";
CM_ SG_ 1088 GE1_Sta_Schutz "Transmission/converter protection request (power reduction or ignition angle)";
CM_ SG_ 1088 GE1_Klimakompr "AC compressor off request";
CM_ SG_ 1088 GE1_WK "Torque converter clutch status";
CM_ SG_ 1088 GE1_StSt_Info "Start/stop coordinator info";
CM_ SG_ 1088 GE1_EGS_Anf "EGS request - byte 4 becomes valid when set";
CM_ SG_ 1088 GE1_Zielgang "Target gear when shifting or current gear";
CM_ SG_ 1088 GE1_Wahl_Pos "Selector lever position / driving program";
CM_ SG_ 1088 GE1_Mrad_Mkurb "Wheel torque to crankshaft torque ratio (Mrad/Mcrank)";
CM_ SG_ 1088 GE1_Soll_Mo "Internal target engine torque request (0-99.06%)";
CM_ SG_ 1088 GE1_Fahrwistd "Driving resistance index (normalized % slope)";
CM_ SG_ 1088 GE1_Notlauf "Emergency mode status";
CM_ SG_ 1088 GE1_Kuehlung "Cooling request level";
CM_ SG_ 1088 GE1_Sta_OBD "OBD status - MIL lamp control";
CM_ SG_ 1088 GE1_LaunchControl "Launch control active";
CM_ SG_ 1088 GE1_Infobit "Transmission type: 0=stepped automatic, 1=CVT";
CM_ SG_ 1088 GE1_SleepInd "Sleep readiness after terminal 15 off";
CM_ SG_ 1088 GE1_Zaehler "Message counter (synchronized with Getriebe_2)";
CM_ SG_ 1088 GE1_Fehlereintr "Fault memory entry present";
CM_ SG_ 1088 GE1_WaVerl_Mo "Transmission torque loss / clutch torque (0-99.06%)";

CM_ SG_ 1056 Fehlerstatus_Aussentemp__4_1 "ambient temp error";
CM_ SG_ 1056 Fehlerstatus_Oeltemperatur_4_1 "oil temp error";
CM_ SG_ 1056 Fehlerst__Kuehlmitteltemp__4_1 "water temp error";
CM_ SG_ 1056 Aussentemperatur_gefiltert "outside temp, filtered";
CM_ SG_ 1056 Oeltemperatur_4_1 "kombi oil temperature";
CM_ SG_ 1056 Kuehlmitteltemp__4_1__Kombi_2_ "kombi coolant temperature";

CM_ SG_ 1096 Zaehler_Waehlhebel_1 "Counter Waehlhebel_1";

CM_ BO_ 1152 "Motor message 5 - Contains engine type, consumption, lamps, and diagnostic info";

CM_ SG_ 1152 MO5_Mp_Code "Multiplex selector - switches every 4 transmissions";
CM_ SG_ 1152 MO5_max_Moment "Maximum torque when Mp_Code=0 (0-630 Nm)";
CM_ SG_ 1152 MO5_Drehzahl "Engine speed at max torque when Mp_Code=1 (0-6300 RPM)";
CM_ SG_ 1152 MO5_Motortyp "Engine type info when Mp_Code=2 (cylinder count, turbo, fuel type)";
CM_ SG_ 1152 MO5_Abgastyp "Exhaust type EOBD when Mp_Code=3";
CM_ SG_ 1152 MO5_Abgastyp2 "Exhaust type OBD when Mp_Code=3";
CM_ SG_ 1152 MO5_Abgastyp3 "DPF installed when Mp_Code=3";
CM_ SG_ 1152 OBD_Kaltstart_Denominator "Cold start denominator increment when Mp_Code=3";
CM_ SG_ 1152 OBD_Minimum_Trip "Minimum normalized trip when Mp_Code=3";
CM_ SG_ 1152 MO5_DPF_reg "DPF regenerating when Mp_Code=3";
CM_ SG_ 1152 MO5_Vorgluehen "Diesel pre-glow lamp";
CM_ SG_ 1152 MO5_E_Gas "E-Gas system lamp (petrol only)";
CM_ SG_ 1152 MO5_OBD_2 "OBD/MIL lamp control";
CM_ SG_ 1152 MO5_Heissl "Coolant overheat warning lamp";
CM_ SG_ 1152 MO5_KlimaKompr "AC compressor off request";
CM_ SG_ 1152 MO5_Feld_kuehl "Map cooling installed and OK";
CM_ SG_ 1152 MO5_KliKo_Red "AC compressor power reduction";
CM_ SG_ 1152 MO5_Verbrauch "Fuel consumption counter (15-bit, µl)";
CM_ SG_ 1152 MO5_UeberlVerb "Consumption counter overflow";
CM_ SG_ 1152 MO5_Luefter "Cooling fan PWM control (0-101.6%)";
CM_ SG_ 1152 MO5_HLeuchte "Overheat pre-warning";
CM_ SG_ 1152 MO5_PartikelLamp "Particle filter lamp";
CM_ SG_ 1152 MO5_Sta_BKU "Brake vacuum pump status (Porsche only)";
CM_ SG_ 1152 MO5_TypStartSteu "Starter control type: 0=BSG/BCM, 1=MSG";
CM_ SG_ 1152 MO5_TDE_Lampe "Fuel cap warning lamp (petrol only)";
CM_ SG_ 1152 MO5_TDE_Text "Fuel cap text display (petrol only)";
CM_ SG_ 1152 MO5_DZM_Daempf "RPM gauge damping control";
CM_ SG_ 1152 MO5_Interlock "Interlock switch for manual transmission start";
CM_ SG_ 1152 MO5_Start "Automatic start permission";
CM_ SG_ 1152 MO5_Anlasser "Starter control permission";
CM_ SG_ 1152 MO5_GRA_Hauptsch "GRA main switch / readiness";
CM_ SG_ 1152 MO5_Momente "MDI torque values doubled";
CM_ SG_ 1152 MO5_Motortext1 "Text: Engine workshop";
CM_ SG_ 1152 MO5_Motortext2 "Text: Exhaust workshop (deprecated)";
CM_ SG_ 1152 MO5_Motortext3 "Text: Fuel system fault";
CM_ SG_ 1152 MO5_Motortext4 "Text: Particle filter needs regeneration";
CM_ SG_ 1152 CHECKSUM "Checksum with final value 0x0";

CM_ SG_ 1160 Zaehler_Motor_6 "Counter Motor_6";
CM_ SG_ 1160 Hoeheninfo__Motor_6_ "Altitude Correction";
CM_ SG_ 1160 Istmoment_f_r_Getriebe "Actual torque for gear";
CM_ SG_ 1160 Sollmoment_f_r_Getriebe "Target torque for gearbox";
CM_ SG_ 1160 Checksumme_Motor_6 "Checksum Motor_6";
CM_ SG_ 1160 GRA_Sollbeschleunigung "GRA target acceleration";
CM_ SG_ 1160 Ruckmeldung_Momenten "Feedback torque-integral gear intervention";

CM_ SG_ 1344 Zahler_Getriebe_2 "Counter Getriebe_2";
CM_ SG_ 1344 Hochschaltlampe "Upshift Flag";

CM_ SG_ 1386 ACA_V_Wunsch "255=unset";

CM_ SG_ 1408 Zaehler_Motor_Flexia "Counter Motor_Flexia";
CM_ SG_ 1408 Verbrennungsart "Type of combustion";
CM_ SG_ 1408 Max_Drehmoment "Maximum torque";
CM_ SG_ 1408 Drehzahl_MaxNorm "RPM of maximum torque";
CM_ SG_ 1408 Hubraum "Displacement";
CM_ SG_ 1408 Anzahl_Zylinder "Number of cylinders";
CM_ SG_ 1408 Anzahl_Ventile "Number of valves";
CM_ SG_ 1408 Ansaugsystem "Induction System";
CM_ SG_ 1408 Motorleistung "Maximum engine power";

CM_ SG_ 1416 Ladedruck "Boost Pressure";
CM_ SG_ 1416 Motordrehzahlgradient "Engine speed gradient";
CM_ SG_ 1416 Hoeheninfo__Motor_7_ "Altitude correction factor";
CM_ SG_ 1416 Oltemperatur "Oil temperature";

CM_ SG_ 1470 LDW_Direction "0=right,1=left";
CM_ SG_ 1470 XX_DLCORTLC1 "Might be DLC or TLC";
CM_ SG_ 1470 XX_DLCORTLC2 "Might be DLC or TLC, might have wrong size";

CM_ SG_ 1550 MFA_v_Signal_02 "0=km/h, 1=mph";

SG_MUL_VAL_ 416 BR1_ASRMo_fa BR1_MSR_Anf 0-0;
SG_MUL_VAL_ 416 BR1_MSR_Mo_inv BR1_MSR_Anf 1-1;

SG_MUL_VAL_ 896 MO3_DKW MO3_Sta_FPG 0-0;
SG_MUL_VAL_ 896 MO3_FPGradient MO3_Sta_FPG 1-1;
SG_MUL_VAL_ 896 MO3_Sign_FPG MO3_Sta_FPG 1-1;

VAL_ 194 LW1_LRW_Sign 0 "positives_Vorzeichen" 1 "negatives_Vorzeichen";
VAL_ 194 LW1_Gesch_Sign 0 "positives_Vorzeichen" 1 "negatives_Vorzeichen";
VAL_ 194 LW1_ID 0 "noch_not_kalibriert" 128 "kalibriert_nur_bei_PQ35_46_VW32x_VW411";
VAL_ 194 LW1_Initquelle 0 "Bremse_3" 1 "EPS_Bit";
VAL_ 194 LW1_Status 0 "OK" 1 "no_initial" 2 "sporadic_failure" 3 "permanent_failure";
VAL_ 194 LW1_Sta_KL30 0 "ok" 1 "no_init_s";

VAL_ 416 BR1_ASR_Anf 0 "no_requirement" 1 "ASR_requirement";
VAL_ 416 BR1_MSR_Anf 0 "no_requirement" 1 "MSR_requirement";
VAL_ 416 BR1_ABS_Brems 0 "no_ABS_control" 1 "ABS_control";
VAL_ 416 BR1_EDS_Ongr 0 "no_EDS_intervention" 1 "EDS_intervention";
VAL_ 416 BR1_ESP_Ongr 0 "no_ESP_intervention" 1 "ESP_intervention";
VAL_ 416 BR1_ASR_Ongr 0 "no_requirement" 1 "ASR_shift_map" 2 "Downshift" 3 "Switching_ban";
VAL_ 416 BR1_EBV_Ongr 0 "no_EBV_intervention" 1 "EBV_intervention";
VAL_ 416 BR1_Lampe_ABS 0 "Lamp_off" 1 "Lamp_on";
VAL_ 416 BR1_Lampe_ASR 0 "Lamp_off" 1 "Lamp_on";
VAL_ 416 BR1_Lampe_BK 0 "Lamp_off" 1 "Lamp_on";
VAL_ 416 BR1_Lichtschalt 0 "no_Bremsen_Schw_unterschr" 1 "Bremse_betaetigt_Schw_ueberschr";
VAL_ 416 BR1_StaDruckschw 0 "Sta_guel_BKV_n_angest_k_Br" 1 "Sta_n_verf_BKV_angest_Br";
VAL_ 416 BR1_MAD 0 "no_Offblendung" 1 "Offblendung";
VAL_ 416 BR1_Sta_MAD 0 "valid" 1 "invalid";
VAL_ 416 BR1_Diagnose 0 "no" 1 "in_Diagnose";
VAL_ 416 BR1_BKV_active 0 "BKV_not_installed_or_fault" 1 "BKV_installed_and_not_fault";
VAL_ 416 BR1_ASR_ESP 0 "ABS_ABS_EDS" 1 "ASR_ESP_MABS";
VAL_ 416 BR1_ESPASR_passive 0 "ESP_ASR_activated" 1 "ESP_oder_ASR_passive_get_oder_Fktumsch_oder_Rollenmodus";
VAL_ 416 BR1_Sta_ESP 0 "ok" 1 "Failure";
VAL_ 416 BR1_Ersatz_Kmh 0 "OK" 1 "Substitute_value";

SG_MUL_VAL_ 648 MO2_Getr_Code MO2_Mp_Code 2-2;
SG_MUL_VAL_ 648 MO2_max_Mo MO2_Mp_Code 3-3;
SG_MUL_VAL_ 648 MO2_CAN_Vers MO2_Mp_Code 0-0;
SG_MUL_VAL_ 648 MO2_Motor_Code MO2_Mp_Code 1-1;

SG_MUL_VAL_ 1152 MO5_max_Moment MO5_Mp_Code 0-0;
SG_MUL_VAL_ 1152 MO5_Drehzahl MO5_Mp_Code 1-1;
SG_MUL_VAL_ 1152 MO5_Motortyp MO5_Mp_Code 2-2;
SG_MUL_VAL_ 1152 MO5_Abgastyp MO5_Mp_Code 3-3;
SG_MUL_VAL_ 1152 MO5_Abgastyp2 MO5_Mp_Code 3-3;
SG_MUL_VAL_ 1152 MO5_Abgastyp3 MO5_Mp_Code 3-3;
SG_MUL_VAL_ 1152 OBD_Kaltstart_Denominator MO5_Mp_Code 3-3;
SG_MUL_VAL_ 1152 OBD_Minimum_Trip MO5_Mp_Code 3-3;
SG_MUL_VAL_ 1152 MO5_DPF_reg MO5_Mp_Code 3-3;

VAL_ 648 MO2_Mp_Code 0 "CAN_Stand" 1 "Motor_Kod" 2 "Getriebe_Kod" 3 "MDI_Max";

VAL_ 648 MO2_Getr_Code 0 "_5HP19" 1 "_5HP24" 2 "AG4" 3 "VL300" 4 "VQ250" 5 "VQ35" 6 "AG4_yestco" 7 "AG5_yestco" 8 "autom_Kupplung" 9 "autom_Kupplung_mit_ASG" 10 "AG6_yestco_ZF_6HP_AISIN" 11 "DQ500_DQ250_DQ200" 12 "SQ100_SQ200" 14 "AL1000_AL551_AL951_ZF8HPx" 15 "Handschalter_konv" 16 "DL800" 17 "E_Fahrzeug__Single_Gear";

VAL_ 648 MO2_BLS 0 "no_Bremsen" 1 "Bremse_betaetigt";
VAL_ 648 MO2_BTS 0 "no_braking" 1 "Brake_activated";
VAL_ 648 MO2_Sta_Kuehlm 0 "Temperature_ok" 1 "Temperature_not_ok";
VAL_ 648 MO2_Sta_Klima 0 "Climate_off" 1 "Climate_on";
VAL_ 648 MO2_Sta_No_Bet 0 "no_Normalbetrieb" 1 "Normalbetrieb";
VAL_ 648 MO2_Status_TSK 0 "TSK_not_available" 1 "TSK_available";
VAL_ 648 MO2_Sta_GRA 0 "ADR_GRA_off" 1 "gra_activated_lamp_on" 2 "gra_overdriven_lamp_on" 3 "ADR_gra_faulted";
VAL_ 648 TSK_Limiter_ausgewaehlt 0 "no_limiter_selected" 1 "Limiter_Selected";
VAL_ 648 MO2_GRAregelt 0 "no" 1 "yes";
VAL_ 648 MO2_Sport_Error 0 "no_Failure" 1 "Failure";
VAL_ 648 MO2_OffRoad 0 "not_active" 1 "active";

VAL_ 870 AWV_Text 0 "kein_Text" 1 "FrontAssist_aus" 2 "FrontAssist_startet" 3 "FrontAssist_Warnung" 4 "FrontAssist_Sens_reinig" 5 "FrontAssist_Failure" 6 "FrontAssist_Demo" 7 "Vorhalt" 8 "Bremsung_wird_gerade_durchgefuehrt" 9 "Sensor_not_verfuegbar" 10 "Sensor_reinigen" 11 "Service_notwendig_Failure" 12 "Funktion_vom_Fahrer_deactivated" 13 "Funktion_vom_Fahrer_activated" 14 "FrontAssist_zur_Zeit_not_verfuegbar__rev_Failure";
VAL_ 870 AWV_1_Freigabe 0 "nicht_freigegeben" 1 "freigegeben";
VAL_ 870 AWV_1_Prefill 0 "keine_Prefill_Anf" 1 "Prefill_Anf";
VAL_ 870 AWV_1_Parameter 0 "Defaultparametersatz" 1 "Par_leicht_erh_Empf" 2 "Par_erh_Empf" 3 "Par_hoechster_Empf";
VAL_ 870 AWV_only 0 "ACC_und_AWV_verbaut" 1 "AWV_ohne_ACC_verbaut";
VAL_ 870 AWV_CityANB_Auspraegung 0 "autom_Bremsung_im_ges_vBereich" 1 "autom_Bremsung_im_def_vBereich";
VAL_ 870 AWV_Halten 0 "keine_Anforderung" 1 "Anforderung_das_Fzg_im_Stillstand_zu_halten";
VAL_ 870 ANB_Teilbremsung_Freigabe 0 "Teilbremsung_nicht_freigegeben" 1 "Teilbremsung_freigegeben";
VAL_ 870 AWV_2_Status 0 "Lampe_aus" 1 "Lampe_ein";
VAL_ 870 AWV_2_Fehler 0 "Lampe_aus" 1 "Lampe_ein";
VAL_ 870 AWV_2_SU_Warnzeit 0 "frueh" 1 "normal" 2 "spaet" 3 "adaptiv";
VAL_ 870 AWV_2_SU_Bremsruck 0 "Bremsruck_deaktiviert" 1 "Bremsruck_aktiviert";
VAL_ 870 AWV_2_SU_Gong 0 "Gong_deaktiviert" 1 "Gong_aktiviert";
VAL_ 870 AWV_2_SU_Lampe 0 "Lampe_deaktiviert" 1 "Lampe_aktiviert";
VAL_ 870 AWV_2_Umfeldwarn 0 "keine_Warnung" 1 "Warnung";
VAL_ 870 AWV_2_Freigabe 0 "keine_Ruckfreigabe" 1 "Ruckfreigabe";
VAL_ 870 AWV_2_Ruckprofil 0 "kein_Ruck" 1 "Ruckprofil_1" 2 "Ruckprofil_2" 3 "Ruckprofil_3" 4 "Ruckprofil_4" 5 "Ruckprofil_5" 6 "not_erlaubt" 7 "not_erlaubt";
VAL_ 870 AWV_2_Warnton 0 "Aus" 1 "Ein";
VAL_ 870 AWV_2_Warnsymbol 0 "Aus" 1 "Ein";
VAL_ 870 AWV_Infoton 0 "Aus" 1 "Ein";
VAL_ 870 AWV_2_Gurtstraffer 0 "Gurt_not_straffen" 1 "Gurt_straffen";
VAL_ 870 AWV_Konfiguration_Menueanf 0 "Menue_deaktivieren" 1 "Menue_aktivieren";
VAL_ 870 AWV_Konfiguration_Vorw_Menueanf 0 "Menue_deaktivieren" 1 "Menue_aktivieren";
VAL_ 870 AWV_Konfiguration_Status 0 "AWV_inaktiv" 1 "AWV_aktiv";
VAL_ 870 AWV_Konfiguration_Vorw_Status 0 "AWV_Vorwarnung_inaktiv" 1 "AWV_Vorwarnung_aktiv";
VAL_ 870 AWV_2_Abstandswarnung 0 "kein_Warnhinweis" 1 "Warnhinweis";
VAL_ 870 ANB_Zielbremsung_Freigabe 0 "Zielbremsung_nicht_freigegeben" 1 "Zielbremsung_freigegeben";
VAL_ 870 ANB_CM_Anforderung 0 "keine_Anforderung" 1 "Anforderung_aktiv";

VAL_ 872 ACS_Sta_ADR 2 "ADR_passiv" 0 "ADR_nicht_aktiv" 1 "ADR_aktiv" 3 "irrev_Fehler" ;
VAL_ 872 ACS_ADR_Schub 1 "Verz_begr_auf_Schub" 0 "Verz_nicht_begr_auf_Schub" ;
VAL_ 872 ACS_Schubabsch 1 "SA_nicht_zulaessig" 0 "SA_zulaessig" ;
VAL_ 872 ACS_StSt_Info 3 "Systemfehler" 0 "Motorlauf_nn" 1 "Stoppverbot_Motoranlauf_nn" 2 "Motoranlauf_notwendig" ;
VAL_ 872 ACS_MomEingriff 1 "MomEingr_verhindern" 0 "keine_Beeinfl_MomEingr_Mot" ;
VAL_ 872 ACS_Typ_ACC 0 "Basis_ACC" 1 "ACC_mit_FollowToStop" 3 "frei" 2 "frei" ;
VAL_ 872 ACS_FreigSollB 0 "Sollbeschl_nicht_freigeg" 1 "Sollbeschl_freigeg" ;
VAL_ 872 ACS_Sollbeschl 2046 "ADR_nicht_aktiv" 2047 "Fehler" ;
VAL_ 872 ACS_Anhaltewunsch 0 "kein_Haltewunsch" 1 "Fzg_haelt_an" ;
VAL_ 872 ACS_Fehler 1 "Fehlerspeichereintrag" 0 "kein_Fehlerspeichereintrag" ;
VAL_ 872 ACS_zul_Regelabw 254 "ADR_nicht_aktiv" 255 "Fehler" ;
VAL_ 872 ACS_max_AendGrad 254 "Neutralwert" 0 "Neutralwert" 255 "Fehler" ;

VAL_ 896 MO3_Vorgluehen 0 "no_Vorgluehen" 1 "Vorgluehen_active";
VAL_ 896 MO3_Prio_Dz 0 "Wunsch" 1 "Zwang";
VAL_ 896 MO_Schalter_StartStopp 0 "StartStopp_ueber_Hauptschalter_deactivated_LED_an" 1 "StartStopp_ueber_Hauptschalter_activated_LED_aus";
VAL_ 896 MO3_Winterprg 0 "not_active" 1 "active";
VAL_ 896 MO3_Sta_Pedal 0 "Fahrpedal_iO" 1 "Ersatzwert";
VAL_ 896 MO3_Sta_FPG 0 "Gradient_not_bed" 1 "Gradient_bed";
VAL_ 896 MO3_Sign_FPG 0 "positives_Vorzeichen" 1 "negatives_Vorzeichen";
VAL_ 896 MO3_Sta_Temp 0 "Geber_iO" 1 "Ersatzwert";
VAL_ 896 MO3_Vorz_RadWu 0 "positives_Vorzeichen" 1 "negatives_Vorzeichen";
VAL_ 896 MO3_Freigabe_Segeln 0 "Segelbetrieb_not_freigegeben" 1 "Segelbetrieb_freigegeben";
VAL_ 896 MO_StartStopp_StoppVorbereitung 0 "Motorstopp_not_in_Vorbereitung" 1 "Motorstopp_in_Vorbereitung";
CM_ BO_ 896 "Motor message 3 - Contains accelerator pedal, temperatures, and control signals";

VAL_ 978 LH2_Sta_HCA 0 "disabled" 1 "initializing" 2 "fault" 3 "ready" 4 "rejected" 5 "active" 7 "active";
VAL_ 210 HCA_Status 3 "ready" 5 "torque" 7 "torque_active" 8 "alc_angle_private" 10 "override_reset" 11 "pla_entry" 15 "standby";
VAL_ 1088 GE1_Schaltung 0 "no_circuit" 1 "circuit_is_running";
VAL_ 1088 GE1_Sta_Schutz 0 "no_protection" 1 "protection_requested";
VAL_ 1088 GE1_Klimakompr 0 "no_Anforderung" 1 "Kompressor_aus";
VAL_ 1088 GE1_WK 0 "WK_open" 1 "WK_regulated" 2 "WK_closed" 3 "Failure";
VAL_ 1088 GE1_StSt_Info 0 "Engine_running_not_necessary_stop_release" 1 "Motor_start_not_mandatory_necessary_stop_prohibition" 2 "Motor_start_absolute_necessary_start_request" 3 "System_error";
VAL_ 1088 GE1_EGS_Anf 0 "no_requirement" 1 "EGS_requirement";
VAL_ 1088 GE1_Zielgang 0 "P (Park) | Disengaged" 1 "Gear 1 | Engaged" 2 "Gear 2 | Engaged" 3 "Gear 3 | Engaged" 4 "Gear 4 | Engaged" 5 "Gear 5 | Engaged" 6 "1m Gear" 7 "Gang_R" 8 "Gear 6 | Engaged" 9 "Gear 7 | Engaged" 10 "Gear 8 | Engaged" 14 "Speed Not Defined" 15 "Failure";
VAL_ 1088 GE1_Wahl_Pos 8 "P" 7 "R" 6 "N" 5 "D" 9 "U" 12 "S" 14 "T" 10 "T" 11 "T";
VAL_ 1088 GE1_Notlauf 0 "No Emergency" 1 "No Switching" 2 "Switch to Neutral" 3 "50% Shifting Capacity" 4 "Driving Without UK" 5 "No Emeregency" 6 "No Emergency" 7 "No Emergency, Target Shifting Reached" 15 "Failure";
VAL_ 1088 GE1_Kuehlung 0 "No Additional Cooling Requested" 1 "20% Additional Fan Cooling Requested" 2 "40% Additional Fan Cooling Requested" 3 "Maximum Additional Fan Cooling Requested";
VAL_ 1088 GE1_Sta_OBD 0 "MIL Off" 1 "MIL On";
VAL_ 1088 GE1_LaunchControl 0 "Launch Control Not Active" 1 "Launch Control Program Active";
VAL_ 1088 GE1_Infobit 0 "Standard Automatic" 1 "CVT";
VAL_ 1088 GE1_SleepInd 0 "CAN is Required" 1 "Sleep Ready";
VAL_ 1088 GE1_Fehlereintr 0 "No Failure Memory Entry" 1 "Failure Memory Entry";

VAL_ 1152 MO5_Mp_Code 0 "Max_Moment" 1 "Drehzahl" 2 "Motor_Typ" 3 "Abgastyp_od_norm_Verbrauch";
VAL_ 1152 MO5_Abgastyp 0 "no_EOBD" 1 "EOBD";
VAL_ 1152 MO5_Abgastyp2 0 "no_OBD" 1 "OBD";
VAL_ 1152 MO5_Abgastyp3 0 "no_DPF_verbaut" 1 "DPF_verbaut";
VAL_ 1152 OBD_Kaltstart_Denominator 0 "Denominator_not_hochzaehlen" 1 "Bedingungen_zum_Inkr_des_Kaltstart_Denom_erf";
VAL_ 1152 OBD_Minimum_Trip 0 "no_Min_Normed_Trip" 1 "Min_Normed_Trip";
VAL_ 1152 MO5_DPF_reg 0 "DPF_regeneriert_nicht" 1 "DPF_regeneriert";
VAL_ 1152 MO5_Vorgluehen 0 "Lamp_off" 1 "Lamp_on";
VAL_ 1152 MO5_E_Gas 0 "Lamp_off" 1 "Lamp_on";
VAL_ 1152 MO5_OBD_2 0 "Lamp_off" 1 "Lamp_on";
VAL_ 1152 MO5_Heissl 0 "Lamp_off" 1 "Lamp_on";
VAL_ 1152 MO5_KlimaKompr 0 "no_Anforderung" 1 "Klimakompr_aus";
VAL_ 1152 MO5_Feld_kuehl 0 "no" 1 "yes";
VAL_ 1152 MO5_KliKo_Red 0 "no" 1 "yes";
VAL_ 1152 MO5_UeberlVerb 0 "no_Ueberlauf" 1 "mindestens_einmal_uebergelaufen";
VAL_ 1152 MO5_HLeuchte 0 "no_Warnung" 1 "Vorwarnung";
VAL_ 1152 MO5_PartikelLamp 0 "Lamp_off" 1 "Lamp_on";
VAL_ 1152 MO5_Sta_BKU 0 "iO_oder_not_verbaut" 1 "n_iO";
VAL_ 1152 MO5_TypStartSteu 0 "Startersteuerung_BSG_BCM_KessyD1_ZAS" 1 "Startersteuerung_durch_MSG";
VAL_ 1152 MO5_TDE_Lampe 0 "Lamp_off" 1 "Lamp_on";
VAL_ 1152 MO5_TDE_Text 0 "no_Text" 1 "Textanzeige_nach_ISO";
VAL_ 1152 MO5_DZM_Daempf 0 "normale_Daempfung" 1 "dynamische_Daempfung";
VAL_ 1152 MO5_Interlock 0 "Interlock_not_betaetigt" 1 "Interlock_betaetigt";
VAL_ 1152 MO5_Start 0 "Start_not_zulaessig" 1 "Startfreigabe";
VAL_ 1152 MO5_Anlasser 0 "Anlasser_darf_angesteuert_werden" 1 "Anlasser_ausspuren_Ansteuerung_not_moeglich";
VAL_ 1152 MO5_GRA_Hauptsch 0 "Off" 1 "On";
VAL_ 1152 MO5_Momente 0 "Einfach" 1 "Doppelt";
VAL_ 1152 MO5_Motortext1 0 "no_Text" 1 "Text_1";
VAL_ 1152 MO5_Motortext2 0 "no_Text" 1 "Text_2";
VAL_ 1152 MO5_Motortext3 0 "no_Text" 1 "Text_3";
VAL_ 1152 MO5_Motortext4 0 "no_Text" 1 "Text_4";

VAL_ 1386 ACA_StaACC 6 "ACC_rev_aus" 0 "Hauptschalter_aus" 4 "ACC_im_Hintergrund" 3 "ACC_aktiv" 1 "Reserve" 2 "ACC_passiv" 7 "ACC_irrev_aus" 5 "frei" ;
VAL_ 1386 ACA_ID_StaACC 0 "keine_Anzeige" ;
VAL_ 1386 ACA_Fahrerhinw 1 "Ein" 0 "Aus" ;
VAL_ 1386 ACA_AnzDisplay 1 "Anzeige_erw" 0 "Anzeige_nicht_erw" ;
VAL_ 1386 ACA_Zeitluecke 3 "Zeitluecke3" 10 "Zeitluecke10" 4 "Zeitluecke4" 14 "Zeitluecke14" 11 "Zeitluecke11" 2 "Zeitluecke2" 13 "Zeitluecke13" 9 "Zeitluecke9" 1 "Zeitluecke1" 8 "Zeitluecke8" 5 "Zeitluecke5" 15 "Zeitluecke15" 0 "nicht_definiert" 12 "Zeitluecke12" 6 "Zeitluecke6" 7 "Zeitluecke7" ;
VAL_ 1386 ACA_V_Wunsch 255 "kein_Wert_im_Speicher" ;
VAL_ 1386 ACA_kmh_mph 0 "km_h" 1 "mph" ;
VAL_ 1386 ACA_Akustik1 0 "kein_Gong" 1 "Gong" ;
VAL_ 1386 ACA_Akustik2 0 "kein_Summer" 1 "Summer" ;
VAL_ 1386 ACA_PrioDisp 1 "mittlere_Prio" 3 "keine_Anzeige_Anf" 0 "hohe_Prio" 2 "niedrige_Prio" ;
VAL_ 1386 ACA_gemZeitl 6 "Zeitluecke6" 2 "Zeitluecke2" 7 "Zeitluecke7" 13 "Zeitluecke13" 11 "Zeitluecke11" 4 "Zeitluecke4" 8 "Zeitluecke8" 12 "Zeitluecke12" 10 "Zeitluecke10" 0 "Kein_Objekt_erfasst" 1 "Zeitluecke1" 3 "Zeitluecke3" 9 "Zeitluecke9" 15 "Zeitluecke15" 14 "Zeitluecke14" 5 "Zeitluecke5" ;
VAL_ 1386 ACA_ACC_Verz 0 "ACC_verzoegert_nicht" 1 "ACC_verzoegert" ;
VAL_ 1386 ACA_StaGRA 3 "GRA_aktiv" 4 "GRA_uebertreten" 2 "GRA_passiv" 0 "Hauptschalter_aus" 6 "frei" 7 "GRA_Fehler" 1 "Reserve" 5 "frei" ;
VAL_ 1386 ACA_ID_StaGRA 0 "keine_Anzeige" ;
VAL_ 1386 ACA_Codierung 0 "ACC" 1 "GRA" ;
VAL_ 1386 ACA_Tachokranz 0 "nicht_beleuchtet" 1 "beleuchtet" ;
VAL_ 1386 ACA_Aend_Zeitluecke 1 "Anzeige_angef" 0 "keine_Anzeige" ;

VAL_ 1472 EP1_Fehler_Sta 0 "volle_Funktion" 1 "linke_Seite_fehlerhaft" 2 "rechte_Seite_fehlerhaft" 3 "beide_Seiten_fehlerhaft";
VAL_ 1472 EP1_Sta_EPB 0 "Bremse_geoeffnet" 1 "Bremse_geschlossen";
VAL_ 1472 EP1_Sta_Schalter 0 "volle_Funktion" 1 "Schalter_ausser_Funktion";
VAL_ 1472 EP1_Spannkraft 31 "Fehler";
VAL_ 1472 EP1_Schalterinfo 0 "keine_Fahreranforderung" 1 "Fahreranforderung_oeffnen" 2 "Fahreranforderung_schliessen" 3 "Schalterfehler";
VAL_ 1472 EP1_Sta_NWS 0 "volle_Funktion" 1 "keine_Funktion";
VAL_ 1472 EP1_Fehlereintr 0 "kein_Fehlerspeichereintrag" 1 "Fehlerspeichereintrag";
VAL_ 1472 EP1_Freigabe_Ver 0 "Verzoegerungsanf_nicht_freigegeb" 1 "Verzoegerungsanf_freigegeben";
VAL_ 1472 EP1_AutoHold_zul 0 "Pers_nicht_zulaessig" 1 "Pers_zulaessig";
VAL_ 1472 EP1_AutoHold_aktiv 0 "nein" 1 "ja";
VAL_ 1472 EP1_SleepInd 0 "CAN_wird_benoetigt" 1 "Sleep_bereit";
VAL_ 1472 EP1_Status_Kl_15 0 "Kl_15_aus" 1 "Kl_15_ein";
VAL_ 1472 EP1_Lampe_AutoP 0 "Lampe_aus" 1 "Lampe_ein";
VAL_ 1472 EP1_Bremslicht 0 "Aus" 1 "Ein";
VAL_ 1472 EP1_Warnton1 0 "Aus" 1 "Ein";
VAL_ 1472 EP1_Warnton2 0 "Aus" 1 "Ein";
VAL_ 1472 EP1_AnfShLock 0 "Aus" 1 "Ein";
VAL_ 1472 EPB_Autoholdlampe 0 "Lampe_aus" 1 "Lampe_ein";
VAL_ 1472 EP1_QualNeigWi 0 "gueltiger_Wert" 1 "Ersatz_Init_oder_Fehlerwert";
VAL_ 1472 EP1_KuppModBer 0 "Kuppsensor_aus_Modbereich" 1 "Kupplsensor_im_Modbereich" 2 "Sensorsignal_ungenau" 3 "Sensor_defekt";
VAL_ 1472 EP1_HydrHalten 0 "Fzg_nicht_hydr_geh" 1 "Fzg_hydr_geh";
VAL_ 1472 EP1_Fkt_Lampe 0 "Lampe_aus" 1 "Lampe_ein";
VAL_ 1472 EP1_Warnton 0 "Warnton_aus" 1 "Warnton_an";
VAL_ 1472 EP1_Fehler_BKL 0 "BKL_aus" 1 "BKL_an";
VAL_ 1472 EP1_Fehler_gelb 0 "Lampe_aus" 1 "Lampe_ein";
VAL_ 1472 EP1__Text 0 "kein_Text" 1 "Text_1" 2 "Text_2" 3 "Text_3" 4 "Text_4" 5 "Text_5" 6 "reserviert" 7 "reserviert" 8 "Text_8";
